VERSION ""

NS_ :

BS_:

BU_: Vector__XXX

BO_ 2364624894 ECCP11: 8 Vector__XXX
SG_ EngineCylinder11Timing1Pressure : 0|16@1+ (0.0009765625,0) [0|62.74902344] "MPa" Vector__XXX
SG_ EngineCylinder11Timing2Pressure : 16|16@1+ (0.0009765625,0) [0|62.74902344] "MPa" Vector__XXX
SG_ EngineCylinder11Timing3Pressure : 32|16@1+ (0.0009765625,0) [0|62.74902344] "MPa" Vector__XXX
SG_ EngineCylinder11Timing4Pressure : 48|16@1+ (0.0009765625,0) [0|62.74902344] "MPa" Vector__XXX

BO_ 2364625150 ECCP12: 8 Vector__XXX
SG_ EngineCylinder12Timing1Pressure : 0|16@1+ (0.0009765625,0) [0|62.74902344] "MPa" Vector__XXX
SG_ EngineCylinder12Timing2Pressure : 16|16@1+ (0.0009765625,0) [0|62.74902344] "MPa" Vector__XXX
SG_ EngineCylinder12Timing3Pressure : 32|16@1+ (0.0009765625,0) [0|62.74902344] "MPa" Vector__XXX
SG_ EngineCylinder12Timing4Pressure : 48|16@1+ (0.0009765625,0) [0|62.74902344] "MPa" Vector__XXX

BO_ 2364625406 ECCP13: 8 Vector__XXX
SG_ EngineCylinder13Timing1Pressure : 0|16@1+ (0.0009765625,0) [0|62.74902344] "MPa" Vector__XXX
SG_ EngineCylinder13Timing2Pressure : 16|16@1+ (0.0009765625,0) [0|62.74902344] "MPa" Vector__XXX
SG_ EngineCylinder13Timing3Pressure : 32|16@1+ (0.0009765625,0) [0|62.74902344] "MPa" Vector__XXX
SG_ EngineCylinder13Timing4Pressure : 48|16@1+ (0.0009765625,0) [0|62.74902344] "MPa" Vector__XXX

BO_ 2364625662 ECCP14: 8 Vector__XXX
SG_ EngineCylinder14Timing1Pressure : 0|16@1+ (0.0009765625,0) [0|62.74902344] "MPa" Vector__XXX
SG_ EngineCylinder14Timing2Pressure : 16|16@1+ (0.0009765625,0) [0|62.74902344] "MPa" Vector__XXX
SG_ EngineCylinder14Timing3Pressure : 32|16@1+ (0.0009765625,0) [0|62.74902344] "MPa" Vector__XXX
SG_ EngineCylinder14Timing4Pressure : 48|16@1+ (0.0009765625,0) [0|62.74902344] "MPa" Vector__XXX

BO_ 2364625918 ECCP15: 8 Vector__XXX
SG_ EngineCylinder15Timing1Pressure : 0|16@1+ (0.0009765625,0) [0|62.74902344] "MPa" Vector__XXX
SG_ EngineCylinder15Timing2Pressure : 16|16@1+ (0.0009765625,0) [0|62.74902344] "MPa" Vector__XXX
SG_ EngineCylinder15Timing3Pressure : 32|16@1+ (0.0009765625,0) [0|62.74902344] "MPa" Vector__XXX
SG_ EngineCylinder15Timing4Pressure : 48|16@1+ (0.0009765625,0) [0|62.74902344] "MPa" Vector__XXX

BO_ 2364626174 ECCP16: 8 Vector__XXX
SG_ EngineCylinder16Timing1Pressure : 0|16@1+ (0.0009765625,0) [0|62.74902344] "MPa" Vector__XXX
SG_ EngineCylinder16Timing2Pressure : 16|16@1+ (0.0009765625,0) [0|62.74902344] "MPa" Vector__XXX
SG_ EngineCylinder16Timing3Pressure : 32|16@1+ (0.0009765625,0) [0|62.74902344] "MPa" Vector__XXX
SG_ EngineCylinder16Timing4Pressure : 48|16@1+ (0.0009765625,0) [0|62.74902344] "MPa" Vector__XXX

BO_ 2364626430 ECCP17: 8 Vector__XXX
SG_ EngineCylinder17Timing1Pressure : 0|16@1+ (0.0009765625,0) [0|62.74902344] "MPa" Vector__XXX
SG_ EngineCylinder17Timing2Pressure : 16|16@1+ (0.0009765625,0) [0|62.74902344] "MPa" Vector__XXX
SG_ EngineCylinder17Timing3Pressure : 32|16@1+ (0.0009765625,0) [0|62.74902344] "MPa" Vector__XXX
SG_ EngineCylinder17Timing4Pressure : 48|16@1+ (0.0009765625,0) [0|62.74902344] "MPa" Vector__XXX

BO_ 2364626686 ECCP18: 8 Vector__XXX
SG_ EngineCylinder18Timing1Pressure : 0|16@1+ (0.0009765625,0) [0|62.74902344] "MPa" Vector__XXX
SG_ EngineCylinder18Timing2Pressure : 16|16@1+ (0.0009765625,0) [0|62.74902344] "MPa" Vector__XXX
SG_ EngineCylinder18Timing3Pressure : 32|16@1+ (0.0009765625,0) [0|62.74902344] "MPa" Vector__XXX
SG_ EngineCylinder18Timing4Pressure : 48|16@1+ (0.0009765625,0) [0|62.74902344] "MPa" Vector__XXX

BO_ 2364626942 ECCP19: 8 Vector__XXX
SG_ EngineCylinder19Timing1Pressure : 0|16@1+ (0.0009765625,0) [0|62.74902344] "MPa" Vector__XXX
SG_ EngineCylinder19Timing2Pressure : 16|16@1+ (0.0009765625,0) [0|62.74902344] "MPa" Vector__XXX
SG_ EngineCylinder19Timing3Pressure : 32|16@1+ (0.0009765625,0) [0|62.74902344] "MPa" Vector__XXX
SG_ EngineCylinder19Timing4Pressure : 48|16@1+ (0.0009765625,0) [0|62.74902344] "MPa" Vector__XXX

BO_ 2364627198 ECCP20: 8 Vector__XXX
SG_ EngineCylinder20Timing1Pressure : 0|16@1+ (0.0009765625,0) [0|62.74902344] "MPa" Vector__XXX
SG_ EngineCylinder20Timing2Pressure : 16|16@1+ (0.0009765625,0) [0|62.74902344] "MPa" Vector__XXX
SG_ EngineCylinder20Timing3Pressure : 32|16@1+ (0.0009765625,0) [0|62.74902344] "MPa" Vector__XXX
SG_ EngineCylinder20Timing4Pressure : 48|16@1+ (0.0009765625,0) [0|62.74902344] "MPa" Vector__XXX

BO_ 2364627454 ECCT1: 8 Vector__XXX
SG_ EngCyl1InstntnsStrtCombstnTiming : 0|16@1+ (0.00390625,-125) [-125|125] "deg" Vector__XXX
SG_ EngCyl1InstntnsCntrCombstnTiming : 16|16@1+ (0.00390625,-125) [-125|125] "deg" Vector__XXX
SG_ EngCyl1InstntnsCombstnTmng_Pnt1 : 32|16@1+ (0.00390625,-125) [-125|125] "deg" Vector__XXX
SG_ EngCyl1InstntnsCombstnTmng_Pnt2 : 48|16@1+ (0.00390625,-125) [-125|125] "deg" Vector__XXX

BO_ 2364627710 ECCT2: 8 Vector__XXX
SG_ EngCyl2InstntnsStrtCombstnTiming : 0|16@1+ (0.00390625,-125) [-125|125] "deg" Vector__XXX
SG_ EngCyl2InstntnsCntrCombstnTiming : 16|16@1+ (0.00390625,-125) [-125|125] "deg" Vector__XXX
SG_ EngCyl2InstntnsCombstnTmng_Pnt1 : 32|16@1+ (0.00390625,-125) [-125|125] "deg" Vector__XXX
SG_ EngCyl2InstntnsCombstnTmng_Pnt2 : 48|16@1+ (0.00390625,-125) [-125|125] "deg" Vector__XXX

BO_ 2364627966 ECCT3: 8 Vector__XXX
SG_ EngCyl3InstntnsStrtCombstnTiming : 0|16@1+ (0.00390625,-125) [-125|125] "deg" Vector__XXX
SG_ EngCyl3InstntnsCntrCombstnTiming : 16|16@1+ (0.00390625,-125) [-125|125] "deg" Vector__XXX
SG_ EngCyl3InstntnsCombstnTmng_Pnt1 : 32|16@1+ (0.00390625,-125) [-125|125] "deg" Vector__XXX
SG_ EngCyl3InstntnsCombstnTmng_Pnt2 : 48|16@1+ (0.00390625,-125) [-125|125] "deg" Vector__XXX

BO_ 2364628222 ECCT4: 8 Vector__XXX
SG_ EngCyl4InstntnsStrtCombstnTiming : 0|16@1+ (0.00390625,-125) [-125|125] "deg" Vector__XXX
SG_ EngCyl4InstntnsCntrCombstnTiming : 16|16@1+ (0.00390625,-125) [-125|125] "deg" Vector__XXX
SG_ EngCyl4InstntnsCombstnTmng_Pnt1 : 32|16@1+ (0.00390625,-125) [-125|125] "deg" Vector__XXX
SG_ EngCyl4InstntnsCombstnTmng_Pnt2 : 48|16@1+ (0.00390625,-125) [-125|125] "deg" Vector__XXX

BO_ 2364628478 ECCT5: 8 Vector__XXX
SG_ EngCyl5InstntnsStrtCombstnTiming : 0|16@1+ (0.00390625,-125) [-125|125] "deg" Vector__XXX
SG_ EngCyl5InstntnsCntrCombstnTiming : 16|16@1+ (0.00390625,-125) [-125|125] "deg" Vector__XXX
SG_ EngCyl5InstntnsCombstnTmng_Pnt1 : 32|16@1+ (0.00390625,-125) [-125|125] "deg" Vector__XXX
SG_ EngCyl5InstntnsCombstnTmng_Pnt2 : 48|16@1+ (0.00390625,-125) [-125|125] "deg" Vector__XXX

BO_ 2364628734 ECCT6: 8 Vector__XXX
SG_ EngCyl6InstntnsStrtCombstnTiming : 0|16@1+ (0.00390625,-125) [-125|125] "deg" Vector__XXX
SG_ EngCyl6InstntnsCntrCombstnTiming : 16|16@1+ (0.00390625,-125) [-125|125] "deg" Vector__XXX
SG_ EngCyl6InstntnsCombstnTmng_Pnt1 : 32|16@1+ (0.00390625,-125) [-125|125] "deg" Vector__XXX
SG_ EngCyl6InstntnsCombstnTmng_Pnt2 : 48|16@1+ (0.00390625,-125) [-125|125] "deg" Vector__XXX

BO_ 2364628990 ECCT7: 8 Vector__XXX
SG_ EngCyl7InstntnsStrtCombstnTiming : 0|16@1+ (0.00390625,-125) [-125|125] "deg" Vector__XXX
SG_ EngCyl7InstntnsCntrCombstnTiming : 16|16@1+ (0.00390625,-125) [-125|125] "deg" Vector__XXX
SG_ EngCyl7InstntnsCombstnTmng_Pnt1 : 32|16@1+ (0.00390625,-125) [-125|125] "deg" Vector__XXX
SG_ EngCyl7InstntnsCombstnTmng_Pnt2 : 48|16@1+ (0.00390625,-125) [-125|125] "deg" Vector__XXX

BO_ 2364629246 ECCT8: 8 Vector__XXX
SG_ EngCyl8InstntnsStrtCombstnTiming : 0|16@1+ (0.00390625,-125) [-125|125] "deg" Vector__XXX
SG_ EngCyl8InstntnsCntrCombstnTiming : 16|16@1+ (0.00390625,-125) [-125|125] "deg" Vector__XXX
SG_ EngCyl8InstntnsCombstnTmng_Pnt1 : 32|16@1+ (0.00390625,-125) [-125|125] "deg" Vector__XXX
SG_ EngCyl8InstntnsCombstnTmng_Pnt2 : 48|16@1+ (0.00390625,-125) [-125|125] "deg" Vector__XXX

BO_ 2364629502 ECCT9: 8 Vector__XXX
SG_ EngCyl9InstntnsStrtCombstnTiming : 0|16@1+ (0.00390625,-125) [-125|125] "deg" Vector__XXX
SG_ EngCyl9InstntnsCntrCombstnTiming : 16|16@1+ (0.00390625,-125) [-125|125] "deg" Vector__XXX
SG_ EngCyl9InstntnsCombstnTmng_Pnt1 : 32|16@1+ (0.00390625,-125) [-125|125] "deg" Vector__XXX
SG_ EngCyl9InstntnsCombstnTmng_Pnt2 : 48|16@1+ (0.00390625,-125) [-125|125] "deg" Vector__XXX

BO_ 2364629758 ECCT10: 8 Vector__XXX
SG_ EngCyl10InstntnsStrtCombstnTmng : 0|16@1+ (0.00390625,-125) [-125|125] "deg" Vector__XXX
SG_ EngCyl10InstntnsCntrCombstnTmng : 16|16@1+ (0.00390625,-125) [-125|125] "deg" Vector__XXX
SG_ EngCyl10InstntnsCombstnTmng_Pnt1 : 32|16@1+ (0.00390625,-125) [-125|125] "deg" Vector__XXX
SG_ EngCyl10InstntnsCombstnTmng_Pnt2 : 48|16@1+ (0.00390625,-125) [-125|125] "deg" Vector__XXX

BO_ 2364630014 ECCT11: 8 Vector__XXX
SG_ EngCyl11InstntnsStrtCombstnTmng : 0|16@1+ (0.00390625,-125) [-125|125] "deg" Vector__XXX
SG_ EngCyl11InstntnsCntrCombstnTmng : 16|16@1+ (0.00390625,-125) [-125|125] "deg" Vector__XXX
SG_ EngCyl11InstntnsCombstnTmng_Pnt1 : 32|16@1+ (0.00390625,-125) [-125|125] "deg" Vector__XXX
SG_ EngCyl11InstntnsCombstnTmng_Pnt2 : 48|16@1+ (0.00390625,-125) [-125|125] "deg" Vector__XXX

BO_ 2364630270 ECCT12: 8 Vector__XXX
SG_ EngCyl12InstntnsStrtCombstnTmng : 0|16@1+ (0.00390625,-125) [-125|125] "deg" Vector__XXX
SG_ EngCyl12InstntnsCntrCombstnTmng : 16|16@1+ (0.00390625,-125) [-125|125] "deg" Vector__XXX
SG_ EngCyl12InstntnsCombstnTmng_Pnt1 : 32|16@1+ (0.00390625,-125) [-125|125] "deg" Vector__XXX
SG_ EngCyl12InstntnsCombstnTmng_Pnt2 : 48|16@1+ (0.00390625,-125) [-125|125] "deg" Vector__XXX

BO_ 2364630526 ECCT13: 8 Vector__XXX
SG_ EngCyl13InstntnsStrtCombstnTmng : 0|16@1+ (0.00390625,-125) [-125|125] "deg" Vector__XXX
SG_ EngCyl13InstntnsCntrCombstnTmng : 16|16@1+ (0.00390625,-125) [-125|125] "deg" Vector__XXX
SG_ EngCyl13InstntnsCombstnTmng_Pnt1 : 32|16@1+ (0.00390625,-125) [-125|125] "deg" Vector__XXX
SG_ EngCyl13InstntnsCombstnTmng_Pnt2 : 48|16@1+ (0.00390625,-125) [-125|125] "deg" Vector__XXX

BO_ 2364630782 ECCT14: 8 Vector__XXX
SG_ EngCyl14InstntnsStrtCombstnTmng : 0|16@1+ (0.00390625,-125) [-125|125] "deg" Vector__XXX
SG_ EngCyl14InstntnsCntrCombstnTmng : 16|16@1+ (0.00390625,-125) [-125|125] "deg" Vector__XXX
SG_ EngCyl14InstntnsCombstnTmng_Pnt1 : 32|16@1+ (0.00390625,-125) [-125|125] "deg" Vector__XXX
SG_ EngCyl14InstntnsCombstnTmng_Pnt2 : 48|16@1+ (0.00390625,-125) [-125|125] "deg" Vector__XXX

BO_ 2364631038 ECCT15: 8 Vector__XXX
SG_ EngCyl15InstntnsStrtCombstnTmng : 0|16@1+ (0.00390625,-125) [-125|125] "deg" Vector__XXX
SG_ EngCyl15InstntnsCntrCombstnTmng : 16|16@1+ (0.00390625,-125) [-125|125] "deg" Vector__XXX
SG_ EngCyl15InstntnsCombstnTmng_Pnt1 : 32|16@1+ (0.00390625,-125) [-125|125] "deg" Vector__XXX
SG_ EngCyl15InstntnsCombstnTmng_Pnt2 : 48|16@1+ (0.00390625,-125) [-125|125] "deg" Vector__XXX

BO_ 2364631294 ECCT16: 8 Vector__XXX
SG_ EngCyl16InstntnsStrtCombstnTmng : 0|16@1+ (0.00390625,-125) [-125|125] "deg" Vector__XXX
SG_ EngCyl16InstntnsCntrCombstnTmng : 16|16@1+ (0.00390625,-125) [-125|125] "deg" Vector__XXX
SG_ EngCyl16InstntnsCombstnTmng_Pnt1 : 32|16@1+ (0.00390625,-125) [-125|125] "deg" Vector__XXX
SG_ EngCyl16InstntnsCombstnTmng_Pnt2 : 48|16@1+ (0.00390625,-125) [-125|125] "deg" Vector__XXX

BO_ 2364631550 ECCT17: 8 Vector__XXX
SG_ EngCyl17InstntnsStrtCombstnTmng : 0|16@1+ (0.00390625,-125) [-125|125] "deg" Vector__XXX
SG_ EngCyl17InstntnsCntrCombstnTmng : 16|16@1+ (0.00390625,-125) [-125|125] "deg" Vector__XXX
SG_ EngCyl17InstntnsCombstnTmng_Pnt1 : 32|16@1+ (0.00390625,-125) [-125|125] "deg" Vector__XXX
SG_ EngCyl17InstntnsCombstnTmng_Pnt2 : 48|16@1+ (0.00390625,-125) [-125|125] "deg" Vector__XXX

BO_ 2364631806 ECCT18: 8 Vector__XXX
SG_ EngCyl18InstntnsStrtCombstnTmng : 0|16@1+ (0.00390625,-125) [-125|125] "deg" Vector__XXX
SG_ EngCyl18InstntnsCntrCombstnTmng : 16|16@1+ (0.00390625,-125) [-125|125] "deg" Vector__XXX
SG_ EngCyl18InstntnsCombstnTmng_Pnt1 : 32|16@1+ (0.00390625,-125) [-125|125] "deg" Vector__XXX
SG_ EngCyl18InstntnsCombstnTmng_Pnt2 : 48|16@1+ (0.00390625,-125) [-125|125] "deg" Vector__XXX

BO_ 2364632062 ECCT19: 8 Vector__XXX
SG_ EngCyl19InstntnsStrtCombstnTmng : 0|16@1+ (0.00390625,-125) [-125|125] "deg" Vector__XXX
SG_ EngCyl19InstntnsCntrCombstnTmng : 16|16@1+ (0.00390625,-125) [-125|125] "deg" Vector__XXX
SG_ EngCyl19InstntnsCombstnTmng_Pnt1 : 32|16@1+ (0.00390625,-125) [-125|125] "deg" Vector__XXX
SG_ EngCyl19InstntnsCombstnTmng_Pnt2 : 48|16@1+ (0.00390625,-125) [-125|125] "deg" Vector__XXX

BO_ 2364632318 ECCT20: 8 Vector__XXX
SG_ EngCyl20InstntnsStrtCombstnTmng : 0|16@1+ (0.00390625,-125) [-125|125] "deg" Vector__XXX
SG_ EngCyl20InstntnsCntrCombstnTmng : 16|16@1+ (0.00390625,-125) [-125|125] "deg" Vector__XXX
SG_ EngCyl20InstntnsCombstnTmng_Pnt1 : 32|16@1+ (0.00390625,-125) [-125|125] "deg" Vector__XXX
SG_ EngCyl20InstntnsCombstnTmng_Pnt2 : 48|16@1+ (0.00390625,-125) [-125|125] "deg" Vector__XXX

BO_ 2364632574 EECM1: 8 Vector__XXX
SG_ EngCyl1InstntnsPeakCombPressTmng : 0|16@1+ (0.00390625,-125) [-125|125] "deg" Vector__XXX
SG_ EngCyl1InstntnsIndctMnEffctPress : 16|16@1+ (0.0001220703125,-1) [-1|6.84362793] "MPa" Vector__XXX
SG_ EngCyl1IndctMnEffctPrsCoeffVarnc : 32|8@1+ (0.04,0) [0|10] "%" Vector__XXX
SG_ EngineCylinder1MisfireRate : 40|8@1+ (0.4,0) [0|100] "%" Vector__XXX
SG_ EngineCylinder1Temperature : 48|16@1+ (0.03125,-273) [-273|1734.96875] "deg C" Vector__XXX

BO_ 2364632830 EECM2: 8 Vector__XXX
SG_ EngCyl2InstntnsPeakCombPressTmng : 0|16@1+ (0.00390625,-125) [-125|125] "deg" Vector__XXX
SG_ EngCyl2InstntnsIndctMnEffctPress : 16|16@1+ (0.0001220703125,-1) [-1|6.84362793] "MPa" Vector__XXX
SG_ EngCyl2IndctMnEffctPrsCoeffVarnc : 32|8@1+ (0.04,0) [0|10] "%" Vector__XXX
SG_ EngineCylinder2MisfireRate : 40|8@1+ (0.4,0) [0|100] "%" Vector__XXX
SG_ EngineCylinder2Temperature : 48|16@1+ (0.03125,-273) [-273|1734.96875] "deg C" Vector__XXX

BO_ 2364633086 EECM3: 8 Vector__XXX
SG_ EngCyl3InstntnsPeakCombPressTmng : 0|16@1+ (0.00390625,-125) [-125|125] "deg" Vector__XXX
SG_ EngCyl3InstntnsIndctMnEffctPress : 16|16@1+ (0.0001220703125,-1) [-1|6.84362793] "MPa" Vector__XXX
SG_ EngCyl3IndctMnEffctPrsCoeffVarnc : 32|8@1+ (0.04,0) [0|10] "%" Vector__XXX
SG_ EngineCylinder3MisfireRate : 40|8@1+ (0.4,0) [0|100] "%" Vector__XXX
SG_ EngineCylinder3Temperature : 48|16@1+ (0.03125,-273) [-273|1734.96875] "deg C" Vector__XXX

BO_ 2364633342 EECM4: 8 Vector__XXX
SG_ EngCyl4InstntnsPeakCombPressTmng : 0|16@1+ (0.00390625,-125) [-125|125] "deg" Vector__XXX
SG_ EngCyl4InstntnsIndctMnEffctPress : 16|16@1+ (0.0001220703125,-1) [-1|6.84362793] "MPa" Vector__XXX
SG_ EngCyl4IndctMnEffctPrsCoeffVarnc : 32|8@1+ (0.04,0) [0|10] "%" Vector__XXX
SG_ EngineCylinder4MisfireRate : 40|8@1+ (0.4,0) [0|100] "%" Vector__XXX
SG_ EngineCylinder4Temperature : 48|16@1+ (0.03125,-273) [-273|1734.96875] "deg C" Vector__XXX

BO_ 2364633598 EECM5: 8 Vector__XXX
SG_ EngCyl5InstntnsPeakCombPressTmng : 0|16@1+ (0.00390625,-125) [-125|125] "deg" Vector__XXX
SG_ EngCyl5InstntnsIndctMnEffctPress : 16|16@1+ (0.0001220703125,-1) [-1|6.84362793] "MPa" Vector__XXX
SG_ EngCyl5IndctMnEffctPrsCoeffVarnc : 32|8@1+ (0.04,0) [0|10] "%" Vector__XXX
SG_ EngineCylinder5MisfireRate : 40|8@1+ (0.4,0) [0|100] "%" Vector__XXX
SG_ EngineCylinder5Temperature : 48|16@1+ (0.03125,-273) [-273|1734.96875] "deg C" Vector__XXX

BO_ 2364633854 EECM6: 8 Vector__XXX
SG_ EngCyl6InstntnsPeakCombPressTmng : 0|16@1+ (0.00390625,-125) [-125|125] "deg" Vector__XXX
SG_ EngCyl6InstntnsIndctMnEffctPress : 16|16@1+ (0.0001220703125,-1) [-1|6.84362793] "MPa" Vector__XXX
SG_ EngCyl6IndctMnEffctPrsCoeffVarnc : 32|8@1+ (0.04,0) [0|10] "%" Vector__XXX
SG_ EngineCylinder6MisfireRate : 40|8@1+ (0.4,0) [0|100] "%" Vector__XXX
SG_ EngineCylinder6Temperature : 48|16@1+ (0.03125,-273) [-273|1734.96875] "deg C" Vector__XXX

BO_ 2364634110 EECM7: 8 Vector__XXX
SG_ EngCyl7InstntnsPeakCombPressTmng : 0|16@1+ (0.00390625,-125) [-125|125] "deg" Vector__XXX
SG_ EngCyl7InstntnsIndctMnEffctPress : 16|16@1+ (0.0001220703125,-1) [-1|6.84362793] "MPa" Vector__XXX
SG_ EngCyl7IndctMnEffctPrsCoeffVarnc : 32|8@1+ (0.04,0) [0|10] "%" Vector__XXX
SG_ EngineCylinder7MisfireRate : 40|8@1+ (0.4,0) [0|100] "%" Vector__XXX
SG_ EngineCylinder7Temperature : 48|16@1+ (0.03125,-273) [-273|1734.96875] "deg C" Vector__XXX

BO_ 2364634366 EECM8: 8 Vector__XXX
SG_ EngCyl8InstntnsPeakCombPressTmng : 0|16@1+ (0.00390625,-125) [-125|125] "deg" Vector__XXX
SG_ EngCyl8InstntnsIndctMnEffctPress : 16|16@1+ (0.0001220703125,-1) [-1|6.84362793] "MPa" Vector__XXX
SG_ EngCyl8IndctMnEffctPrsCoeffVarnc : 32|8@1+ (0.04,0) [0|10] "%" Vector__XXX
SG_ EngineCylinder8MisfireRate : 40|8@1+ (0.4,0) [0|100] "%" Vector__XXX
SG_ EngineCylinder8Temperature : 48|16@1+ (0.03125,-273) [-273|1734.96875] "deg C" Vector__XXX

BO_ 2364634622 EECM9: 8 Vector__XXX
SG_ EngCyl9InstntnsPeakCombPressTmng : 0|16@1+ (0.00390625,-125) [-125|125] "deg" Vector__XXX
SG_ EngCyl9InstntnsIndctMnEffctPress : 16|16@1+ (0.0001220703125,-1) [-1|6.84362793] "MPa" Vector__XXX
SG_ EngCyl9IndctMnEffctPrsCoeffVarnc : 32|8@1+ (0.04,0) [0|10] "%" Vector__XXX
SG_ EngineCylinder9MisfireRate : 40|8@1+ (0.4,0) [0|100] "%" Vector__XXX
SG_ EngineCylinder9Temperature : 48|16@1+ (1,-273) [-273|1734.96875] "deg C" Vector__XXX

BO_ 2364634878 EECM10: 8 Vector__XXX
SG_ EngCyl10InstPeakCombPressTmng : 0|16@1+ (0.00390625,-125) [-125|125] "deg" Vector__XXX
SG_ EngCyl10InstIndctMnEffctPress : 16|16@1+ (0.0001220703125,-1) [-1|6.84362793] "MPa" Vector__XXX
SG_ EngCyl10IndctMnEffctPrsCoeffVar : 32|8@1+ (0.04,0) [0|10] "%" Vector__XXX
SG_ EngineCylinder10MisfireRate : 40|8@1+ (0.4,0) [0|100] "%" Vector__XXX
SG_ EngineCylinder10Temperature : 48|16@1+ (0.03125,-273) [-273|1734.96875] "deg C" Vector__XXX

BO_ 2364635134 EECM11: 8 Vector__XXX
SG_ EngCyl11InstPeakCombPressTmng : 0|16@1+ (0.00390625,-125) [-125|125] "deg" Vector__XXX
SG_ EngCyl11InstIndctMnEffctPress : 16|16@1+ (0.0001220703125,-1) [-1|6.84362793] "MPa" Vector__XXX
SG_ EngCyl11IndctMnEffctPrsCoeffVar : 32|8@1+ (0.04,0) [0|10] "%" Vector__XXX
SG_ EngineCylinder11MisfireRate : 40|8@1+ (0.4,0) [0|100] "%" Vector__XXX
SG_ EngineCylinder11Temperature : 48|16@1+ (0.03125,-273) [-273|1734.96875] "deg C" Vector__XXX

BO_ 2364635390 EECM12: 8 Vector__XXX
SG_ EngCyl12InstPeakCombPressTmng : 0|16@1+ (0.00390625,-125) [-125|125] "deg" Vector__XXX
SG_ EngCyl12InstIndctMnEffctPress : 16|16@1+ (0.0001220703125,-1) [-1|6.84362793] "MPa" Vector__XXX
SG_ EngCyl12IndctMnEffctPrsCoeffVar : 32|8@1+ (0.04,0) [0|10] "%" Vector__XXX
SG_ EngineCylinder12MisfireRate : 40|8@1+ (0.4,0) [0|100] "%" Vector__XXX
SG_ EngineCylinder12Temperature : 48|16@1+ (0.03125,-273) [-273|1734.96875] "deg C" Vector__XXX

BO_ 2364635646 EECM13: 8 Vector__XXX
SG_ EngCyl13InstPeakCombPressTmng : 0|16@1+ (0.00390625,-125) [-125|125] "deg" Vector__XXX
SG_ EngCyl13InstIndctMnEffctPress : 16|16@1+ (0.0001220703125,-1) [-1|6.84362793] "MPa" Vector__XXX
SG_ EngCyl13IndctMnEffctPrsCoeffVar : 32|8@1+ (0.04,0) [0|10] "%" Vector__XXX
SG_ EngineCylinder13MisfireRate : 40|8@1+ (0.4,0) [0|100] "%" Vector__XXX
SG_ EngineCylinder13Temperature : 48|16@1+ (0.03125,-273) [-273|1734.96875] "deg C" Vector__XXX

BO_ 2364635902 EECM14: 8 Vector__XXX
SG_ EngCyl14InstPeakCombPressTmng : 0|16@1+ (0.00390625,-125) [-125|125] "deg" Vector__XXX
SG_ EngCyl14InstIndctMnEffctPress : 16|16@1+ (0.0001220703125,-1) [-1|6.84362793] "MPa" Vector__XXX
SG_ EngCyl14IndctMnEffctPrsCoeffVar : 32|8@1+ (0.04,0) [0|10] "%" Vector__XXX
SG_ EngineCylinder14MisfireRate : 40|8@1+ (0.4,0) [0|100] "%" Vector__XXX
SG_ EngineCylinder14Temperature : 48|16@1+ (1,-273) [-273|1734.96875] "deg C" Vector__XXX

BO_ 2364636158 EECM15: 8 Vector__XXX
SG_ EngCyl15InstPeakCombPressTmng : 0|16@1+ (0.00390625,-125) [-125|125] "deg" Vector__XXX
SG_ EngCyl15InstIndctMnEffctPress : 16|16@1+ (0.0001220703125,-1) [-1|6.84362793] "MPa" Vector__XXX
SG_ EngCyl15IndctMnEffctPrsCoeffVar : 32|8@1+ (0.04,0) [0|10] "%" Vector__XXX
SG_ EngineCylinder15MisfireRate : 40|8@1+ (0.4,0) [0|100] "%" Vector__XXX
SG_ EngineCylinder15Temperature : 48|16@1+ (0.03125,-273) [-273|1734.96875] "deg C" Vector__XXX

BO_ 2364636414 EECM16: 8 Vector__XXX
SG_ EngCyl16InstPeakCombPressTmng : 0|16@1+ (0.00390625,-125) [-125|125] "deg" Vector__XXX
SG_ EngCyl16InstIndctMnEffctPress : 16|16@1+ (0.0001220703125,-1) [-1|6.84362793] "MPa" Vector__XXX
SG_ EngCyl16IndctMnEffctPrsCoeffVar : 32|8@1+ (0.04,0) [0|10] "%" Vector__XXX
SG_ EngineCylinder16MisfireRate : 40|8@1+ (0.4,0) [0|100] "%" Vector__XXX
SG_ EngineCylinder16Temperature : 48|16@1+ (0.03125,-273) [-273|1734.96875] "deg C" Vector__XXX

BO_ 2364636670 EECM17: 8 Vector__XXX
SG_ EngCyl17InstPeakCombPressTmng : 0|16@1+ (0.00390625,-125) [-125|125] "deg" Vector__XXX
SG_ EngCyl17InstIndctMnEffctPress : 16|16@1+ (0.0001220703125,-1) [-1|6.84362793] "MPa" Vector__XXX
SG_ EngCyl17IndctMnEffctPrsCoeffVar : 32|8@1+ (0.04,0) [0|10] "%" Vector__XXX
SG_ EngineCylinder17MisfireRate : 40|8@1+ (0.4,0) [0|100] "%" Vector__XXX
SG_ EngineCylinder17Temperature : 48|16@1+ (0.03125,-273) [-273|1734.96875] "deg C" Vector__XXX

BO_ 2364636926 EECM18: 8 Vector__XXX
SG_ EngCyl18InstPeakCombPressTmng : 0|16@1+ (0.00390625,-125) [-125|125] "deg" Vector__XXX
SG_ EngCyl18InstIndctMnEffctPress : 16|16@1+ (0.0001220703125,-1) [-1|6.84362793] "MPa" Vector__XXX
SG_ EngCyl18IndctMnEffctPrsCoeffVar : 32|8@1+ (0.04,0) [0|10] "%" Vector__XXX
SG_ EngineCylinder18MisfireRate : 40|8@1+ (0.4,0) [0|100] "%" Vector__XXX
SG_ EngineCylinder18Temperature : 48|16@1+ (0.03125,-273) [-273|1734.96875] "deg C" Vector__XXX

BO_ 2364637182 EECM19: 8 Vector__XXX
SG_ EngCyl19InstPeakCombPressTmng : 0|16@1+ (0.00390625,-125) [-125|125] "deg" Vector__XXX
SG_ EngCyl19InstIndctMnEffctPress : 16|16@1+ (0.0001220703125,-1) [-1|6.84362793] "MPa" Vector__XXX
SG_ EngCyl19IndctMnEffctPrsCoeffVar : 32|8@1+ (0.04,0) [0|10] "%" Vector__XXX
SG_ EngineCylinder19MisfireRate : 40|8@1+ (0.4,0) [0|100] "%" Vector__XXX
SG_ EngineCylinder19Temperature : 48|16@1+ (0.03125,-273) [-273|1734.96875] "deg C" Vector__XXX

BO_ 2364637438 EECM20: 8 Vector__XXX
SG_ EngCyl20InstPeakCombPressTmng : 0|16@1+ (0.00390625,-125) [-125|125] "deg" Vector__XXX
SG_ EngCyl20InstIndctMnEffctPress : 16|16@1+ (0.0001220703125,-1) [-1|6.84362793] "MPa" Vector__XXX
SG_ EngCyl20IndctMnEffctPrsCoeffVar : 32|8@1+ (0.04,0) [0|10] "%" Vector__XXX
SG_ EngineCylinder20MisfireRate : 40|8@1+ (0.4,0) [0|100] "%" Vector__XXX
SG_ EngineCylinder20Temperature : 48|16@1+ (0.03125,-273) [-273|1734.96875] "deg C" Vector__XXX

BO_ 2364637694 MG1IMF1: 8 Vector__XXX
SG_ MotorGen1InverterModeFdbck1CRC : 0|8@1+ (1,0) [0|255] "" Vector__XXX
SG_ MotorGen1InverterModeFdbck1Cntr : 8|4@1+ (1,0) [0|15] "" Vector__XXX
SG_ MtrGen1InvertCtrlLmtsOverrideMde : 12|4@1+ (1,0) [0|15] "" Vector__XXX
SG_ MotorGen1InvertCtrlSetpointMode : 16|5@1+ (1,0) [0|31] "" Vector__XXX
SG_ MotorGen1InverterHVILStatus : 21|2@1+ (1,0) [0|3] "" Vector__XXX

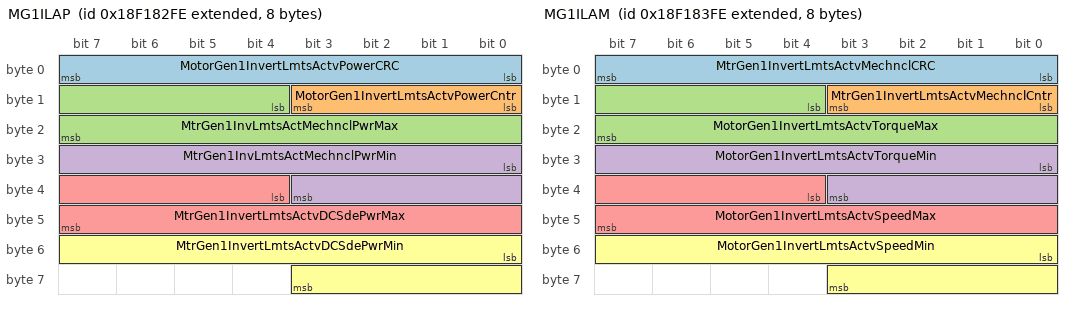
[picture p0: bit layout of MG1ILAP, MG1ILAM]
BO_ 2565964542 MG1ILAP: 8 Vector__XXX
SG_ MotorGen1InvertLmtsActvPowerCRC : 0|8@1+ (1,0) [0|255] "" Vector__XXX
SG_ MotorGen1InvertLmtsActvPowerCntr : 8|4@1+ (1,0) [0|15] "" Vector__XXX
SG_ MtrGen1InvLmtsActMechnclPwrMax : 12|12@1+ (0.0625,-125) [-125|125.9375] "%" Vector__XXX
SG_ MtrGen1InvLmtsActMechnclPwrMin : 24|12@1+ (0.0625,-125) [-125|125.9375] "%" Vector__XXX
SG_ MtrGen1InvertLmtsActvDCSdePwrMax : 36|12@1+ (0.0625,-125) [-125|125.9375] "%" Vector__XXX
SG_ MtrGen1InvertLmtsActvDCSdePwrMin : 48|12@1+ (0.0625,-125) [-125|125.9375] "%" Vector__XXX

BO_ 2565964798 MG1ILAM: 8 Vector__XXX
SG_ MtrGen1InvertLmtsActvMechnclCRC : 0|8@1+ (1,0) [0|255] "" Vector__XXX
SG_ MtrGen1InvertLmtsActvMechnclCntr : 8|4@1+ (1,0) [0|15] "" Vector__XXX
SG_ MotorGen1InvertLmtsActvTorqueMax : 12|12@1+ (0.0625,-125) [-125|125.9375] "%" Vector__XXX
SG_ MotorGen1InvertLmtsActvTorqueMin : 24|12@1+ (0.0625,-125) [-125|125.9375] "%" Vector__XXX
SG_ MotorGen1InvertLmtsActvSpeedMax : 36|12@1+ (0.0625,-125) [-125|125.9375] "%" Vector__XXX
SG_ MotorGen1InvertLmtsActvSpeedMin : 48|12@1+ (0.0625,-125) [-125|125.9375] "%" Vector__XXX

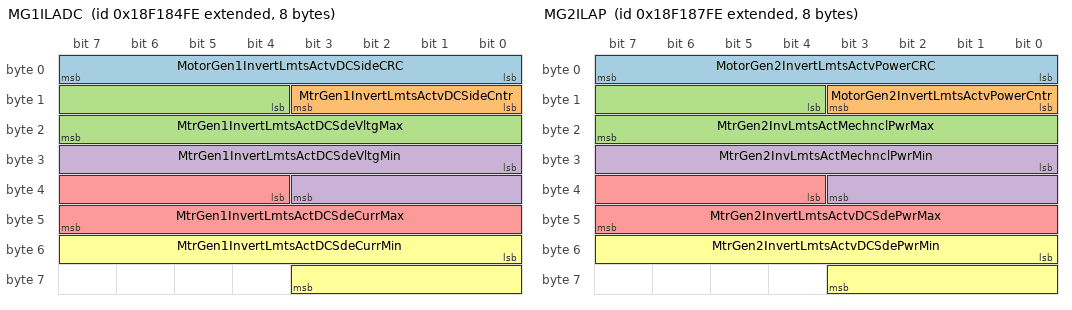
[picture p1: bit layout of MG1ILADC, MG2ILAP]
BO_ 2565965054 MG1ILADC: 8 Vector__XXX
SG_ MotorGen1InvertLmtsActvDCSideCRC : 0|8@1+ (1,0) [0|255] "" Vector__XXX
SG_ MtrGen1InvertLmtsActvDCSideCntr : 8|4@1+ (1,0) [0|15] "" Vector__XXX
SG_ MtrGen1InvertLmtsActDCSdeVltgMax : 12|12@1+ (0.0625,-125) [-125|125.9375] "%" Vector__XXX
SG_ MtrGen1InvertLmtsActDCSdeVltgMin : 24|12@1+ (0.0625,-125) [-125|125.9375] "%" Vector__XXX
SG_ MtrGen1InvertLmtsActDCSdeCurrMax : 36|12@1+ (0.0625,-125) [-125|125.9375] "%" Vector__XXX
SG_ MtrGen1InvertLmtsActDCSdeCurrMin : 48|12@1+ (0.0625,-125) [-125|125.9375] "%" Vector__XXX

BO_ 2565965310 MG1ILV: 8 Vector__XXX
SG_ MtrGen1InvertSwedIgnitionVoltage : 0|16@1+ (0.05,0) [0|3212.75] "V" Vector__XXX
SG_ MtrGen1InvertUnswitchedSLIVltg : 16|16@1+ (0.05,0) [0|3212.75] "V" Vector__XXX

BO_ 2364638974 MG2IMF1: 8 Vector__XXX
SG_ MotorGen2InverterModeFdbck1CRC : 0|8@1+ (1,0) [0|255] "" Vector__XXX
SG_ MotorGen2InverterModeFdbck1Cntr : 8|4@1+ (1,0) [0|15] "" Vector__XXX
SG_ MtrGen2InvertCtrlLmtsOverrideMde : 12|4@1+ (1,0) [0|15] "" Vector__XXX
SG_ MotorGen2InvertCtrlSetpointMode : 16|5@1+ (1,0) [0|31] "" Vector__XXX
SG_ MotorGen2InverterHVILStatus : 21|2@1+ (1,0) [0|3] "" Vector__XXX

BO_ 2565965822 MG2ILAP: 8 Vector__XXX
SG_ MotorGen2InvertLmtsActvPowerCRC : 0|8@1+ (1,0) [0|255] "" Vector__XXX
SG_ MotorGen2InvertLmtsActvPowerCntr : 8|4@1+ (1,0) [0|15] "" Vector__XXX
SG_ MtrGen2InvLmtsActMechnclPwrMax : 12|12@1+ (0.0625,-125) [-125|125.9375] "%" Vector__XXX
SG_ MtrGen2InvLmtsActMechnclPwrMin : 24|12@1+ (0.0625,-125) [-125|125.9375] "%" Vector__XXX
SG_ MtrGen2InvertLmtsActvDCSdePwrMax : 36|12@1+ (0.0625,-125) [-125|125.9375] "%" Vector__XXX
SG_ MtrGen2InvertLmtsActvDCSdePwrMin : 48|12@1+ (0.0625,-125) [-125|125.9375] "%" Vector__XXX

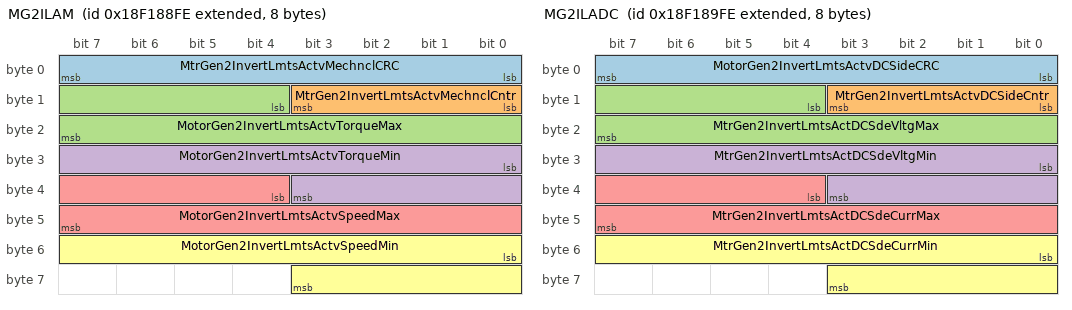
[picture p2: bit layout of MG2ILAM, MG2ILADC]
BO_ 2565966078 MG2ILAM: 8 Vector__XXX
SG_ MtrGen2InvertLmtsActvMechnclCRC : 0|8@1+ (1,0) [0|255] "" Vector__XXX
SG_ MtrGen2InvertLmtsActvMechnclCntr : 8|4@1+ (1,0) [0|15] "" Vector__XXX
SG_ MotorGen2InvertLmtsActvTorqueMax : 12|12@1+ (0.0625,-125) [-125|125.9375] "%" Vector__XXX
SG_ MotorGen2InvertLmtsActvTorqueMin : 24|12@1+ (0.0625,-125) [-125|125.9375] "%" Vector__XXX
SG_ MotorGen2InvertLmtsActvSpeedMax : 36|12@1+ (0.0625,-125) [-125|125.9375] "%" Vector__XXX
SG_ MotorGen2InvertLmtsActvSpeedMin : 48|12@1+ (0.0625,-125) [-125|125.9375] "%" Vector__XXX

BO_ 2565966334 MG2ILADC: 8 Vector__XXX
SG_ MotorGen2InvertLmtsActvDCSideCRC : 0|8@1+ (1,0) [0|255] "" Vector__XXX
SG_ MtrGen2InvertLmtsActvDCSideCntr : 8|4@1+ (1,0) [0|15] "" Vector__XXX
SG_ MtrGen2InvertLmtsActDCSdeVltgMax : 12|12@1+ (0.0625,-125) [-125|125.9375] "%" Vector__XXX
SG_ MtrGen2InvertLmtsActDCSdeVltgMin : 24|12@1+ (0.0625,-125) [-125|125.9375] "%" Vector__XXX
SG_ MtrGen2InvertLmtsActDCSdeCurrMax : 36|12@1+ (0.0625,-125) [-125|125.9375] "%" Vector__XXX
SG_ MtrGen2InvertLmtsActDCSdeCurrMin : 48|12@1+ (0.0625,-125) [-125|125.9375] "%" Vector__XXX

BO_ 2565966590 MG2ILV: 8 Vector__XXX
SG_ MtrGen2InvertSwedIgnitionVoltage : 0|16@1+ (0.05,0) [0|3212.75] "V" Vector__XXX
SG_ MtrGen2InvertUnswitchedSLIVltg : 16|16@1+ (0.05,0) [0|3212.75] "V" Vector__XXX

BO_ 2565966846 MG1IS2: 8 Vector__XXX
SG_ MotorGen1InverterStatus2CRC : 0|8@1+ (1,0) [0|255] "" Vector__XXX
SG_ MotorGen1InverterStatus2Cntr : 8|4@1+ (1,0) [0|15] "" Vector__XXX
SG_ MotorGen1AvailMaximumTorque : 12|12@1+ (0.0625,-125) [-125|125.9375] "%" Vector__XXX
SG_ MotorGen1AvailMinimumTorque : 24|12@1+ (0.0625,-125) [-125|125.9375] "%" Vector__XXX

BO_ 2565967102 MG1IRLA1: 8 Vector__XXX
SG_ MotorGen1InvertRateLmtsActv1CRC : 0|8@1+ (1,0) [0|255] "" Vector__XXX
SG_ MotorGen1InvertRateLmtsActv1Cntr : 8|4@1+ (1,0) [0|15] "" Vector__XXX
SG_ MtrGen1InvRatLmtsActAbsSpdRatLmt : 12|12@1+ (0.25,0) [0|1003.75] "%/s" Vector__XXX
SG_ MtrGen1InvRatLmtsActAbsTrqRatLmt : 24|12@1+ (2,0) [0|8030] "%/s" Vector__XXX

BO_ 2565967358 MG2IS2: 8 Vector__XXX
SG_ MotorGen2InverterStatus2CRC : 0|8@1+ (1,0) [0|255] "" Vector__XXX
SG_ MotorGen2InverterStatus2Cntr : 8|4@1+ (1,0) [0|15] "" Vector__XXX
SG_ MotorGen2AvailMaximumTorque : 12|12@1+ (0.0625,-125) [-125|125.9375] "%" Vector__XXX
SG_ MotorGen2AvailMinimumTorque : 24|12@1+ (0.0625,-125) [-125|125.9375] "%" Vector__XXX

BO_ 2565967614 MG2IRLA1: 8 Vector__XXX
SG_ MotorGen2InvertRateLmtsActv1CRC : 0|8@1+ (1,0) [0|255] "" Vector__XXX
SG_ MotorGen2InvertRateLmtsActv1Cntr : 8|4@1+ (1,0) [0|15] "" Vector__XXX
SG_ MtrGen2InvRatLmtsActAbsSpdRatLmt : 12|12@1+ (0.25,0) [0|1003.75] "%/s" Vector__XXX
SG_ MtrGen2InvRatLmtsActAbsTrqRatLmt : 24|12@1+ (2,0) [0|8030] "%/s" Vector__XXX

BO_ 2297532414 IA: 8 Vector__XXX
SG_ ImpostorPGEventDetectionCounter : 0|8@1+ (1,0) [0|250] "" Vector__XXX
SG_ ImpostorPGSourceAddress : 8|8@1+ (1,0) [0|255] "" Vector__XXX
SG_ ImpostorPGDestinationAddress : 16|8@1+ (1,0) [0|255] "" Vector__XXX
SG_ ImpostorPGN : 24|24@1+ (1,0) [0|16777215] "" Vector__XXX
SG_ TimeSinceLastImposterPGDetected : 48|8@1+ (1,0) [0|250] "min" Vector__XXX

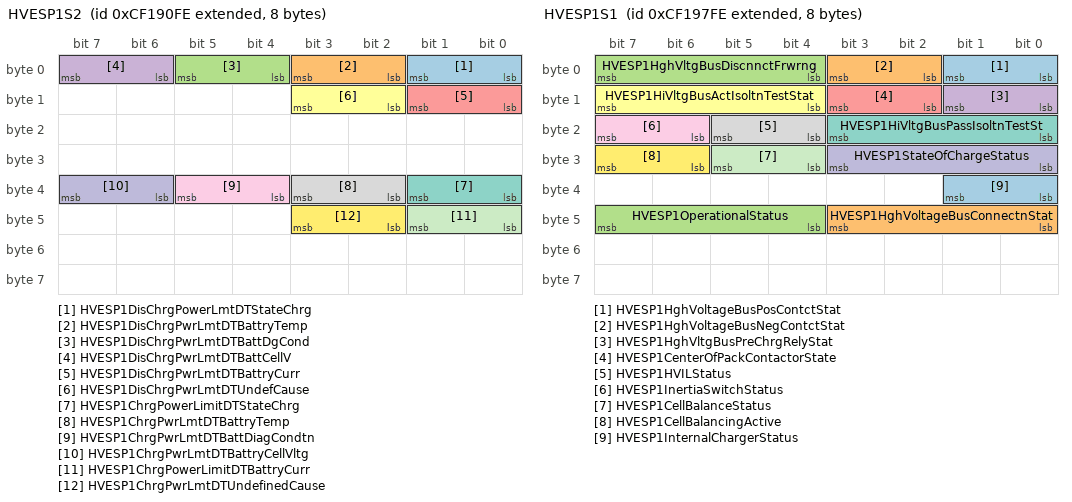
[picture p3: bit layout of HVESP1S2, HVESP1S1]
BO_ 2364641534 HVESP1S2: 8 Vector__XXX
SG_ HVESP1DisChrgPowerLmtDTStateChrg : 0|2@1+ (1,0) [0|3] "" Vector__XXX
SG_ HVESP1DisChrgPwrLmtDTBattryTemp : 2|2@1+ (1,0) [0|3] "" Vector__XXX
SG_ HVESP1DisChrgPwrLmtDTBattDgCond : 4|2@1+ (1,0) [0|3] "" Vector__XXX
SG_ HVESP1DisChrgPwrLmtDTBattCellV : 6|2@1+ (1,0) [0|3] "" Vector__XXX
SG_ HVESP1DisChrgPwrLmtDTBattryCurr : 8|2@1+ (1,0) [0|3] "" Vector__XXX
SG_ HVESP1DisChrgPwrLmtDTUndefCause : 10|2@1+ (1,0) [0|3] "" Vector__XXX
SG_ HVESP1ChrgPowerLimitDTStateChrg : 32|2@1+ (1,0) [0|3] "" Vector__XXX
SG_ HVESP1ChrgPwrLmtDTBattryTemp : 34|2@1+ (1,0) [0|3] "" Vector__XXX
SG_ HVESP1ChrgPwrLmtDTBattDiagCondtn : 36|2@1+ (1,0) [0|3] "" Vector__XXX
SG_ HVESP1ChrgPwrLmtDTBattryCellVltg : 38|2@1+ (1,0) [0|3] "" Vector__XXX
SG_ HVESP1ChrgPowerLimitDTBattryCurr : 40|2@1+ (1,0) [0|3] "" Vector__XXX
SG_ HVESP1ChrgPwrLmtDTUndefinedCause : 42|2@1+ (1,0) [0|3] "" Vector__XXX

BO_ 2364641790 HVESP1D1: 8 Vector__XXX
SG_ HVESP1AvailableDischargePower : 0|16@1+ (0.05,0) [0|3212.75] "kW" Vector__XXX
SG_ HVESP1AvailableChargePower : 16|16@1+ (0.05,0) [0|3212.75] "kW" Vector__XXX
SG_ HVESP1VoltageLevel : 32|16@1+ (0.05,0) [0|3212.75] "V" Vector__XXX
SG_ HVESP1Current : 48|16@1+ (0.05,-1600) [-1600|1612.75] "A" Vector__XXX

BO_ 2364642046 HVESP1D2: 8 Vector__XXX
SG_ HVESP1FastUpdateStateOfCharge : 0|16@1+ (0.0015625,0) [0|100.3984375] "%" Vector__XXX
SG_ HVESP1HighestCellVoltage : 16|16@1+ (0.001,0) [0|64.255] "V" Vector__XXX
SG_ HVESP1LowestCellVoltage : 32|16@1+ (0.001,0) [0|64.255] "V" Vector__XXX
SG_ HVESP1CellVoltageDiffStatus : 48|4@1+ (1,0) [0|15] "" Vector__XXX

BO_ 2364642302 HVESP1D3: 8 Vector__XXX
SG_ HVESP1HighestCellTemperature : 0|16@1+ (0.03125,-273) [-273|1734.96875] "deg C" Vector__XXX
SG_ HVESP1LowestCellTemperature : 16|16@1+ (0.03125,-273) [-273|1734.96875] "deg C" Vector__XXX
SG_ HVESP1AverageCellTemperature : 32|16@1+ (0.03125,-273) [-273|1734.96875] "deg C" Vector__XXX
SG_ HVESP1CellTemperatureDiffStatus : 48|2@1+ (1,0) [0|3] "" Vector__XXX

BO_ 2364642558 HVESP1D4: 8 Vector__XXX
SG_ HVESP1DischargeCapacity : 0|16@1+ (0.01,0) [0|642.55] "Ah" Vector__XXX
SG_ HVESP1ChargeCapacity : 16|16@1+ (0.01,0) [0|642.55] "Ah" Vector__XXX
SG_ HVESP1CellBalancingCount : 32|16@1+ (1,0) [0|64255] "" Vector__XXX

BO_ 2364642814 HVESP1D5: 8 Vector__XXX
SG_ HVESP1DischargeCurrentLimit : 0|16@1+ (0.05,-1600) [-1600|1612.75] "A" Vector__XXX
SG_ HVESP1ChargeCurrentLimit : 16|16@1+ (0.05,-1600) [-1600|1612.75] "A" Vector__XXX
SG_ HVESP1LowestCellStateOfCharge : 32|16@1+ (0.0015625,0) [0|100.3984375] "%" Vector__XXX
SG_ HVESP1HighestCellStateOfCharge : 48|16@1+ (0.0015625,0) [0|100.3984375] "%" Vector__XXX

BO_ 2364643070 HVESP1D6: 8 Vector__XXX
SG_ HVESP1BusVoltage : 0|16@1+ (0.05,0) [0|3212.75] "V" Vector__XXX
SG_ HVESP1IgnitionVoltage : 16|16@1+ (0.01,0) [0|642.55] "V" Vector__XXX
SG_ HVESP1IntakeCoolantTemperature : 32|8@1+ (1,-40) [-40|210] "deg C" Vector__XXX
SG_ HVESP1OutletCoolantTemperature : 40|8@1+ (1,-40) [-40|210] "deg C" Vector__XXX
SG_ HVESP1ElectronicsTemperature : 48|8@1+ (1,-40) [-40|210] "deg C" Vector__XXX
SG_ HVESP1Temperature : 56|8@1+ (1,-40) [-40|210] "deg C" Vector__XXX

BO_ 2364643326 HVESP1S1: 8 Vector__XXX
SG_ HVESP1HghVoltageBusPosContctStat : 0|2@1+ (1,0) [0|3] "" Vector__XXX
SG_ HVESP1HghVoltageBusNegContctStat : 2|2@1+ (1,0) [0|3] "" Vector__XXX
SG_ HVESP1HghVltgBusDiscnnctFrwrng : 4|4@1+ (1,0) [0|15] "" Vector__XXX
SG_ HVESP1HghVltgBusPreChrgRelyStat : 8|2@1+ (1,0) [0|3] "" Vector__XXX
SG_ HVESP1CenterOfPackContactorState : 10|2@1+ (1,0) [0|3] "" Vector__XXX
SG_ HVESP1HiVltgBusActIsoltnTestStat : 12|4@1+ (1,0) [0|15] "" Vector__XXX
SG_ HVESP1HiVltgBusPassIsoltnTestSt : 16|4@1+ (1,0) [0|15] "" Vector__XXX
SG_ HVESP1HVILStatus : 20|2@1+ (1,0) [0|3] "" Vector__XXX
SG_ HVESP1InertiaSwitchStatus : 22|2@1+ (1,0) [0|3] "" Vector__XXX
SG_ HVESP1StateOfChargeStatus : 24|4@1+ (1,0) [0|15] "" Vector__XXX
SG_ HVESP1CellBalanceStatus : 28|2@1+ (1,0) [0|3] "" Vector__XXX
SG_ HVESP1CellBalancingActive : 30|2@1+ (1,0) [0|3] "" Vector__XXX
SG_ HVESP1InternalChargerStatus : 32|2@1+ (1,0) [0|3] "" Vector__XXX
SG_ HVESP1HghVoltageBusConnectnStat : 40|4@1+ (1,0) [0|15] "" Vector__XXX
SG_ HVESP1OperationalStatus : 44|4@1+ (1,0) [0|15] "" Vector__XXX

BO_ 2364643582 HVESP1D7: 8 Vector__XXX
SG_ HVESP1DischargeEnergyCapacity : 0|24@1+ (0.001,0) [0|16449.535] "kWh" Vector__XXX
SG_ HVESP1ChargeEnergyCapacity : 24|24@1+ (0.001,0) [0|16449.535] "kWh" Vector__XXX
SG_ HVESP1MaximumChargeVoltageLimit : 48|16@1+ (0.05,0) [0|3212.75] "V" Vector__XXX

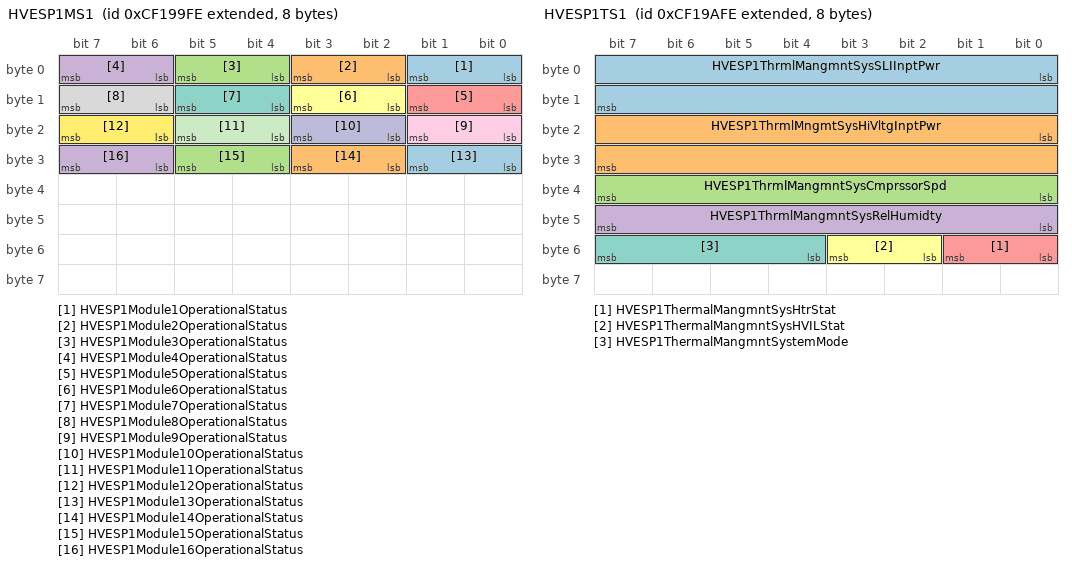
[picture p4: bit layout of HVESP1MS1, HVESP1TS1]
BO_ 2364643838 HVESP1MS1: 8 Vector__XXX
SG_ HVESP1Module1OperationalStatus : 0|2@1+ (1,0) [0|3] "" Vector__XXX
SG_ HVESP1Module2OperationalStatus : 2|2@1+ (1,0) [0|3] "" Vector__XXX
SG_ HVESP1Module3OperationalStatus : 4|2@1+ (1,0) [0|3] "" Vector__XXX
SG_ HVESP1Module4OperationalStatus : 6|2@1+ (1,0) [0|3] "" Vector__XXX
SG_ HVESP1Module5OperationalStatus : 8|2@1+ (1,0) [0|3] "" Vector__XXX
SG_ HVESP1Module6OperationalStatus : 10|2@1+ (1,0) [0|3] "" Vector__XXX
SG_ HVESP1Module7OperationalStatus : 12|2@1+ (1,0) [0|3] "" Vector__XXX
SG_ HVESP1Module8OperationalStatus : 14|2@1+ (1,0) [0|3] "" Vector__XXX
SG_ HVESP1Module9OperationalStatus : 16|2@1+ (1,0) [0|3] "" Vector__XXX
SG_ HVESP1Module10OperationalStatus : 18|2@1+ (1,0) [0|3] "" Vector__XXX
SG_ HVESP1Module11OperationalStatus : 20|2@1+ (1,0) [0|3] "" Vector__XXX
SG_ HVESP1Module12OperationalStatus : 22|2@1+ (1,0) [0|3] "" Vector__XXX
SG_ HVESP1Module13OperationalStatus : 24|2@1+ (1,0) [0|3] "" Vector__XXX
SG_ HVESP1Module14OperationalStatus : 26|2@1+ (1,0) [0|3] "" Vector__XXX
SG_ HVESP1Module15OperationalStatus : 28|2@1+ (1,0) [0|3] "" Vector__XXX
SG_ HVESP1Module16OperationalStatus : 30|2@1+ (1,0) [0|3] "" Vector__XXX

BO_ 2364644094 HVESP1TS1: 8 Vector__XXX
SG_ HVESP1ThrmlMangmntSysSLIInptPwr : 0|16@1+ (0.5,0) [0|32127.5] "W" Vector__XXX
SG_ HVESP1ThrmlMngmtSysHiVltgInptPwr : 16|16@1+ (0.5,0) [0|32127.5] "W" Vector__XXX
SG_ HVESP1ThrmlMangmntSysCmprssorSpd : 32|8@1+ (32,0) [0|8000] "rpm" Vector__XXX
SG_ HVESP1ThrmlMangmntSysRelHumidty : 40|8@1+ (0.4,0) [0|100] "%" Vector__XXX
SG_ HVESP1ThermalMangmntSysHtrStat : 48|2@1+ (1,0) [0|3] "" Vector__XXX
SG_ HVESP1ThermalMangmntSysHVILStat : 50|2@1+ (1,0) [0|3] "" Vector__XXX
SG_ HVESP1ThermalMangmntSystemMode : 52|4@1+ (1,0) [0|15] "" Vector__XXX

BO_ 2364644350 HVESP1D8: 8 Vector__XXX
SG_ HVESP1HghestCellVoltageMdulNo : 0|8@1+ (1,0) [0|250] "" Vector__XXX
SG_ HVESP1HghestCellVoltageCellNo : 8|8@1+ (1,0) [0|250] "" Vector__XXX
SG_ HVESP1LowestCellVoltageMdulNo : 16|8@1+ (1,0) [0|250] "" Vector__XXX
SG_ HVESP1LowestCellVoltageCellNo : 24|8@1+ (1,0) [0|250] "" Vector__XXX
SG_ HVESP1AverageCellVoltage : 32|16@1+ (0.001,0) [0|64.255] "V" Vector__XXX

BO_ 2364644606 HVESP1D9: 8 Vector__XXX
SG_ HVESP1HghestCellTempMdulNo : 0|8@1+ (1,0) [0|250] "" Vector__XXX
SG_ HVESP1HghestCellTempCellNo : 8|8@1+ (1,0) [0|250] "" Vector__XXX
SG_ HVESP1LowestCellTempMdulNo : 16|8@1+ (1,0) [0|250] "" Vector__XXX
SG_ HVESP1LowestCellTempCellNo : 24|8@1+ (1,0) [0|250] "" Vector__XXX

BO_ 2364644862 HVESP1D10: 8 Vector__XXX
SG_ HVESP1HghestCellStateChrgMdulNo : 0|8@1+ (1,0) [0|250] "" Vector__XXX
SG_ HVESP1HghestCellStateChrgCellNo : 8|8@1+ (1,0) [0|250] "" Vector__XXX
SG_ HVESP1LowestCellStateChrgMdulNo : 16|8@1+ (1,0) [0|250] "" Vector__XXX
SG_ HVESP1LowestCellStateChrgCellNo : 24|8@1+ (1,0) [0|250] "" Vector__XXX
SG_ HVESP1HiVltgBusActIsoltnTestRess : 32|16@1+ (0.1,0) [0|6425.5] "ohm/V" Vector__XXX
SG_ HVESP1HiVltgBusPassIsoltnTtRess : 48|16@1+ (0.1,0) [0|6425.5] "ohm/V" Vector__XXX

BO_ 2364645118 HVESP1D11: 8 Vector__XXX
SG_ HVESP1BusVltgNegToChssGrndVltg : 0|16@1+ (0.05,0) [0|3212.75] "V" Vector__XXX
SG_ HVESP1VltgLvlNegToChssGrndVltg : 16|16@1+ (0.05,0) [0|3212.75] "V" Vector__XXX

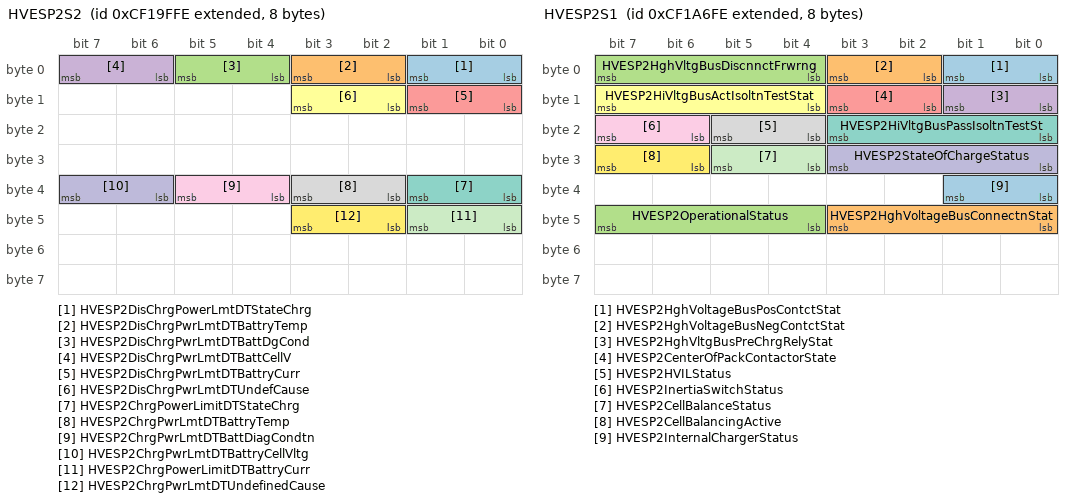
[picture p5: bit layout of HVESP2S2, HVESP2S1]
BO_ 2364645374 HVESP2S2: 8 Vector__XXX
SG_ HVESP2DisChrgPowerLmtDTStateChrg : 0|2@1+ (1,0) [0|3] "" Vector__XXX
SG_ HVESP2DisChrgPwrLmtDTBattryTemp : 2|2@1+ (1,0) [0|3] "" Vector__XXX
SG_ HVESP2DisChrgPwrLmtDTBattDgCond : 4|2@1+ (1,0) [0|3] "" Vector__XXX
SG_ HVESP2DisChrgPwrLmtDTBattCellV : 6|2@1+ (1,0) [0|3] "" Vector__XXX
SG_ HVESP2DisChrgPwrLmtDTBattryCurr : 8|2@1+ (1,0) [0|3] "" Vector__XXX
SG_ HVESP2DisChrgPwrLmtDTUndefCause : 10|2@1+ (1,0) [0|3] "" Vector__XXX
SG_ HVESP2ChrgPowerLimitDTStateChrg : 32|2@1+ (1,0) [0|3] "" Vector__XXX
SG_ HVESP2ChrgPwrLmtDTBattryTemp : 34|2@1+ (1,0) [0|3] "" Vector__XXX
SG_ HVESP2ChrgPwrLmtDTBattDiagCondtn : 36|2@1+ (1,0) [0|3] "" Vector__XXX
SG_ HVESP2ChrgPwrLmtDTBattryCellVltg : 38|2@1+ (1,0) [0|3] "" Vector__XXX
SG_ HVESP2ChrgPowerLimitDTBattryCurr : 40|2@1+ (1,0) [0|3] "" Vector__XXX
SG_ HVESP2ChrgPwrLmtDTUndefinedCause : 42|2@1+ (1,0) [0|3] "" Vector__XXX

BO_ 2364645630 HVESP2D1: 8 Vector__XXX
SG_ HVESP2AvailableDischargePower : 0|16@1+ (0.05,0) [0|3212.75] "kW" Vector__XXX
SG_ HVESP2AvailableChargePower : 16|16@1+ (0.05,0) [0|3212.75] "kW" Vector__XXX
SG_ HVESP2VoltageLevel : 32|16@1+ (0.05,0) [0|3212.75] "V" Vector__XXX
SG_ HVESP2Current : 48|16@1+ (0.05,-1600) [-1600|1612.75] "A" Vector__XXX

BO_ 2364645886 HVESP2D2: 8 Vector__XXX
SG_ HVESP2FastUpdateStateOfCharge : 0|16@1+ (0.0015625,0) [0|100.3984375] "%" Vector__XXX
SG_ HVESP2HighestCellVoltage : 16|16@1+ (0.001,0) [0|64.255] "V" Vector__XXX
SG_ HVESP2LowestCellVoltage : 32|16@1+ (0.001,0) [0|64.255] "V" Vector__XXX
SG_ HVESP2CellVoltageDiffStatus : 48|4@1+ (1,0) [0|15] "" Vector__XXX

BO_ 2364646142 HVESP2D3: 8 Vector__XXX
SG_ HVESP2HighestCellTemperature : 0|16@1+ (0.03125,-273) [-273|1734.96875] "deg C" Vector__XXX
SG_ HVESP2LowestCellTemperature : 16|16@1+ (0.03125,-273) [-273|1734.96875] "deg C" Vector__XXX
SG_ HVESP2AverageCellTemperature : 32|16@1+ (0.03125,-273) [-273|1734.96875] "deg C" Vector__XXX
SG_ HVESP2CellTemperatureDiffStatus : 48|2@1+ (1,0) [0|3] "" Vector__XXX

BO_ 2364646398 HVESP2D4: 8 Vector__XXX
SG_ HVESP2DischargeCapacity : 0|16@1+ (0.01,0) [0|642.55] "Ah" Vector__XXX
SG_ HVESP2ChargeCapacity : 16|16@1+ (0.01,0) [0|642.55] "Ah" Vector__XXX
SG_ HVESP2CellBalancingCount : 32|16@1+ (1,0) [0|64255] "" Vector__XXX

BO_ 2364646654 HVESP2D5: 8 Vector__XXX
SG_ HVESP2DischargeCurrentLimit : 0|16@1+ (0.05,-1600) [-1600|1612.75] "A" Vector__XXX
SG_ HVESP2ChargeCurrentLimit : 16|16@1+ (0.05,-1600) [-1600|1612.75] "A" Vector__XXX
SG_ HVESP2LowestCellStateOfCharge : 32|16@1+ (0.0015625,0) [0|100.3984375] "%" Vector__XXX
SG_ HVESP2HighestCellStateOfCharge : 48|16@1+ (0.0015625,0) [0|100.3984375] "%" Vector__XXX

BO_ 2364646910 HVESP2D6: 8 Vector__XXX
SG_ HVESP2BusVoltage : 0|16@1+ (0.05,0) [0|3212.75] "V" Vector__XXX
SG_ HVESP2IgnitionVoltage : 16|16@1+ (0.01,0) [0|642.55] "V" Vector__XXX
SG_ HVESP2IntakeCoolantTemperature : 32|8@1+ (1,-40) [-40|210] "deg C" Vector__XXX
SG_ HVESP2OutletCoolantTemperature : 40|8@1+ (1,-40) [-40|210] "deg C" Vector__XXX
SG_ HVESP2ElectronicsTemperature : 48|8@1+ (1,-40) [-40|210] "deg C" Vector__XXX
SG_ HVESP2Temperature : 56|8@1+ (1,-40) [-40|210] "deg C" Vector__XXX

BO_ 2364647166 HVESP2S1: 8 Vector__XXX
SG_ HVESP2HghVoltageBusPosContctStat : 0|2@1+ (1,0) [0|3] "" Vector__XXX
SG_ HVESP2HghVoltageBusNegContctStat : 2|2@1+ (1,0) [0|3] "" Vector__XXX
SG_ HVESP2HghVltgBusDiscnnctFrwrng : 4|4@1+ (1,0) [0|15] "" Vector__XXX
SG_ HVESP2HghVltgBusPreChrgRelyStat : 8|2@1+ (1,0) [0|3] "" Vector__XXX
SG_ HVESP2CenterOfPackContactorState : 10|2@1+ (1,0) [0|3] "" Vector__XXX
SG_ HVESP2HiVltgBusActIsoltnTestStat : 12|4@1+ (1,0) [0|15] "" Vector__XXX
SG_ HVESP2HiVltgBusPassIsoltnTestSt : 16|4@1+ (1,0) [0|15] "" Vector__XXX
SG_ HVESP2HVILStatus : 20|2@1+ (1,0) [0|3] "" Vector__XXX
SG_ HVESP2InertiaSwitchStatus : 22|2@1+ (1,0) [0|3] "" Vector__XXX
SG_ HVESP2StateOfChargeStatus : 24|4@1+ (1,0) [0|15] "" Vector__XXX
SG_ HVESP2CellBalanceStatus : 28|2@1+ (1,0) [0|3] "" Vector__XXX
SG_ HVESP2CellBalancingActive : 30|2@1+ (1,0) [0|3] "" Vector__XXX
SG_ HVESP2InternalChargerStatus : 32|2@1+ (1,0) [0|3] "" Vector__XXX
SG_ HVESP2HghVoltageBusConnectnStat : 40|4@1+ (1,0) [0|15] "" Vector__XXX
SG_ HVESP2OperationalStatus : 44|4@1+ (1,0) [0|15] "" Vector__XXX

BO_ 2364647422 HVESP2D7: 8 Vector__XXX
SG_ HVESP2DischargeEnergyCapacity : 0|24@1+ (0.001,0) [0|16449.535] "kWh" Vector__XXX
SG_ HVESP2ChargeEnergyCapacity : 24|24@1+ (0.001,0) [0|16449.535] "kWh" Vector__XXX
SG_ HVESP2MaximumChargeVoltageLimit : 48|16@1+ (0.05,0) [0|3212.75] "V" Vector__XXX

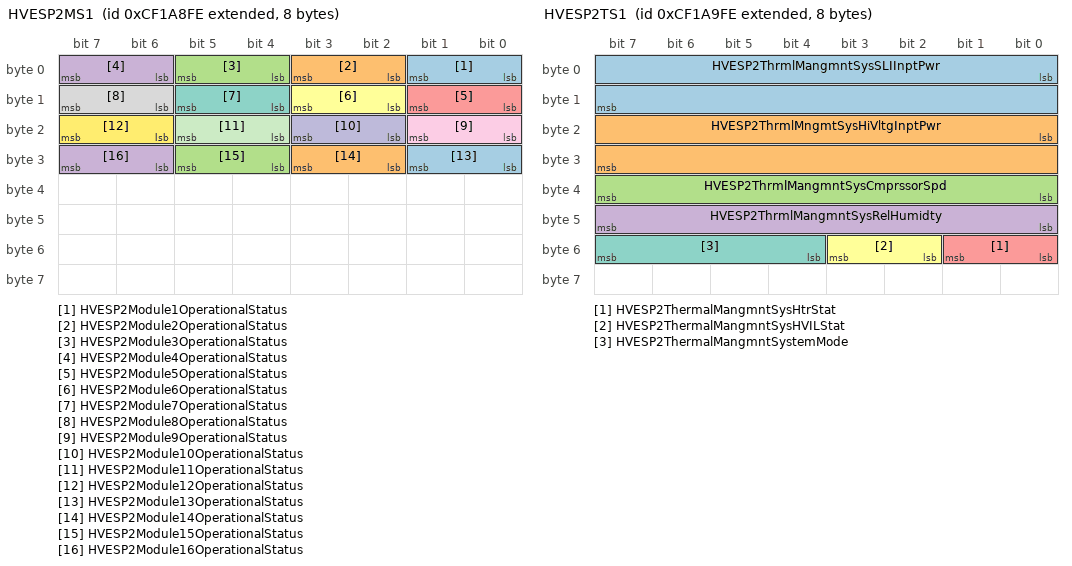
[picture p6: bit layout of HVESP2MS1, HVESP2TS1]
BO_ 2364647678 HVESP2MS1: 8 Vector__XXX
SG_ HVESP2Module1OperationalStatus : 0|2@1+ (1,0) [0|3] "" Vector__XXX
SG_ HVESP2Module2OperationalStatus : 2|2@1+ (1,0) [0|3] "" Vector__XXX
SG_ HVESP2Module3OperationalStatus : 4|2@1+ (1,0) [0|3] "" Vector__XXX
SG_ HVESP2Module4OperationalStatus : 6|2@1+ (1,0) [0|3] "" Vector__XXX
SG_ HVESP2Module5OperationalStatus : 8|2@1+ (1,0) [0|3] "" Vector__XXX
SG_ HVESP2Module6OperationalStatus : 10|2@1+ (1,0) [0|3] "" Vector__XXX
SG_ HVESP2Module7OperationalStatus : 12|2@1+ (1,0) [0|3] "" Vector__XXX
SG_ HVESP2Module8OperationalStatus : 14|2@1+ (1,0) [0|3] "" Vector__XXX
SG_ HVESP2Module9OperationalStatus : 16|2@1+ (1,0) [0|3] "" Vector__XXX
SG_ HVESP2Module10OperationalStatus : 18|2@1+ (1,0) [0|3] "" Vector__XXX
SG_ HVESP2Module11OperationalStatus : 20|2@1+ (1,0) [0|3] "" Vector__XXX
SG_ HVESP2Module12OperationalStatus : 22|2@1+ (1,0) [0|3] "" Vector__XXX
SG_ HVESP2Module13OperationalStatus : 24|2@1+ (1,0) [0|3] "" Vector__XXX
SG_ HVESP2Module14OperationalStatus : 26|2@1+ (1,0) [0|3] "" Vector__XXX
SG_ HVESP2Module15OperationalStatus : 28|2@1+ (1,0) [0|3] "" Vector__XXX
SG_ HVESP2Module16OperationalStatus : 30|2@1+ (1,0) [0|3] "" Vector__XXX

BO_ 2364647934 HVESP2TS1: 8 Vector__XXX
SG_ HVESP2ThrmlMangmntSysSLIInptPwr : 0|16@1+ (0.5,0) [0|32127.5] "W" Vector__XXX
SG_ HVESP2ThrmlMngmtSysHiVltgInptPwr : 16|16@1+ (0.5,0) [0|32127.5] "W" Vector__XXX
SG_ HVESP2ThrmlMangmntSysCmprssorSpd : 32|8@1+ (32,0) [0|8000] "rpm" Vector__XXX
SG_ HVESP2ThrmlMangmntSysRelHumidty : 40|8@1+ (0.4,0) [0|100] "%" Vector__XXX
SG_ HVESP2ThermalMangmntSysHtrStat : 48|2@1+ (1,0) [0|3] "" Vector__XXX
SG_ HVESP2ThermalMangmntSysHVILStat : 50|2@1+ (1,0) [0|3] "" Vector__XXX
SG_ HVESP2ThermalMangmntSystemMode : 52|4@1+ (1,0) [0|15] "" Vector__XXX

BO_ 2364648190 HVESP2D8: 8 Vector__XXX
SG_ HVESP2HghestCellVoltageMdulNo : 0|8@1+ (1,0) [0|250] "" Vector__XXX
SG_ HVESP2HghestCellVoltageCellNo : 8|8@1+ (1,0) [0|250] "" Vector__XXX
SG_ HVESP2LowestCellVoltageMdulNo : 16|8@1+ (1,0) [0|250] "" Vector__XXX
SG_ HVESP2LowestCellVoltageCellNo : 24|8@1+ (1,0) [0|250] "" Vector__XXX
SG_ HVESP2AverageCellVoltage : 32|16@1+ (0.001,0) [0|64.255] "V" Vector__XXX

BO_ 2364648446 HVESP2D9: 8 Vector__XXX
SG_ HVESP2HghestCellTempMdulNo : 0|8@1+ (1,0) [0|250] "" Vector__XXX
SG_ HVESP2HghestCellTempCellNo : 8|8@1+ (1,0) [0|250] "" Vector__XXX
SG_ HVESP2LowestCellTempMdulNo : 16|8@1+ (1,0) [0|250] "" Vector__XXX
SG_ HVESP2LowestCellTempCellNo : 24|8@1+ (1,0) [0|250] "" Vector__XXX

BO_ 2364648702 HVESP2D10: 8 Vector__XXX
SG_ HVESP2HghestCellStateChrgMdulNo : 0|8@1+ (1,0) [0|250] "" Vector__XXX
SG_ HVESP2HghestCellStateChrgCellNo : 8|8@1+ (1,0) [0|250] "" Vector__XXX
SG_ HVESP2LowestCellStateChrgMdulNo : 16|8@1+ (1,0) [0|250] "" Vector__XXX
SG_ HVESP2LowestCellStateChrgCellNo : 24|8@1+ (1,0) [0|250] "" Vector__XXX
SG_ HVESP2HiVltgBusActIsoltnTestRess : 32|16@1+ (0.1,0) [0|6425.5] "ohm/V" Vector__XXX
SG_ HVESP2HiVltgBusPassIsoltnTtRess : 48|16@1+ (0.1,0) [0|6425.5] "ohm/V" Vector__XXX

BO_ 2364648958 HVESP2D11: 8 Vector__XXX
SG_ HVESP2BusVltgNegToChssGrndVltg : 0|16@1+ (0.05,0) [0|3212.75] "V" Vector__XXX
SG_ HVESP2VltgLvlNegToChssGrndVltg : 16|16@1+ (0.05,0) [0|3212.75] "V" Vector__XXX

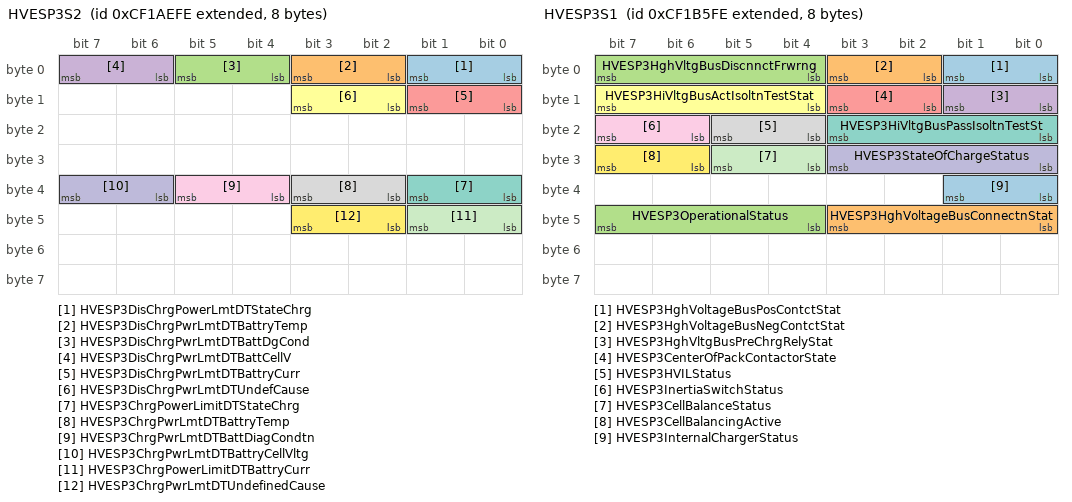
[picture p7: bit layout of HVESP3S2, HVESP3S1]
BO_ 2364649214 HVESP3S2: 8 Vector__XXX
SG_ HVESP3DisChrgPowerLmtDTStateChrg : 0|2@1+ (1,0) [0|3] "" Vector__XXX
SG_ HVESP3DisChrgPwrLmtDTBattryTemp : 2|2@1+ (1,0) [0|3] "" Vector__XXX
SG_ HVESP3DisChrgPwrLmtDTBattDgCond : 4|2@1+ (1,0) [0|3] "" Vector__XXX
SG_ HVESP3DisChrgPwrLmtDTBattCellV : 6|2@1+ (1,0) [0|3] "" Vector__XXX
SG_ HVESP3DisChrgPwrLmtDTBattryCurr : 8|2@1+ (1,0) [0|3] "" Vector__XXX
SG_ HVESP3DisChrgPwrLmtDTUndefCause : 10|2@1+ (1,0) [0|3] "" Vector__XXX
SG_ HVESP3ChrgPowerLimitDTStateChrg : 32|2@1+ (1,0) [0|3] "" Vector__XXX
SG_ HVESP3ChrgPwrLmtDTBattryTemp : 34|2@1+ (1,0) [0|3] "" Vector__XXX
SG_ HVESP3ChrgPwrLmtDTBattDiagCondtn : 36|2@1+ (1,0) [0|3] "" Vector__XXX
SG_ HVESP3ChrgPwrLmtDTBattryCellVltg : 38|2@1+ (1,0) [0|3] "" Vector__XXX
SG_ HVESP3ChrgPowerLimitDTBattryCurr : 40|2@1+ (1,0) [0|3] "" Vector__XXX
SG_ HVESP3ChrgPwrLmtDTUndefinedCause : 42|2@1+ (1,0) [0|3] "" Vector__XXX

BO_ 2364649470 HVESP3D1: 8 Vector__XXX
SG_ HVESP3AvailableDischargePower : 0|16@1+ (0.05,0) [0|3212.75] "kW" Vector__XXX
SG_ HVESP3AvailableChargePower : 16|16@1+ (0.05,0) [0|3212.75] "kW" Vector__XXX
SG_ HVESP3VoltageLevel : 32|16@1+ (0.05,0) [0|3212.75] "V" Vector__XXX
SG_ HVESP3Current : 48|16@1+ (0.05,-1600) [-1600|1612.75] "A" Vector__XXX

BO_ 2364649726 HVESP3D2: 8 Vector__XXX
SG_ HVESP3FastUpdateStateOfCharge : 0|16@1+ (0.0015625,0) [0|100.3984375] "%" Vector__XXX
SG_ HVESP3HighestCellVoltage : 16|16@1+ (0.001,0) [0|64.255] "V" Vector__XXX
SG_ HVESP3LowestCellVoltage : 32|16@1+ (0.001,0) [0|64.255] "V" Vector__XXX
SG_ HVESP3CellVoltageDiffStatus : 48|4@1+ (1,0) [0|15] "" Vector__XXX

BO_ 2364649982 HVESP3D3: 8 Vector__XXX
SG_ HVESP3HighestCellTemperature : 0|16@1+ (0.03125,-273) [-273|1734.96875] "deg C" Vector__XXX
SG_ HVESP3LowestCellTemperature : 16|16@1+ (0.03125,-273) [-273|1734.96875] "deg C" Vector__XXX
SG_ HVESP3AverageCellTemperature : 32|16@1+ (0.03125,-273) [-273|1734.96875] "deg C" Vector__XXX
SG_ HVESP3CellTemperatureDiffStatus : 48|2@1+ (1,0) [0|3] "" Vector__XXX

BO_ 2364650238 HVESP3D4: 8 Vector__XXX
SG_ HVESP3DischargeCapacity : 0|16@1+ (0.01,0) [0|642.55] "Ah" Vector__XXX
SG_ HVESP3ChargeCapacity : 16|16@1+ (0.01,0) [0|642.55] "Ah" Vector__XXX
SG_ HVESP3CellBalancingCount : 32|16@1+ (1,0) [0|64255] "" Vector__XXX

BO_ 2364650494 HVESP3D5: 8 Vector__XXX
SG_ HVESP3DischargeCurrentLimit : 0|16@1+ (0.05,-1600) [-1600|1612.75] "A" Vector__XXX
SG_ HVESP3ChargeCurrentLimit : 16|16@1+ (0.05,-1600) [-1600|1612.75] "A" Vector__XXX
SG_ HVESP3LowestCellStateOfCharge : 32|16@1+ (0.0015625,0) [0|100.3984375] "%" Vector__XXX
SG_ HVESP3HighestCellStateOfCharge : 48|16@1+ (0.0015625,0) [0|100.3984375] "%" Vector__XXX

BO_ 2364650750 HVESP3D6: 8 Vector__XXX
SG_ HVESP3BusVoltage : 0|16@1+ (0.05,0) [0|3212.75] "V" Vector__XXX
SG_ HVESP3IgnitionVoltage : 16|16@1+ (0.01,0) [0|642.55] "V" Vector__XXX
SG_ HVESP3IntakeCoolantTemperature : 32|8@1+ (1,-40) [-40|210] "deg C" Vector__XXX
SG_ HVESP3OutletCoolantTemperature : 40|8@1+ (1,-40) [-40|210] "deg C" Vector__XXX
SG_ HVESP3ElectronicsTemperature : 48|8@1+ (1,-40) [-40|210] "deg C" Vector__XXX
SG_ HVESP3Temperature : 56|8@1+ (1,-40) [-40|210] "deg C" Vector__XXX

BO_ 2364651006 HVESP3S1: 8 Vector__XXX
SG_ HVESP3HghVoltageBusPosContctStat : 0|2@1+ (1,0) [0|3] "" Vector__XXX
SG_ HVESP3HghVoltageBusNegContctStat : 2|2@1+ (1,0) [0|3] "" Vector__XXX
SG_ HVESP3HghVltgBusDiscnnctFrwrng : 4|4@1+ (1,0) [0|15] "" Vector__XXX
SG_ HVESP3HghVltgBusPreChrgRelyStat : 8|2@1+ (1,0) [0|3] "" Vector__XXX
SG_ HVESP3CenterOfPackContactorState : 10|2@1+ (1,0) [0|3] "" Vector__XXX
SG_ HVESP3HiVltgBusActIsoltnTestStat : 12|4@1+ (1,0) [0|15] "" Vector__XXX
SG_ HVESP3HiVltgBusPassIsoltnTestSt : 16|4@1+ (1,0) [0|15] "" Vector__XXX
SG_ HVESP3HVILStatus : 20|2@1+ (1,0) [0|3] "" Vector__XXX
SG_ HVESP3InertiaSwitchStatus : 22|2@1+ (1,0) [0|3] "" Vector__XXX
SG_ HVESP3StateOfChargeStatus : 24|4@1+ (1,0) [0|15] "" Vector__XXX
SG_ HVESP3CellBalanceStatus : 28|2@1+ (1,0) [0|3] "" Vector__XXX
SG_ HVESP3CellBalancingActive : 30|2@1+ (1,0) [0|3] "" Vector__XXX
SG_ HVESP3InternalChargerStatus : 32|2@1+ (1,0) [0|3] "" Vector__XXX
SG_ HVESP3HghVoltageBusConnectnStat : 40|4@1+ (1,0) [0|15] "" Vector__XXX
SG_ HVESP3OperationalStatus : 44|4@1+ (1,0) [0|15] "" Vector__XXX

BO_ 2364651262 HVESP3D7: 8 Vector__XXX
SG_ HVESP3DischargeEnergyCapacity : 0|24@1+ (0.001,0) [0|16449.535] "kWh" Vector__XXX
SG_ HVESP3ChargeEnergyCapacity : 24|24@1+ (0.001,0) [0|16449.535] "kWh" Vector__XXX
SG_ HVESP3MaximumChargeVoltageLimit : 48|16@1+ (0.05,0) [0|3212.75] "V" Vector__XXX

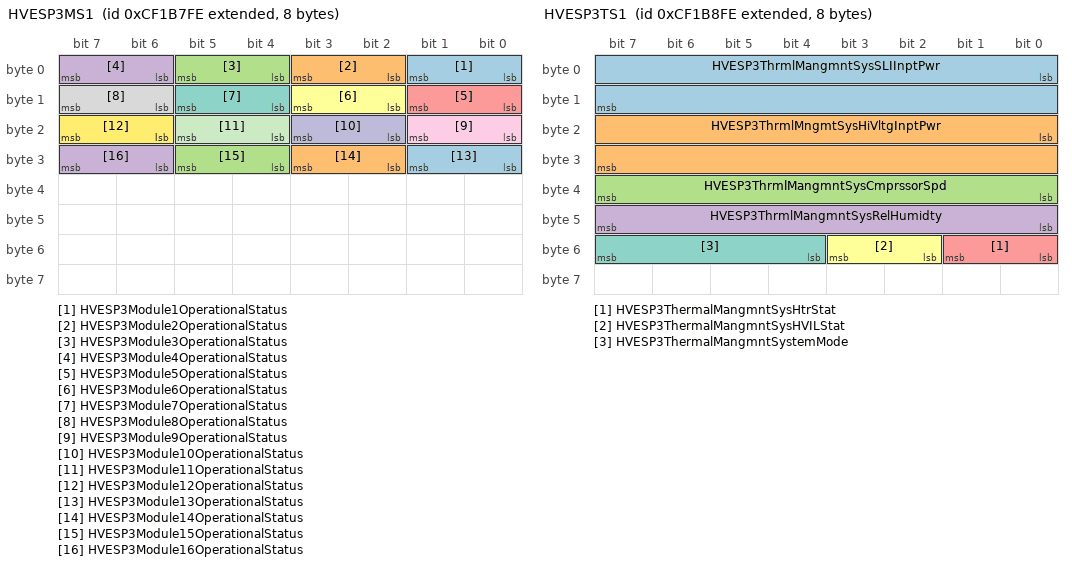
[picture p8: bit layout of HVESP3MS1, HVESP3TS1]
BO_ 2364651518 HVESP3MS1: 8 Vector__XXX
SG_ HVESP3Module1OperationalStatus : 0|2@1+ (1,0) [0|3] "" Vector__XXX
SG_ HVESP3Module2OperationalStatus : 2|2@1+ (1,0) [0|3] "" Vector__XXX
SG_ HVESP3Module3OperationalStatus : 4|2@1+ (1,0) [0|3] "" Vector__XXX
SG_ HVESP3Module4OperationalStatus : 6|2@1+ (1,0) [0|3] "" Vector__XXX
SG_ HVESP3Module5OperationalStatus : 8|2@1+ (1,0) [0|3] "" Vector__XXX
SG_ HVESP3Module6OperationalStatus : 10|2@1+ (1,0) [0|3] "" Vector__XXX
SG_ HVESP3Module7OperationalStatus : 12|2@1+ (1,0) [0|3] "" Vector__XXX
SG_ HVESP3Module8OperationalStatus : 14|2@1+ (1,0) [0|3] "" Vector__XXX
SG_ HVESP3Module9OperationalStatus : 16|2@1+ (1,0) [0|3] "" Vector__XXX
SG_ HVESP3Module10OperationalStatus : 18|2@1+ (1,0) [0|3] "" Vector__XXX
SG_ HVESP3Module11OperationalStatus : 20|2@1+ (1,0) [0|3] "" Vector__XXX
SG_ HVESP3Module12OperationalStatus : 22|2@1+ (1,0) [0|3] "" Vector__XXX
SG_ HVESP3Module13OperationalStatus : 24|2@1+ (1,0) [0|3] "" Vector__XXX
SG_ HVESP3Module14OperationalStatus : 26|2@1+ (1,0) [0|3] "" Vector__XXX
SG_ HVESP3Module15OperationalStatus : 28|2@1+ (1,0) [0|3] "" Vector__XXX
SG_ HVESP3Module16OperationalStatus : 30|2@1+ (1,0) [0|3] "" Vector__XXX

BO_ 2364651774 HVESP3TS1: 8 Vector__XXX
SG_ HVESP3ThrmlMangmntSysSLIInptPwr : 0|16@1+ (0.5,0) [0|32127.5] "W" Vector__XXX
SG_ HVESP3ThrmlMngmtSysHiVltgInptPwr : 16|16@1+ (0.5,0) [0|32127.5] "W" Vector__XXX
SG_ HVESP3ThrmlMangmntSysCmprssorSpd : 32|8@1+ (32,0) [0|8000] "rpm" Vector__XXX
SG_ HVESP3ThrmlMangmntSysRelHumidty : 40|8@1+ (0.4,0) [0|100] "%" Vector__XXX
SG_ HVESP3ThermalMangmntSysHtrStat : 48|2@1+ (1,0) [0|3] "" Vector__XXX
SG_ HVESP3ThermalMangmntSysHVILStat : 50|2@1+ (1,0) [0|3] "" Vector__XXX
SG_ HVESP3ThermalMangmntSystemMode : 52|4@1+ (1,0) [0|15] "" Vector__XXX

BO_ 2364652030 HVESP3D8: 8 Vector__XXX
SG_ HVESP3HghestCellVoltageMdulNo : 0|8@1+ (1,0) [0|250] "" Vector__XXX
SG_ HVESP3HghestCellVoltageCellNo : 8|8@1+ (1,0) [0|250] "" Vector__XXX
SG_ HVESP3LowestCellVoltageMdulNo : 16|8@1+ (1,0) [0|250] "" Vector__XXX
SG_ HVESP3LowestCellVoltageCellNo : 24|8@1+ (1,0) [0|250] "" Vector__XXX
SG_ HVESP3AverageCellVoltage : 32|16@1+ (0.001,0) [0|64.255] "V" Vector__XXX

BO_ 2364652286 HVESP3D9: 8 Vector__XXX
SG_ HVESP3HghestCellTempMdulNo : 0|8@1+ (1,0) [0|250] "" Vector__XXX
SG_ HVESP3HghestCellTempCellNo : 8|8@1+ (1,0) [0|250] "" Vector__XXX
SG_ HVESP3LowestCellTempMdulNo : 16|8@1+ (1,0) [0|250] "" Vector__XXX
SG_ HVESP3LowestCellTempCellNo : 24|8@1+ (1,0) [0|250] "" Vector__XXX

BO_ 2364652542 HVESP3D10: 8 Vector__XXX
SG_ HVESP3HghestCellStateChrgMdulNo : 0|8@1+ (1,0) [0|250] "" Vector__XXX
SG_ HVESP3HghestCellStateChrgCellNo : 8|8@1+ (1,0) [0|250] "" Vector__XXX
SG_ HVESP3LowestCellStateChrgMdulNo : 16|8@1+ (1,0) [0|250] "" Vector__XXX
SG_ HVESP3LowestCellStateChrgCellNo : 24|8@1+ (1,0) [0|250] "" Vector__XXX
SG_ HVESP3HiVltgBusActIsoltnTestRess : 32|16@1+ (0.1,0) [0|6425.5] "ohm/V" Vector__XXX
SG_ HVESP3HiVltgBusPassIsoltnTtRess : 48|16@1+ (0.1,0) [0|6425.5] "ohm/V" Vector__XXX

BO_ 2364652798 HVESP3D11: 8 Vector__XXX
SG_ HVESP3BusVltgNegToChssGrndVltg : 0|16@1+ (0.05,0) [0|3212.75] "V" Vector__XXX
SG_ HVESP3VltgLvlNegToChssGrndVltg : 16|16@1+ (0.05,0) [0|3212.75] "V" Vector__XXX

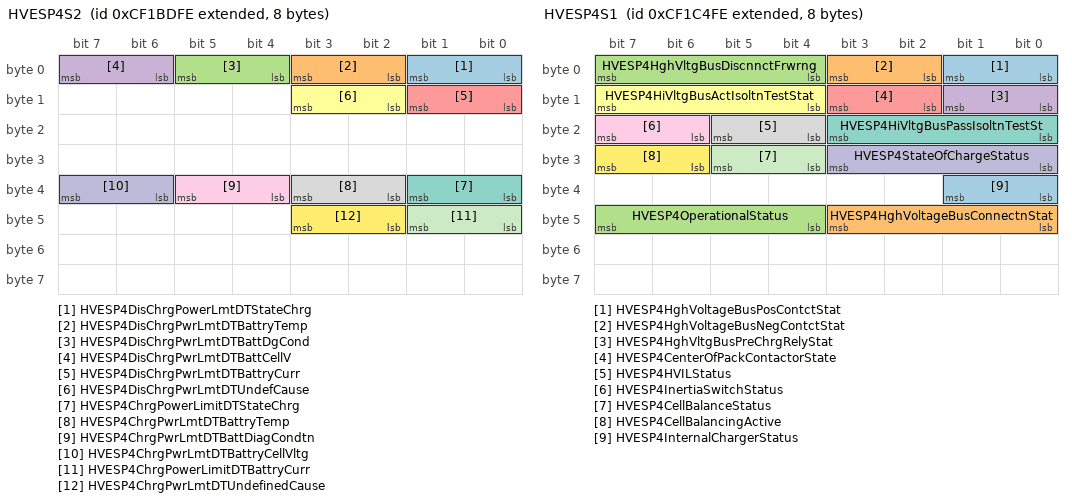
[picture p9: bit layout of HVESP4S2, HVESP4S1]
BO_ 2364653054 HVESP4S2: 8 Vector__XXX
SG_ HVESP4DisChrgPowerLmtDTStateChrg : 0|2@1+ (1,0) [0|3] "" Vector__XXX
SG_ HVESP4DisChrgPwrLmtDTBattryTemp : 2|2@1+ (1,0) [0|3] "" Vector__XXX
SG_ HVESP4DisChrgPwrLmtDTBattDgCond : 4|2@1+ (1,0) [0|3] "" Vector__XXX
SG_ HVESP4DisChrgPwrLmtDTBattCellV : 6|2@1+ (1,0) [0|3] "" Vector__XXX
SG_ HVESP4DisChrgPwrLmtDTBattryCurr : 8|2@1+ (1,0) [0|3] "" Vector__XXX
SG_ HVESP4DisChrgPwrLmtDTUndefCause : 10|2@1+ (1,0) [0|3] "" Vector__XXX
SG_ HVESP4ChrgPowerLimitDTStateChrg : 32|2@1+ (1,0) [0|3] "" Vector__XXX
SG_ HVESP4ChrgPwrLmtDTBattryTemp : 34|2@1+ (1,0) [0|3] "" Vector__XXX
SG_ HVESP4ChrgPwrLmtDTBattDiagCondtn : 36|2@1+ (1,0) [0|3] "" Vector__XXX
SG_ HVESP4ChrgPwrLmtDTBattryCellVltg : 38|2@1+ (1,0) [0|3] "" Vector__XXX
SG_ HVESP4ChrgPowerLimitDTBattryCurr : 40|2@1+ (1,0) [0|3] "" Vector__XXX
SG_ HVESP4ChrgPwrLmtDTUndefinedCause : 42|2@1+ (1,0) [0|3] "" Vector__XXX

BO_ 2364653310 HVESP4D1: 8 Vector__XXX
SG_ HVESP4AvailableDischargePower : 0|16@1+ (0.05,0) [0|3212.75] "kW" Vector__XXX
SG_ HVESP4AvailableChargePower : 16|16@1+ (0.05,0) [0|3212.75] "kW" Vector__XXX
SG_ HVESP4VoltageLevel : 32|16@1+ (0.05,0) [0|3212.75] "V" Vector__XXX
SG_ HVESP4Current : 48|16@1+ (0.05,-1600) [-1600|1612.75] "A" Vector__XXX

BO_ 2364653566 HVESP4D2: 8 Vector__XXX
SG_ HVESP4FastUpdateStateOfCharge : 0|16@1+ (0.0015625,0) [0|100.3984375] "%" Vector__XXX
SG_ HVESP4HighestCellVoltage : 16|16@1+ (0.001,0) [0|64.255] "V" Vector__XXX
SG_ HVESP4LowestCellVoltage : 32|16@1+ (0.001,0) [0|64.255] "V" Vector__XXX
SG_ HVESP4CellVoltageDiffStatus : 48|4@1+ (1,0) [0|15] "" Vector__XXX

BO_ 2364653822 HVESP4D3: 8 Vector__XXX
SG_ HVESP4HighestCellTemperature : 0|16@1+ (0.03125,-273) [-273|1734.96875] "deg C" Vector__XXX
SG_ HVESP4LowestCellTemperature : 16|16@1+ (0.03125,-273) [-273|1734.96875] "deg C" Vector__XXX
SG_ HVESP4AverageCellTemperature : 32|16@1+ (0.03125,-273) [-273|1734.96875] "deg C" Vector__XXX
SG_ HVESP4CellTemperatureDiffStatus : 48|2@1+ (1,0) [0|3] "" Vector__XXX

BO_ 2364654078 HVESP4D4: 8 Vector__XXX
SG_ HVESP4DischargeCapacity : 0|16@1+ (0.01,0) [0|642.55] "Ah" Vector__XXX
SG_ HVESP4ChargeCapacity : 16|16@1+ (0.01,0) [0|642.55] "Ah" Vector__XXX
SG_ HVESP4CellBalancingCount : 32|16@1+ (1,0) [0|64255] "" Vector__XXX

BO_ 2364654334 HVESP4D5: 8 Vector__XXX
SG_ HVESP4DischargeCurrentLimit : 0|16@1+ (0.05,-1600) [-1600|1612.75] "A" Vector__XXX
SG_ HVESP4ChargeCurrentLimit : 16|16@1+ (0.05,-1600) [-1600|1612.75] "A" Vector__XXX
SG_ HVESP4LowestCellStateOfCharge : 32|16@1+ (0.0015625,0) [0|100.3984375] "%" Vector__XXX
SG_ HVESP4HighestCellStateOfCharge : 48|16@1+ (0.0015625,0) [0|100.3984375] "%" Vector__XXX

BO_ 2364654590 HVESP4D6: 8 Vector__XXX
SG_ HVESP4BusVoltage : 0|16@1+ (0.05,0) [0|3212.75] "V" Vector__XXX
SG_ HVESP4IgnitionVoltage : 16|16@1+ (0.01,0) [0|642.55] "V" Vector__XXX
SG_ HVESP4IntakeCoolantTemperature : 32|8@1+ (1,-40) [-40|210] "deg C" Vector__XXX
SG_ HVESP4OutletCoolantTemperature : 40|8@1+ (1,-40) [-40|210] "deg C" Vector__XXX
SG_ HVESP4ElectronicsTemperature : 48|8@1+ (1,-40) [-40|210] "deg C" Vector__XXX
SG_ HVESP4Temperature : 56|8@1+ (1,-40) [-40|210] "deg C" Vector__XXX

BO_ 2364654846 HVESP4S1: 8 Vector__XXX
SG_ HVESP4HghVoltageBusPosContctStat : 0|2@1+ (1,0) [0|3] "" Vector__XXX
SG_ HVESP4HghVoltageBusNegContctStat : 2|2@1+ (1,0) [0|3] "" Vector__XXX
SG_ HVESP4HghVltgBusDiscnnctFrwrng : 4|4@1+ (1,0) [0|15] "" Vector__XXX
SG_ HVESP4HghVltgBusPreChrgRelyStat : 8|2@1+ (1,0) [0|3] "" Vector__XXX
SG_ HVESP4CenterOfPackContactorState : 10|2@1+ (1,0) [0|3] "" Vector__XXX
SG_ HVESP4HiVltgBusActIsoltnTestStat : 12|4@1+ (1,0) [0|15] "" Vector__XXX
SG_ HVESP4HiVltgBusPassIsoltnTestSt : 16|4@1+ (1,0) [0|15] "" Vector__XXX
SG_ HVESP4HVILStatus : 20|2@1+ (1,0) [0|3] "" Vector__XXX
SG_ HVESP4InertiaSwitchStatus : 22|2@1+ (1,0) [0|3] "" Vector__XXX
SG_ HVESP4StateOfChargeStatus : 24|4@1+ (1,0) [0|15] "" Vector__XXX
SG_ HVESP4CellBalanceStatus : 28|2@1+ (1,0) [0|3] "" Vector__XXX
SG_ HVESP4CellBalancingActive : 30|2@1+ (1,0) [0|3] "" Vector__XXX
SG_ HVESP4InternalChargerStatus : 32|2@1+ (1,0) [0|3] "" Vector__XXX
SG_ HVESP4HghVoltageBusConnectnStat : 40|4@1+ (1,0) [0|15] "" Vector__XXX
SG_ HVESP4OperationalStatus : 44|4@1+ (1,0) [0|15] "" Vector__XXX

BO_ 2364655102 HVESP4D7: 8 Vector__XXX
SG_ HVESP4DischargeEnergyCapacity : 0|24@1+ (0.001,0) [0|16449.535] "kWh" Vector__XXX
SG_ HVESP4ChargeEnergyCapacity : 24|24@1+ (0.001,0) [0|16449.535] "kWh" Vector__XXX
SG_ HVESP4MaximumChargeVoltageLimit : 48|16@1+ (0.05,0) [0|3212.75] "V" Vector__XXX

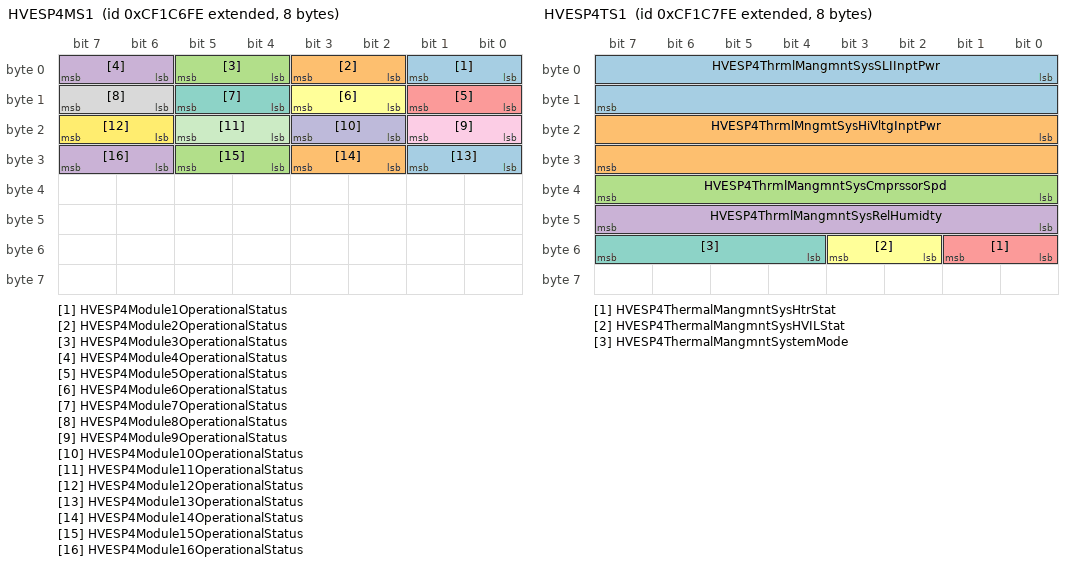
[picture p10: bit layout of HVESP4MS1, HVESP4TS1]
BO_ 2364655358 HVESP4MS1: 8 Vector__XXX
SG_ HVESP4Module1OperationalStatus : 0|2@1+ (1,0) [0|3] "" Vector__XXX
SG_ HVESP4Module2OperationalStatus : 2|2@1+ (1,0) [0|3] "" Vector__XXX
SG_ HVESP4Module3OperationalStatus : 4|2@1+ (1,0) [0|3] "" Vector__XXX
SG_ HVESP4Module4OperationalStatus : 6|2@1+ (1,0) [0|3] "" Vector__XXX
SG_ HVESP4Module5OperationalStatus : 8|2@1+ (1,0) [0|3] "" Vector__XXX
SG_ HVESP4Module6OperationalStatus : 10|2@1+ (1,0) [0|3] "" Vector__XXX
SG_ HVESP4Module7OperationalStatus : 12|2@1+ (1,0) [0|3] "" Vector__XXX
SG_ HVESP4Module8OperationalStatus : 14|2@1+ (1,0) [0|3] "" Vector__XXX
SG_ HVESP4Module9OperationalStatus : 16|2@1+ (1,0) [0|3] "" Vector__XXX
SG_ HVESP4Module10OperationalStatus : 18|2@1+ (1,0) [0|3] "" Vector__XXX
SG_ HVESP4Module11OperationalStatus : 20|2@1+ (1,0) [0|3] "" Vector__XXX
SG_ HVESP4Module12OperationalStatus : 22|2@1+ (1,0) [0|3] "" Vector__XXX
SG_ HVESP4Module13OperationalStatus : 24|2@1+ (1,0) [0|3] "" Vector__XXX
SG_ HVESP4Module14OperationalStatus : 26|2@1+ (1,0) [0|3] "" Vector__XXX
SG_ HVESP4Module15OperationalStatus : 28|2@1+ (1,0) [0|3] "" Vector__XXX
SG_ HVESP4Module16OperationalStatus : 30|2@1+ (1,0) [0|3] "" Vector__XXX

BO_ 2364655614 HVESP4TS1: 8 Vector__XXX
SG_ HVESP4ThrmlMangmntSysSLIInptPwr : 0|16@1+ (0.5,0) [0|32127.5] "W" Vector__XXX
SG_ HVESP4ThrmlMngmtSysHiVltgInptPwr : 16|16@1+ (0.5,0) [0|32127.5] "W" Vector__XXX
SG_ HVESP4ThrmlMangmntSysCmprssorSpd : 32|8@1+ (32,0) [0|8000] "rpm" Vector__XXX
SG_ HVESP4ThrmlMangmntSysRelHumidty : 40|8@1+ (0.4,0) [0|100] "%" Vector__XXX
SG_ HVESP4ThermalMangmntSysHtrStat : 48|2@1+ (1,0) [0|3] "" Vector__XXX
SG_ HVESP4ThermalMangmntSysHVILStat : 50|2@1+ (1,0) [0|3] "" Vector__XXX
SG_ HVESP4ThermalMangmntSystemMode : 52|4@1+ (1,0) [0|15] "" Vector__XXX

BO_ 2364655870 HVESP4D8: 8 Vector__XXX
SG_ HVESP4HghestCellVoltageMdulNo : 0|8@1+ (1,0) [0|250] "" Vector__XXX
SG_ HVESP4HghestCellVoltageCellNo : 8|8@1+ (1,0) [0|250] "" Vector__XXX
SG_ HVESP4LowestCellVoltageMdulNo : 16|8@1+ (1,0) [0|250] "" Vector__XXX
SG_ HVESP4LowestCellVoltageCellNo : 24|8@1+ (1,0) [0|250] "" Vector__XXX
SG_ HVESP4AverageCellVoltage : 32|16@1+ (0.001,0) [0|64.255] "V" Vector__XXX

BO_ 2364656126 HVESP4D9: 8 Vector__XXX
SG_ HVESP4HghestCellTempMdulNo : 0|8@1+ (1,0) [0|250] "" Vector__XXX
SG_ HVESP4HghestCellTempCellNo : 8|8@1+ (1,0) [0|250] "" Vector__XXX
SG_ HVESP4LowestCellTempMdulNo : 16|8@1+ (1,0) [0|250] "" Vector__XXX
SG_ HVESP4LowestCellTempCellNo : 24|8@1+ (1,0) [0|250] "" Vector__XXX

BO_ 2364656382 HVESP4D10: 8 Vector__XXX
SG_ HVESP4HghestCellStateChrgMdulNo : 0|8@1+ (1,0) [0|250] "" Vector__XXX
SG_ HVESP4HghestCellStateChrgCellNo : 8|8@1+ (1,0) [0|250] "" Vector__XXX
SG_ HVESP4LowestCellStateChrgMdulNo : 16|8@1+ (1,0) [0|250] "" Vector__XXX
SG_ HVESP4LowestCellStateChrgCellNo : 24|8@1+ (1,0) [0|250] "" Vector__XXX
SG_ HVESP4HiVltgBusActIsoltnTestRess : 32|16@1+ (0.1,0) [0|6425.5] "ohm/V" Vector__XXX
SG_ HVESP4HiVltgBusPassIsoltnTtRess : 48|16@1+ (0.1,0) [0|6425.5] "ohm/V" Vector__XXX

BO_ 2364656638 HVESP4D11: 8 Vector__XXX
SG_ HVESP4BusVltgNegToChssGrndVltg : 0|16@1+ (0.05,0) [0|3212.75] "V" Vector__XXX
SG_ HVESP4VltgLvlNegToChssGrndVltg : 16|16@1+ (0.05,0) [0|3212.75] "V" Vector__XXX

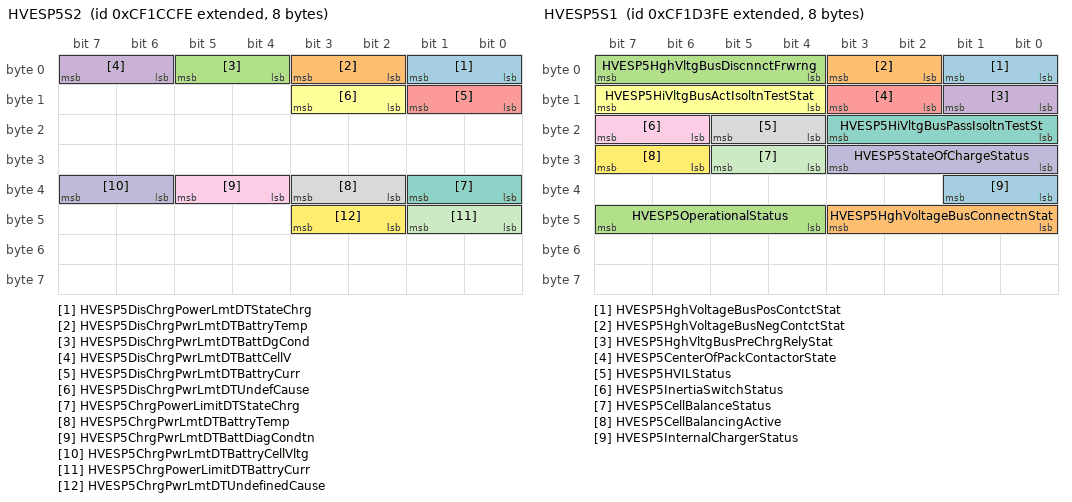
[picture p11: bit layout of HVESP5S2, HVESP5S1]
BO_ 2364656894 HVESP5S2: 8 Vector__XXX
SG_ HVESP5DisChrgPowerLmtDTStateChrg : 0|2@1+ (1,0) [0|3] "" Vector__XXX
SG_ HVESP5DisChrgPwrLmtDTBattryTemp : 2|2@1+ (1,0) [0|3] "" Vector__XXX
SG_ HVESP5DisChrgPwrLmtDTBattDgCond : 4|2@1+ (1,0) [0|3] "" Vector__XXX
SG_ HVESP5DisChrgPwrLmtDTBattCellV : 6|2@1+ (1,0) [0|3] "" Vector__XXX
SG_ HVESP5DisChrgPwrLmtDTBattryCurr : 8|2@1+ (1,0) [0|3] "" Vector__XXX
SG_ HVESP5DisChrgPwrLmtDTUndefCause : 10|2@1+ (1,0) [0|3] "" Vector__XXX
SG_ HVESP5ChrgPowerLimitDTStateChrg : 32|2@1+ (1,0) [0|3] "" Vector__XXX
SG_ HVESP5ChrgPwrLmtDTBattryTemp : 34|2@1+ (1,0) [0|3] "" Vector__XXX
SG_ HVESP5ChrgPwrLmtDTBattDiagCondtn : 36|2@1+ (1,0) [0|3] "" Vector__XXX
SG_ HVESP5ChrgPwrLmtDTBattryCellVltg : 38|2@1+ (1,0) [0|3] "" Vector__XXX
SG_ HVESP5ChrgPowerLimitDTBattryCurr : 40|2@1+ (1,0) [0|3] "" Vector__XXX
SG_ HVESP5ChrgPwrLmtDTUndefinedCause : 42|2@1+ (1,0) [0|3] "" Vector__XXX

BO_ 2364657150 HVESP5D1: 8 Vector__XXX
SG_ HVESP5AvailableDischargePower : 0|16@1+ (0.05,0) [0|3212.75] "kW" Vector__XXX
SG_ HVESP5AvailableChargePower : 16|16@1+ (0.05,0) [0|3212.75] "kW" Vector__XXX
SG_ HVESP5VoltageLevel : 32|16@1+ (0.05,0) [0|3212.75] "V" Vector__XXX
SG_ HVESP5Current : 48|16@1+ (0.05,-1600) [-1600|1612.75] "A" Vector__XXX

BO_ 2364657406 HVESP5D2: 8 Vector__XXX
SG_ HVESP5FastUpdateStateOfCharge : 0|16@1+ (0.0015625,0) [0|100.3984375] "%" Vector__XXX
SG_ HVESP5HighestCellVoltage : 16|16@1+ (0.001,0) [0|64.255] "V" Vector__XXX
SG_ HVESP5LowestCellVoltage : 32|16@1+ (0.001,0) [0|64.255] "V" Vector__XXX
SG_ HVESP5CellVoltageDiffStatus : 48|4@1+ (1,0) [0|15] "" Vector__XXX

BO_ 2364657662 HVESP5D3: 8 Vector__XXX
SG_ HVESP5HighestCellTemperature : 0|16@1+ (0.03125,-273) [-273|1734.96875] "deg C" Vector__XXX
SG_ HVESP5LowestCellTemperature : 16|16@1+ (0.03125,-273) [-273|1734.96875] "deg C" Vector__XXX
SG_ HVESP5AverageCellTemperature : 32|16@1+ (0.03125,-273) [-273|1734.96875] "deg C" Vector__XXX
SG_ HVESP5CellTemperatureDiffStatus : 48|2@1+ (1,0) [0|3] "" Vector__XXX

BO_ 2364657918 HVESP5D4: 8 Vector__XXX
SG_ HVESP5DischargeCapacity : 0|16@1+ (0.01,0) [0|642.55] "Ah" Vector__XXX
SG_ HVESP5ChargeCapacity : 16|16@1+ (0.01,0) [0|642.55] "Ah" Vector__XXX
SG_ HVESP5CellBalancingCount : 32|16@1+ (1,0) [0|64255] "" Vector__XXX

BO_ 2364658174 HVESP5D5: 8 Vector__XXX
SG_ HVESP5DischargeCurrentLimit : 0|16@1+ (0.05,-1600) [-1600|1612.75] "A" Vector__XXX
SG_ HVESP5ChargeCurrentLimit : 16|16@1+ (0.05,-1600) [-1600|1612.75] "A" Vector__XXX
SG_ HVESP5LowestCellStateOfCharge : 32|16@1+ (0.0015625,0) [0|100.3984375] "%" Vector__XXX
SG_ HVESP5HighestCellStateOfCharge : 48|16@1+ (0.0015625,0) [0|100.3984375] "%" Vector__XXX

BO_ 2364658430 HVESP5D6: 8 Vector__XXX
SG_ HVESP5BusVoltage : 0|16@1+ (0.05,0) [0|3212.75] "V" Vector__XXX
SG_ HVESP5IgnitionVoltage : 16|16@1+ (0.01,0) [0|642.55] "V" Vector__XXX
SG_ HVESP5IntakeCoolantTemperature : 32|8@1+ (1,-40) [-40|210] "deg C" Vector__XXX
SG_ HVESP5OutletCoolantTemperature : 40|8@1+ (1,-40) [-40|210] "deg C" Vector__XXX
SG_ HVESP5ElectronicsTemperature : 48|8@1+ (1,-40) [-40|210] "deg C" Vector__XXX
SG_ HVESP5Temperature : 56|8@1+ (1,-40) [-40|210] "deg C" Vector__XXX

BO_ 2364658686 HVESP5S1: 8 Vector__XXX
SG_ HVESP5HghVoltageBusPosContctStat : 0|2@1+ (1,0) [0|3] "" Vector__XXX
SG_ HVESP5HghVoltageBusNegContctStat : 2|2@1+ (1,0) [0|3] "" Vector__XXX
SG_ HVESP5HghVltgBusDiscnnctFrwrng : 4|4@1+ (1,0) [0|15] "" Vector__XXX
SG_ HVESP5HghVltgBusPreChrgRelyStat : 8|2@1+ (1,0) [0|3] "" Vector__XXX
SG_ HVESP5CenterOfPackContactorState : 10|2@1+ (1,0) [0|3] "" Vector__XXX
SG_ HVESP5HiVltgBusActIsoltnTestStat : 12|4@1+ (1,0) [0|15] "" Vector__XXX
SG_ HVESP5HiVltgBusPassIsoltnTestSt : 16|4@1+ (1,0) [0|15] "" Vector__XXX
SG_ HVESP5HVILStatus : 20|2@1+ (1,0) [0|3] "" Vector__XXX
SG_ HVESP5InertiaSwitchStatus : 22|2@1+ (1,0) [0|3] "" Vector__XXX
SG_ HVESP5StateOfChargeStatus : 24|4@1+ (1,0) [0|15] "" Vector__XXX
SG_ HVESP5CellBalanceStatus : 28|2@1+ (1,0) [0|3] "" Vector__XXX
SG_ HVESP5CellBalancingActive : 30|2@1+ (1,0) [0|3] "" Vector__XXX
SG_ HVESP5InternalChargerStatus : 32|2@1+ (1,0) [0|3] "" Vector__XXX
SG_ HVESP5HghVoltageBusConnectnStat : 40|4@1+ (1,0) [0|15] "" Vector__XXX
SG_ HVESP5OperationalStatus : 44|4@1+ (1,0) [0|15] "" Vector__XXX

BO_ 2364658942 HVESP5D7: 8 Vector__XXX
SG_ HVESP5DischargeEnergyCapacity : 0|24@1+ (0.001,0) [0|16449.535] "kWh" Vector__XXX
SG_ HVESP5ChargeEnergyCapacity : 24|24@1+ (0.001,0) [0|16449.535] "kWh" Vector__XXX
SG_ HVESP5MaximumChargeVoltageLimit : 48|16@1+ (0.05,0) [0|3212.75] "V" Vector__XXX

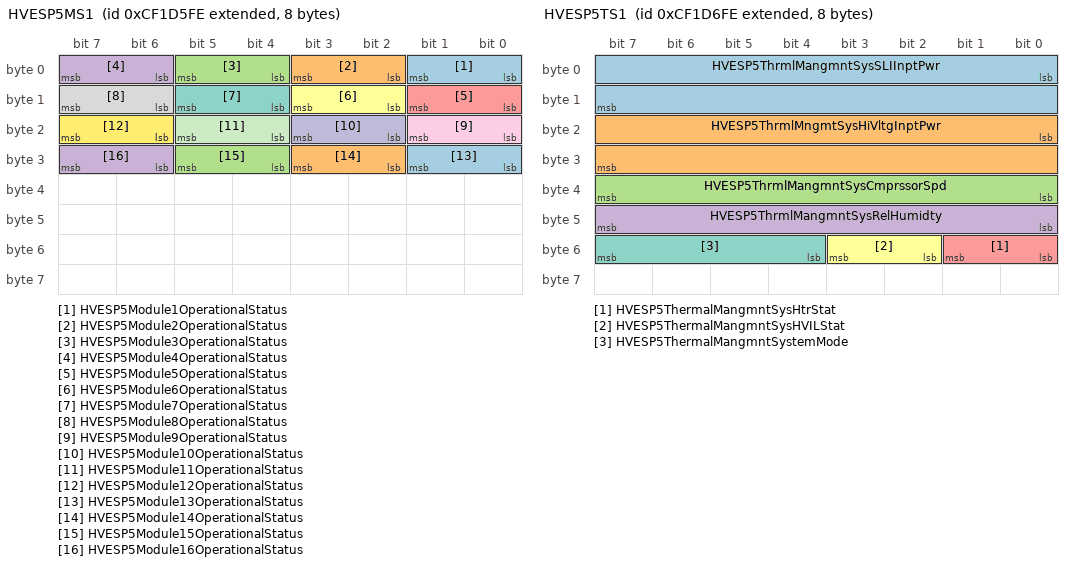
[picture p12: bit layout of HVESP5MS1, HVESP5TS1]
BO_ 2364659198 HVESP5MS1: 8 Vector__XXX
SG_ HVESP5Module1OperationalStatus : 0|2@1+ (1,0) [0|3] "" Vector__XXX
SG_ HVESP5Module2OperationalStatus : 2|2@1+ (1,0) [0|3] "" Vector__XXX
SG_ HVESP5Module3OperationalStatus : 4|2@1+ (1,0) [0|3] "" Vector__XXX
SG_ HVESP5Module4OperationalStatus : 6|2@1+ (1,0) [0|3] "" Vector__XXX
SG_ HVESP5Module5OperationalStatus : 8|2@1+ (1,0) [0|3] "" Vector__XXX
SG_ HVESP5Module6OperationalStatus : 10|2@1+ (1,0) [0|3] "" Vector__XXX
SG_ HVESP5Module7OperationalStatus : 12|2@1+ (1,0) [0|3] "" Vector__XXX
SG_ HVESP5Module8OperationalStatus : 14|2@1+ (1,0) [0|3] "" Vector__XXX
SG_ HVESP5Module9OperationalStatus : 16|2@1+ (1,0) [0|3] "" Vector__XXX
SG_ HVESP5Module10OperationalStatus : 18|2@1+ (1,0) [0|3] "" Vector__XXX
SG_ HVESP5Module11OperationalStatus : 20|2@1+ (1,0) [0|3] "" Vector__XXX
SG_ HVESP5Module12OperationalStatus : 22|2@1+ (1,0) [0|3] "" Vector__XXX
SG_ HVESP5Module13OperationalStatus : 24|2@1+ (1,0) [0|3] "" Vector__XXX
SG_ HVESP5Module14OperationalStatus : 26|2@1+ (1,0) [0|3] "" Vector__XXX
SG_ HVESP5Module15OperationalStatus : 28|2@1+ (1,0) [0|3] "" Vector__XXX
SG_ HVESP5Module16OperationalStatus : 30|2@1+ (1,0) [0|3] "" Vector__XXX

BO_ 2364659454 HVESP5TS1: 8 Vector__XXX
SG_ HVESP5ThrmlMangmntSysSLIInptPwr : 0|16@1+ (0.5,0) [0|32127.5] "W" Vector__XXX
SG_ HVESP5ThrmlMngmtSysHiVltgInptPwr : 16|16@1+ (0.5,0) [0|32127.5] "W" Vector__XXX
SG_ HVESP5ThrmlMangmntSysCmprssorSpd : 32|8@1+ (32,0) [0|8000] "rpm" Vector__XXX
SG_ HVESP5ThrmlMangmntSysRelHumidty : 40|8@1+ (0.4,0) [0|100] "%" Vector__XXX
SG_ HVESP5ThermalMangmntSysHtrStat : 48|2@1+ (1,0) [0|3] "" Vector__XXX
SG_ HVESP5ThermalMangmntSysHVILStat : 50|2@1+ (1,0) [0|3] "" Vector__XXX
SG_ HVESP5ThermalMangmntSystemMode : 52|4@1+ (1,0) [0|15] "" Vector__XXX

BO_ 2364659710 HVESP5D8: 8 Vector__XXX
SG_ HVESP5HghestCellVoltageMdulNo : 0|8@1+ (1,0) [0|250] "" Vector__XXX
SG_ HVESP5HghestCellVoltageCellNo : 8|8@1+ (1,0) [0|250] "" Vector__XXX
SG_ HVESP5LowestCellVoltageMdulNo : 16|8@1+ (1,0) [0|250] "" Vector__XXX
SG_ HVESP5LowestCellVoltageCellNo : 24|8@1+ (1,0) [0|250] "" Vector__XXX
SG_ HVESP5AverageCellVoltage : 32|16@1+ (0.001,0) [0|64.255] "V" Vector__XXX

BO_ 2364659966 HVESP5D9: 8 Vector__XXX
SG_ HVESP5HghestCellTempMdulNo : 0|8@1+ (1,0) [0|250] "" Vector__XXX
SG_ HVESP5HghestCellTempCellNo : 8|8@1+ (1,0) [0|250] "" Vector__XXX
SG_ HVESP5LowestCellTempMdulNo : 16|8@1+ (1,0) [0|250] "" Vector__XXX
SG_ HVESP5LowestCellTempCellNo : 24|8@1+ (1,0) [0|250] "" Vector__XXX

BO_ 2364660222 HVESP5D10: 8 Vector__XXX
SG_ HVESP5HghestCellStateChrgMdulNo : 0|8@1+ (1,0) [0|250] "" Vector__XXX
SG_ HVESP5HghestCellStateChrgCellNo : 8|8@1+ (1,0) [0|250] "" Vector__XXX
SG_ HVESP5LowestCellStateChrgMdulNo : 16|8@1+ (1,0) [0|250] "" Vector__XXX
SG_ HVESP5LowestCellStateChrgCellNo : 24|8@1+ (1,0) [0|250] "" Vector__XXX
SG_ HVESP5HiVltgBusActIsoltnTestRess : 32|16@1+ (0.1,0) [0|6425.5] "ohm/V" Vector__XXX
SG_ HVESP5HiVltgBusPassIsoltnTtRess : 48|16@1+ (0.1,0) [0|6425.5] "ohm/V" Vector__XXX

BO_ 2364660478 HVESP5D11: 8 Vector__XXX
SG_ HVESP5BusVltgNegToChssGrndVltg : 0|16@1+ (0.05,0) [0|3212.75] "V" Vector__XXX
SG_ HVESP5VltgLvlNegToChssGrndVltg : 16|16@1+ (0.05,0) [0|3212.75] "V" Vector__XXX

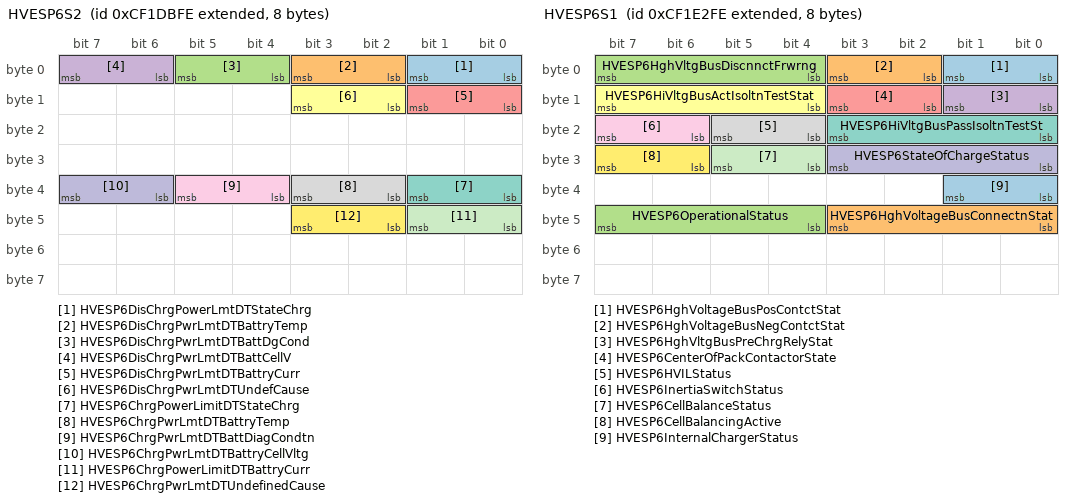
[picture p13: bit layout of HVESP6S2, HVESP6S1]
BO_ 2364660734 HVESP6S2: 8 Vector__XXX
SG_ HVESP6DisChrgPowerLmtDTStateChrg : 0|2@1+ (1,0) [0|3] "" Vector__XXX
SG_ HVESP6DisChrgPwrLmtDTBattryTemp : 2|2@1+ (1,0) [0|3] "" Vector__XXX
SG_ HVESP6DisChrgPwrLmtDTBattDgCond : 4|2@1+ (1,0) [0|3] "" Vector__XXX
SG_ HVESP6DisChrgPwrLmtDTBattCellV : 6|2@1+ (1,0) [0|3] "" Vector__XXX
SG_ HVESP6DisChrgPwrLmtDTBattryCurr : 8|2@1+ (1,0) [0|3] "" Vector__XXX
SG_ HVESP6DisChrgPwrLmtDTUndefCause : 10|2@1+ (1,0) [0|3] "" Vector__XXX
SG_ HVESP6ChrgPowerLimitDTStateChrg : 32|2@1+ (1,0) [0|3] "" Vector__XXX
SG_ HVESP6ChrgPwrLmtDTBattryTemp : 34|2@1+ (1,0) [0|3] "" Vector__XXX
SG_ HVESP6ChrgPwrLmtDTBattDiagCondtn : 36|2@1+ (1,0) [0|3] "" Vector__XXX
SG_ HVESP6ChrgPwrLmtDTBattryCellVltg : 38|2@1+ (1,0) [0|3] "" Vector__XXX
SG_ HVESP6ChrgPowerLimitDTBattryCurr : 40|2@1+ (1,0) [0|3] "" Vector__XXX
SG_ HVESP6ChrgPwrLmtDTUndefinedCause : 42|2@1+ (1,0) [0|3] "" Vector__XXX

BO_ 2364660990 HVESP6D1: 8 Vector__XXX
SG_ HVESP6AvailableDischargePower : 0|16@1+ (0.05,0) [0|3212.75] "kW" Vector__XXX
SG_ HVESP6AvailableChargePower : 16|16@1+ (0.05,0) [0|3212.75] "kW" Vector__XXX
SG_ HVESP6VoltageLevel : 32|16@1+ (0.05,0) [0|3212.75] "V" Vector__XXX
SG_ HVESP6Current : 48|16@1+ (0.05,-1600) [-1600|1612.75] "A" Vector__XXX

BO_ 2364661246 HVESP6D2: 8 Vector__XXX
SG_ HVESP6FastUpdateStateOfCharge : 0|16@1+ (0.0015625,0) [0|100.3984375] "%" Vector__XXX
SG_ HVESP6HighestCellVoltage : 16|16@1+ (0.001,0) [0|64.255] "V" Vector__XXX
SG_ HVESP6LowestCellVoltage : 32|16@1+ (0.001,0) [0|64.255] "V" Vector__XXX
SG_ HVESP6CellVoltageDiffStatus : 48|4@1+ (1,0) [0|15] "" Vector__XXX

BO_ 2364661502 HVESP6D3: 8 Vector__XXX
SG_ HVESP6HighestCellTemperature : 0|16@1+ (0.03125,-273) [-273|1734.96875] "deg C" Vector__XXX
SG_ HVESP6LowestCellTemperature : 16|16@1+ (0.03125,-273) [-273|1734.96875] "deg C" Vector__XXX
SG_ HVESP6AverageCellTemperature : 32|16@1+ (0.03125,-273) [-273|1734.96875] "deg C" Vector__XXX
SG_ HVESP6CellTemperatureDiffStatus : 48|2@1+ (1,0) [0|3] "" Vector__XXX

BO_ 2364661758 HVESP6D4: 8 Vector__XXX
SG_ HVESP6DischargeCapacity : 0|16@1+ (0.01,0) [0|642.55] "Ah" Vector__XXX
SG_ HVESP6ChargeCapacity : 16|16@1+ (0.01,0) [0|642.55] "Ah" Vector__XXX
SG_ HVESP6CellBalancingCount : 32|16@1+ (1,0) [0|64255] "" Vector__XXX

BO_ 2364662014 HVESP6D5: 8 Vector__XXX
SG_ HVESP6DischargeCurrentLimit : 0|16@1+ (0.05,-1600) [-1600|1612.75] "A" Vector__XXX
SG_ HVESP6ChargeCurrentLimit : 16|16@1+ (0.05,-1600) [-1600|1612.75] "A" Vector__XXX
SG_ HVESP6LowestCellStateOfCharge : 32|16@1+ (0.0015625,0) [0|100.3984375] "%" Vector__XXX
SG_ HVESP6HighestCellStateOfCharge : 48|16@1+ (0.0015625,0) [0|100.3984375] "%" Vector__XXX

BO_ 2364662270 HVESP6D6: 8 Vector__XXX
SG_ HVESP6BusVoltage : 0|16@1+ (0.05,0) [0|3212.75] "V" Vector__XXX
SG_ HVESP6IgnitionVoltage : 16|16@1+ (0.01,0) [0|642.55] "V" Vector__XXX
SG_ HVESP6IntakeCoolantTemperature : 32|8@1+ (1,-40) [-40|210] "deg C" Vector__XXX
SG_ HVESP6OutletCoolantTemperature : 40|8@1+ (1,-40) [-40|210] "deg C" Vector__XXX
SG_ HVESP6ElectronicsTemperature : 48|8@1+ (1,-40) [-40|210] "deg C" Vector__XXX
SG_ HVESP6Temperature : 56|8@1+ (1,-40) [-40|210] "deg C" Vector__XXX

BO_ 2364662526 HVESP6S1: 8 Vector__XXX
SG_ HVESP6HghVoltageBusPosContctStat : 0|2@1+ (1,0) [0|3] "" Vector__XXX
SG_ HVESP6HghVoltageBusNegContctStat : 2|2@1+ (1,0) [0|3] "" Vector__XXX
SG_ HVESP6HghVltgBusDiscnnctFrwrng : 4|4@1+ (1,0) [0|15] "" Vector__XXX
SG_ HVESP6HghVltgBusPreChrgRelyStat : 8|2@1+ (1,0) [0|3] "" Vector__XXX
SG_ HVESP6CenterOfPackContactorState : 10|2@1+ (1,0) [0|3] "" Vector__XXX
SG_ HVESP6HiVltgBusActIsoltnTestStat : 12|4@1+ (1,0) [0|15] "" Vector__XXX
SG_ HVESP6HiVltgBusPassIsoltnTestSt : 16|4@1+ (1,0) [0|15] "" Vector__XXX
SG_ HVESP6HVILStatus : 20|2@1+ (1,0) [0|3] "" Vector__XXX
SG_ HVESP6InertiaSwitchStatus : 22|2@1+ (1,0) [0|3] "" Vector__XXX
SG_ HVESP6StateOfChargeStatus : 24|4@1+ (1,0) [0|15] "" Vector__XXX
SG_ HVESP6CellBalanceStatus : 28|2@1+ (1,0) [0|3] "" Vector__XXX
SG_ HVESP6CellBalancingActive : 30|2@1+ (1,0) [0|3] "" Vector__XXX
SG_ HVESP6InternalChargerStatus : 32|2@1+ (1,0) [0|3] "" Vector__XXX
SG_ HVESP6HghVoltageBusConnectnStat : 40|4@1+ (1,0) [0|15] "" Vector__XXX
SG_ HVESP6OperationalStatus : 44|4@1+ (1,0) [0|15] "" Vector__XXX

BO_ 2364662782 HVESP6D7: 8 Vector__XXX
SG_ HVESP6DischargeEnergyCapacity : 0|24@1+ (0.001,0) [0|16449.535] "kWh" Vector__XXX
SG_ HVESP6ChargeEnergyCapacity : 24|24@1+ (0.001,0) [0|16449.535] "kWh" Vector__XXX
SG_ HVESP6MaximumChargeVoltageLimit : 48|16@1+ (0.05,0) [0|3212.75] "V" Vector__XXX

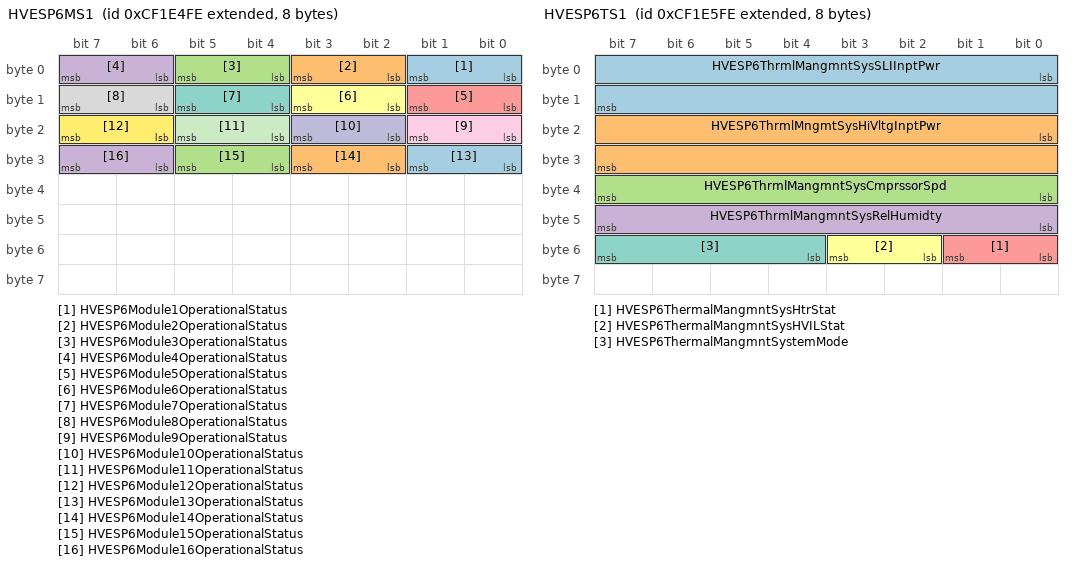
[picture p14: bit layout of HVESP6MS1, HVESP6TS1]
BO_ 2364663038 HVESP6MS1: 8 Vector__XXX
SG_ HVESP6Module1OperationalStatus : 0|2@1+ (1,0) [0|3] "" Vector__XXX
SG_ HVESP6Module2OperationalStatus : 2|2@1+ (1,0) [0|3] "" Vector__XXX
SG_ HVESP6Module3OperationalStatus : 4|2@1+ (1,0) [0|3] "" Vector__XXX
SG_ HVESP6Module4OperationalStatus : 6|2@1+ (1,0) [0|3] "" Vector__XXX
SG_ HVESP6Module5OperationalStatus : 8|2@1+ (1,0) [0|3] "" Vector__XXX
SG_ HVESP6Module6OperationalStatus : 10|2@1+ (1,0) [0|3] "" Vector__XXX
SG_ HVESP6Module7OperationalStatus : 12|2@1+ (1,0) [0|3] "" Vector__XXX
SG_ HVESP6Module8OperationalStatus : 14|2@1+ (1,0) [0|3] "" Vector__XXX
SG_ HVESP6Module9OperationalStatus : 16|2@1+ (1,0) [0|3] "" Vector__XXX
SG_ HVESP6Module10OperationalStatus : 18|2@1+ (1,0) [0|3] "" Vector__XXX
SG_ HVESP6Module11OperationalStatus : 20|2@1+ (1,0) [0|3] "" Vector__XXX
SG_ HVESP6Module12OperationalStatus : 22|2@1+ (1,0) [0|3] "" Vector__XXX
SG_ HVESP6Module13OperationalStatus : 24|2@1+ (1,0) [0|3] "" Vector__XXX
SG_ HVESP6Module14OperationalStatus : 26|2@1+ (1,0) [0|3] "" Vector__XXX
SG_ HVESP6Module15OperationalStatus : 28|2@1+ (1,0) [0|3] "" Vector__XXX
SG_ HVESP6Module16OperationalStatus : 30|2@1+ (1,0) [0|3] "" Vector__XXX

BO_ 2364663294 HVESP6TS1: 8 Vector__XXX
SG_ HVESP6ThrmlMangmntSysSLIInptPwr : 0|16@1+ (0.5,0) [0|32127.5] "W" Vector__XXX
SG_ HVESP6ThrmlMngmtSysHiVltgInptPwr : 16|16@1+ (0.5,0) [0|32127.5] "W" Vector__XXX
SG_ HVESP6ThrmlMangmntSysCmprssorSpd : 32|8@1+ (32,0) [0|8000] "rpm" Vector__XXX
SG_ HVESP6ThrmlMangmntSysRelHumidty : 40|8@1+ (0.4,0) [0|100] "%" Vector__XXX
SG_ HVESP6ThermalMangmntSysHtrStat : 48|2@1+ (1,0) [0|3] "" Vector__XXX
SG_ HVESP6ThermalMangmntSysHVILStat : 50|2@1+ (1,0) [0|3] "" Vector__XXX
SG_ HVESP6ThermalMangmntSystemMode : 52|4@1+ (1,0) [0|15] "" Vector__XXX

BO_ 2364663550 HVESP6D8: 8 Vector__XXX
SG_ HVESP6HghestCellVoltageMdulNo : 0|8@1+ (1,0) [0|250] "" Vector__XXX
SG_ HVESP6HghestCellVoltageCellNo : 8|8@1+ (1,0) [0|250] "" Vector__XXX
SG_ HVESP6LowestCellVoltageMdulNo : 16|8@1+ (1,0) [0|250] "" Vector__XXX
SG_ HVESP6LowestCellVoltageCellNo : 24|8@1+ (1,0) [0|250] "" Vector__XXX
SG_ HVESP6AverageCellVoltage : 32|16@1+ (0.001,0) [0|64.255] "V" Vector__XXX

BO_ 2364663806 HVESP6D9: 8 Vector__XXX
SG_ HVESP6HghestCellTempMdulNo : 0|8@1+ (1,0) [0|250] "" Vector__XXX
SG_ HVESP6HghestCellTempCellNo : 8|8@1+ (1,0) [0|250] "" Vector__XXX
SG_ HVESP6LowestCellTempMdulNo : 16|8@1+ (1,0) [0|250] "" Vector__XXX
SG_ HVESP6LowestCellTempCellNo : 24|8@1+ (1,0) [0|250] "" Vector__XXX

BO_ 2364664062 HVESP6D10: 8 Vector__XXX
SG_ HVESP6HghestCellStateChrgMdulNo : 0|8@1+ (1,0) [0|250] "" Vector__XXX
SG_ HVESP6HghestCellStateChrgCellNo : 8|8@1+ (1,0) [0|250] "" Vector__XXX
SG_ HVESP6LowestCellStateChrgMdulNo : 16|8@1+ (1,0) [0|250] "" Vector__XXX
SG_ HVESP6LowestCellStateChrgCellNo : 24|8@1+ (1,0) [0|250] "" Vector__XXX
SG_ HVESP6HiVltgBusActIsoltnTestRess : 32|16@1+ (0.1,0) [0|6425.5] "ohm/V" Vector__XXX
SG_ HVESP6HiVltgBusPassIsoltnTtRess : 48|16@1+ (0.1,0) [0|6425.5] "ohm/V" Vector__XXX

BO_ 2364664318 HVESP6D11: 8 Vector__XXX
SG_ HVESP6BusVltgNegToChssGrndVltg : 0|16@1+ (0.05,0) [0|3212.75] "V" Vector__XXX
SG_ HVESP6VltgLvlNegToChssGrndVltg : 16|16@1+ (0.05,0) [0|3212.75] "V" Vector__XXX

BO_ 2364664574 MG3IMF1: 8 Vector__XXX
SG_ MotorGen3InverterModeFdbck1CRC : 0|8@1+ (1,0) [0|255] "" Vector__XXX
SG_ MotorGen3InverterModeFdbck1Cntr : 8|4@1+ (1,0) [0|15] "" Vector__XXX
SG_ MtrGen3InvertCtrlLmtsOverrideMde : 12|4@1+ (1,0) [0|15] "" Vector__XXX
SG_ MotorGen3InvertCtrlSetpointMode : 16|5@1+ (1,0) [0|31] "" Vector__XXX
SG_ MotorGen3InverterHVILStatus : 21|2@1+ (1,0) [0|3] "" Vector__XXX

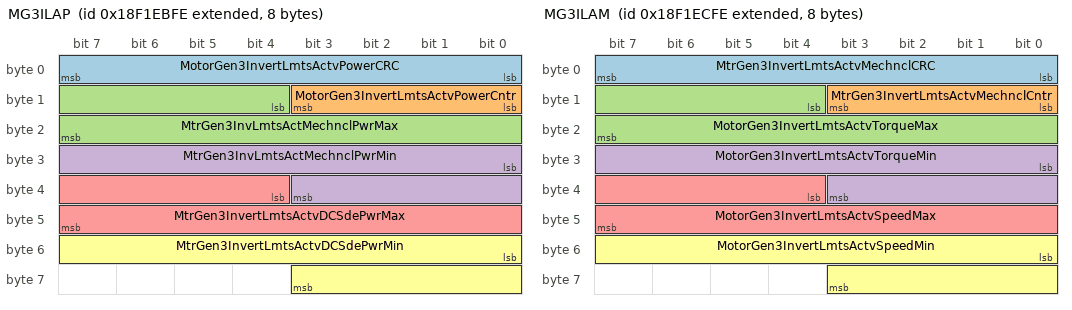
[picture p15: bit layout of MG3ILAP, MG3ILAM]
BO_ 2565991422 MG3ILAP: 8 Vector__XXX
SG_ MotorGen3InvertLmtsActvPowerCRC : 0|8@1+ (1,0) [0|255] "" Vector__XXX
SG_ MotorGen3InvertLmtsActvPowerCntr : 8|4@1+ (1,0) [0|15] "" Vector__XXX
SG_ MtrGen3InvLmtsActMechnclPwrMax : 12|12@1+ (0.0625,-125) [-125|125.9375] "%" Vector__XXX
SG_ MtrGen3InvLmtsActMechnclPwrMin : 24|12@1+ (0.0625,-125) [-125|125.9375] "%" Vector__XXX
SG_ MtrGen3InvertLmtsActvDCSdePwrMax : 36|12@1+ (0.0625,-125) [-125|125.9375] "%" Vector__XXX
SG_ MtrGen3InvertLmtsActvDCSdePwrMin : 48|12@1+ (0.0625,-125) [-125|125.9375] "%" Vector__XXX

BO_ 2565991678 MG3ILAM: 8 Vector__XXX
SG_ MtrGen3InvertLmtsActvMechnclCRC : 0|8@1+ (1,0) [0|255] "" Vector__XXX
SG_ MtrGen3InvertLmtsActvMechnclCntr : 8|4@1+ (1,0) [0|15] "" Vector__XXX
SG_ MotorGen3InvertLmtsActvTorqueMax : 12|12@1+ (0.0625,-125) [-125|125.9375] "%" Vector__XXX
SG_ MotorGen3InvertLmtsActvTorqueMin : 24|12@1+ (0.0625,-125) [-125|125.9375] "%" Vector__XXX
SG_ MotorGen3InvertLmtsActvSpeedMax : 36|12@1+ (0.0625,-125) [-125|125.9375] "%" Vector__XXX
SG_ MotorGen3InvertLmtsActvSpeedMin : 48|12@1+ (0.0625,-125) [-125|125.9375] "%" Vector__XXX

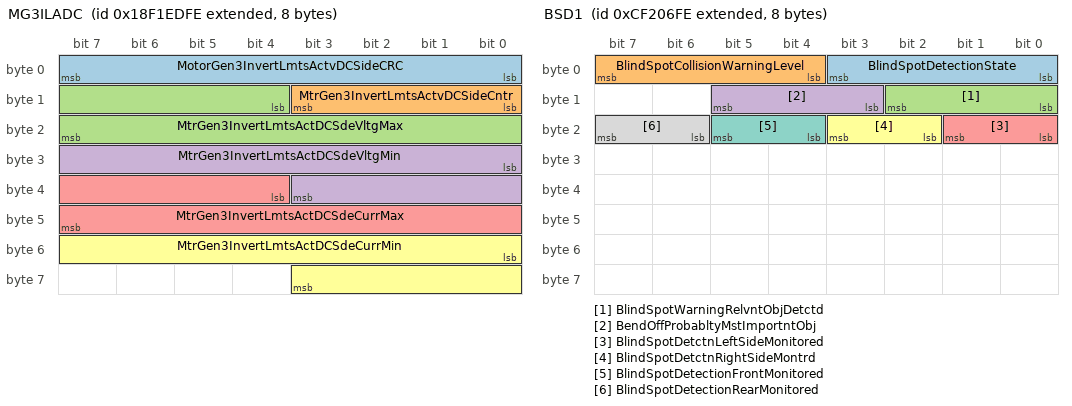
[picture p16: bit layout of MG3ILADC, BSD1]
BO_ 2565991934 MG3ILADC: 8 Vector__XXX
SG_ MotorGen3InvertLmtsActvDCSideCRC : 0|8@1+ (1,0) [0|255] "" Vector__XXX
SG_ MtrGen3InvertLmtsActvDCSideCntr : 8|4@1+ (1,0) [0|15] "" Vector__XXX
SG_ MtrGen3InvertLmtsActDCSdeVltgMax : 12|12@1+ (0.0625,-125) [-125|125.9375] "%" Vector__XXX
SG_ MtrGen3InvertLmtsActDCSdeVltgMin : 24|12@1+ (0.0625,-125) [-125|125.9375] "%" Vector__XXX
SG_ MtrGen3InvertLmtsActDCSdeCurrMax : 36|12@1+ (0.0625,-125) [-125|125.9375] "%" Vector__XXX
SG_ MtrGen3InvertLmtsActDCSdeCurrMin : 48|12@1+ (0.0625,-125) [-125|125.9375] "%" Vector__XXX

BO_ 2565992190 MG3ILV: 8 Vector__XXX
SG_ MtrGen3InvertSwedIgnitionVoltage : 0|16@1+ (0.05,0) [0|3212.75] "V" Vector__XXX
SG_ MtrGen3InvertUnswitchedSLIVltg : 16|16@1+ (0.05,0) [0|3212.75] "V" Vector__XXX

BO_ 2565992446 MG3IS2: 8 Vector__XXX
SG_ MotorGen3InverterStatus2CRC : 0|8@1+ (1,0) [0|255] "" Vector__XXX
SG_ MotorGen3InverterStatus2Cntr : 8|4@1+ (1,0) [0|15] "" Vector__XXX
SG_ MotorGen3AvailMaximumTorque : 12|12@1+ (0.0625,-125) [-125|125.9375] "%" Vector__XXX
SG_ MotorGen3AvailMinimumTorque : 24|12@1+ (0.0625,-125) [-125|125.9375] "%" Vector__XXX

BO_ 2565992702 MG3IRLA1: 8 Vector__XXX
SG_ MotorGen3InvertRateLmtsActv1CRC : 0|8@1+ (1,0) [0|255] "" Vector__XXX
SG_ MotorGen3InvertRateLmtsActv1Cntr : 8|4@1+ (1,0) [0|15] "" Vector__XXX
SG_ MtrGen3InvRatLmtsActAbsSpdRatLmt : 12|12@1+ (0.25,0) [0|1003.75] "%/s" Vector__XXX
SG_ MtrGen3InvRatLmtsActAbsTrqRatLmt : 24|12@1+ (2,0) [0|8030] "%/s" Vector__XXX

BO_ 2364666366 MG4IMF1: 8 Vector__XXX
SG_ MotorGen4InverterModeFdbck1CRC : 0|8@1+ (1,0) [0|255] "" Vector__XXX
SG_ MotorGen4InverterModeFdbck1Cntr : 8|4@1+ (1,0) [0|15] "" Vector__XXX
SG_ MtrGen4InvertCtrlLmtsOverrideMde : 12|4@1+ (1,0) [0|15] "" Vector__XXX
SG_ MotorGen4InvertCtrlSetpointMode : 16|5@1+ (1,0) [0|31] "" Vector__XXX
SG_ MotorGen4InverterHVILStatus : 21|2@1+ (1,0) [0|3] "" Vector__XXX

BO_ 2565993214 MG4ILAP: 8 Vector__XXX
SG_ MotorGen4InvertLmtsActvPowerCRC : 0|8@1+ (1,0) [0|255] "" Vector__XXX
SG_ MotorGen4InvertLmtsActvPowerCntr : 8|4@1+ (1,0) [0|15] "" Vector__XXX
SG_ MtrGen4InvLmtsActMechnclPwrMax : 12|12@1+ (0.0625,-125) [-125|125.9375] "%" Vector__XXX
SG_ MtrGen4InvLmtsActMechnclPwrMin : 24|12@1+ (0.0625,-125) [-125|125.9375] "%" Vector__XXX
SG_ MtrGen4InvertLmtsActvDCSdePwrMax : 36|12@1+ (0.0625,-125) [-125|125.9375] "%" Vector__XXX
SG_ MtrGen4InvertLmtsActvDCSdePwrMin : 48|12@1+ (0.0625,-125) [-125|125.9375] "%" Vector__XXX

BO_ 2565993470 MG4ILAM: 8 Vector__XXX
SG_ MtrGen4InvertLmtsActvMechnclCRC : 0|8@1+ (1,0) [0|255] "" Vector__XXX
SG_ MtrGen4InvertLmtsActvMechnclCntr : 8|4@1+ (1,0) [0|15] "" Vector__XXX
SG_ MotorGen4InvertLmtsActvTorqueMax : 12|12@1+ (0.0625,-125) [-125|125.9375] "%" Vector__XXX
SG_ MotorGen4InvertLmtsActvTorqueMin : 24|12@1+ (0.0625,-125) [-125|125.9375] "%" Vector__XXX
SG_ MotorGen4InvertLmtsActvSpeedMax : 36|12@1+ (0.0625,-125) [-125|125.9375] "%" Vector__XXX
SG_ MotorGen4InvertLmtsActvSpeedMin : 48|12@1+ (0.0625,-125) [-125|125.9375] "%" Vector__XXX

BO_ 2565993726 MG4ILADC: 8 Vector__XXX
SG_ MotorGen4InvertLmtsActvDCSideCRC : 0|8@1+ (1,0) [0|255] "" Vector__XXX
SG_ MtrGen4InvertLmtsActvDCSideCntr : 8|4@1+ (1,0) [0|15] "" Vector__XXX
SG_ MtrGen4InvertLmtsActDCSdeVltgMax : 12|12@1+ (0.0625,-125) [-125|125.9375] "%" Vector__XXX
SG_ MtrGen4InvertLmtsActDCSdeVltgMin : 24|12@1+ (0.0625,-125) [-125|125.9375] "%" Vector__XXX
SG_ MtrGen4InvertLmtsActDCSdeCurrMax : 36|12@1+ (0.0625,-125) [-125|125.9375] "%" Vector__XXX
SG_ MtrGen4InvertLmtsActDCSdeCurrMin : 48|12@1+ (0.0625,-125) [-125|125.9375] "%" Vector__XXX

BO_ 2565993982 MG4ILV: 8 Vector__XXX
SG_ MtrGen4InvertSwedIgnitionVoltage : 0|16@1+ (0.05,0) [0|3212.75] "V" Vector__XXX
SG_ MtrGen4InvertUnswitchedSLIVltg : 16|16@1+ (0.05,0) [0|3212.75] "V" Vector__XXX

BO_ 2565994238 MG4IS2: 8 Vector__XXX
SG_ MotorGen4InverterStatus2CRC : 0|8@1+ (1,0) [0|255] "" Vector__XXX
SG_ MotorGen4InverterStatus2Cntr : 8|4@1+ (1,0) [0|15] "" Vector__XXX
SG_ MotorGen4AvailMaximumTorque : 12|12@1+ (0.0625,-125) [-125|125.9375] "%" Vector__XXX
SG_ MotorGen4AvailMinimumTorque : 24|12@1+ (0.0625,-125) [-125|125.9375] "%" Vector__XXX

BO_ 2565994494 MG4IRLA1: 8 Vector__XXX
SG_ MotorGen4InvertRateLmtsActv1CRC : 0|8@1+ (1,0) [0|255] "" Vector__XXX
SG_ MotorGen4InvertRateLmtsActv1Cntr : 8|4@1+ (1,0) [0|15] "" Vector__XXX
SG_ MtrGen4InvRatLmtsActAbsSpdRatLmt : 12|12@1+ (0.25,0) [0|1003.75] "%/s" Vector__XXX
SG_ MtrGen4InvRatLmtsActAbsTrqRatLmt : 24|12@1+ (2,0) [0|8030] "%/s" Vector__XXX

BO_ 2364668158 MG5IMF1: 8 Vector__XXX
SG_ MotorGen5InverterModeFdbck1CRC : 0|8@1+ (1,0) [0|255] "" Vector__XXX
SG_ MotorGen5InverterModeFdbck1Cntr : 8|4@1+ (1,0) [0|15] "" Vector__XXX
SG_ MtrGen5InvertCtrlLmtsOverrideMde : 12|4@1+ (1,0) [0|15] "" Vector__XXX
SG_ MotorGen5InvertCtrlSetpointMode : 16|5@1+ (1,0) [0|31] "" Vector__XXX
SG_ MotorGen5InverterHVILStatus : 21|2@1+ (1,0) [0|3] "" Vector__XXX

BO_ 2565995006 MG5ILAP: 8 Vector__XXX
SG_ MotorGen5InvertLmtsActvPowerCRC : 0|8@1+ (1,0) [0|255] "" Vector__XXX
SG_ MotorGen5InvertLmtsActvPowerCntr : 8|4@1+ (1,0) [0|15] "" Vector__XXX
SG_ MtrGen5InvLmtsActMechnclPwrMax : 12|12@1+ (0.0625,-125) [-125|125.9375] "%" Vector__XXX
SG_ MtrGen5InvLmtsActMechnclPwrMin : 24|12@1+ (0.0625,-125) [-125|125.9375] "%" Vector__XXX
SG_ MtrGen5InvertLmtsActvDCSdePwrMax : 36|12@1+ (0.0625,-125) [-125|125.9375] "%" Vector__XXX
SG_ MtrGen5InvertLmtsActvDCSdePwrMin : 48|12@1+ (0.0625,-125) [-125|125.9375] "%" Vector__XXX

BO_ 2565995262 MG5ILAM: 8 Vector__XXX
SG_ MtrGen5InvertLmtsActvMechnclCRC : 0|8@1+ (1,0) [0|255] "" Vector__XXX
SG_ MtrGen5InvertLmtsActvMechnclCntr : 8|4@1+ (1,0) [0|15] "" Vector__XXX
SG_ MotorGen5InvertLmtsActvTorqueMax : 12|12@1+ (0.0625,-125) [-125|125.9375] "%" Vector__XXX
SG_ MotorGen5InvertLmtsActvTorqueMin : 24|12@1+ (0.0625,-125) [-125|125.9375] "%" Vector__XXX
SG_ MotorGen5InvertLmtsActvSpeedMax : 36|12@1+ (0.0625,-125) [-125|125.9375] "%" Vector__XXX
SG_ MotorGen5InvertLmtsActvSpeedMin : 48|12@1+ (0.0625,-125) [-125|125.9375] "%" Vector__XXX

BO_ 2565995518 MG5ILADC: 8 Vector__XXX
SG_ MotorGen5InvertLmtsActvDCSideCRC : 0|8@1+ (1,0) [0|255] "" Vector__XXX
SG_ MtrGen5InvertLmtsActvDCSideCntr : 8|4@1+ (1,0) [0|15] "" Vector__XXX
SG_ MtrGen5InvertLmtsActDCSdeVltgMax : 12|12@1+ (0.0625,-125) [-125|125.9375] "%" Vector__XXX
SG_ MtrGen5InvertLmtsActDCSdeVltgMin : 24|12@1+ (0.0625,-125) [-125|125.9375] "%" Vector__XXX
SG_ MtrGen5InvertLmtsActDCSdeCurrMax : 36|12@1+ (0.0625,-125) [-125|125.9375] "%" Vector__XXX
SG_ MtrGen5InvertLmtsActDCSdeCurrMin : 48|12@1+ (0.0625,-125) [-125|125.9375] "%" Vector__XXX

BO_ 2565995774 MG5ILV: 8 Vector__XXX
SG_ MtrGen5InvertSwedIgnitionVoltage : 0|16@1+ (0.05,0) [0|3212.75] "V" Vector__XXX
SG_ MtrGen5InvertUnswitchedSLIVltg : 16|16@1+ (0.05,0) [0|3212.75] "V" Vector__XXX

BO_ 2565996030 MG5IS2: 8 Vector__XXX
SG_ MotorGen5InverterStatus2CRC : 0|8@1+ (1,0) [0|255] "" Vector__XXX
SG_ MotorGen5InverterStatus2Cntr : 8|4@1+ (1,0) [0|15] "" Vector__XXX
SG_ MotorGen5AvailMaximumTorque : 12|12@1+ (0.0625,-125) [-125|125.9375] "%" Vector__XXX
SG_ MotorGen5AvailMinimumTorque : 24|12@1+ (0.0625,-125) [-125|125.9375] "%" Vector__XXX

BO_ 2565996286 MG5IRLA1: 8 Vector__XXX
SG_ MotorGen5InvertRateLmtsActv1CRC : 0|8@1+ (1,0) [0|255] "" Vector__XXX
SG_ MotorGen5InvertRateLmtsActv1Cntr : 8|4@1+ (1,0) [0|15] "" Vector__XXX
SG_ MtrGen5InvRatLmtsActAbsSpdRatLmt : 12|12@1+ (0.25,0) [0|1003.75] "%/s" Vector__XXX
SG_ MtrGen5InvRatLmtsActAbsTrqRatLmt : 24|12@1+ (2,0) [0|8030] "%/s" Vector__XXX

BO_ 2364669950 MG6IMF1: 8 Vector__XXX
SG_ MotorGen6InverterModeFdbck1CRC : 0|8@1+ (1,0) [0|255] "" Vector__XXX
SG_ MotorGen6InverterModeFdbck1Cntr : 8|4@1+ (1,0) [0|15] "" Vector__XXX
SG_ MtrGen6InvertCtrlLmtsOverrideMde : 12|4@1+ (1,0) [0|15] "" Vector__XXX
SG_ MotorGen6InvertCtrlSetpointMode : 16|5@1+ (1,0) [0|31] "" Vector__XXX
SG_ MotorGen6InverterHVILStatus : 21|2@1+ (1,0) [0|3] "" Vector__XXX

BO_ 2565996798 MG6ILAP: 8 Vector__XXX
SG_ MotorGen6InvertLmtsActvPowerCRC : 0|8@1+ (1,0) [0|255] "" Vector__XXX
SG_ MotorGen6InvertLmtsActvPowerCntr : 8|4@1+ (1,0) [0|15] "" Vector__XXX
SG_ MtrGen6InvLmtsActMechnclPwrMax : 12|12@1+ (0.0625,-125) [-125|125.9375] "%" Vector__XXX
SG_ MtrGen6InvLmtsActMechnclPwrMin : 24|12@1+ (0.0625,-125) [-125|125.9375] "%" Vector__XXX
SG_ MtrGen6InvertLmtsActvDCSdePwrMax : 36|12@1+ (0.0625,-125) [-125|125.9375] "%" Vector__XXX
SG_ MtrGen6InvertLmtsActvDCSdePwrMin : 48|12@1+ (0.0625,-125) [-125|125.9375] "%" Vector__XXX

BO_ 2565997054 MG6ILAM: 8 Vector__XXX
SG_ MtrGen6InvertLmtsActvMechnclCRC : 0|8@1+ (1,0) [0|255] "" Vector__XXX
SG_ MtrGen6InvertLmtsActvMechnclCntr : 8|4@1+ (1,0) [0|15] "" Vector__XXX
SG_ MotorGen6InvertLmtsActvTorqueMax : 12|12@1+ (0.0625,-125) [-125|125.9375] "%" Vector__XXX
SG_ MotorGen6InvertLmtsActvTorqueMin : 24|12@1+ (0.0625,-125) [-125|125.9375] "%" Vector__XXX
SG_ MotorGen6InvertLmtsActvSpeedMax : 36|12@1+ (0.0625,-125) [-125|125.9375] "%" Vector__XXX
SG_ MotorGen6InvertLmtsActvSpeedMin : 48|12@1+ (0.0625,-125) [-125|125.9375] "%" Vector__XXX

BO_ 2565997310 MG6ILADC: 8 Vector__XXX
SG_ MotorGen6InvertLmtsActvDCSideCRC : 0|8@1+ (1,0) [0|255] "" Vector__XXX
SG_ MtrGen6InvertLmtsActvDCSideCntr : 8|4@1+ (1,0) [0|15] "" Vector__XXX
SG_ MtrGen6InvertLmtsActDCSdeVltgMax : 12|12@1+ (0.0625,-125) [-125|125.9375] "%" Vector__XXX
SG_ MtrGen6InvertLmtsActDCSdeVltgMin : 24|12@1+ (0.0625,-125) [-125|125.9375] "%" Vector__XXX
SG_ MtrGen6InvertLmtsActDCSdeCurrMax : 36|12@1+ (0.0625,-125) [-125|125.9375] "%" Vector__XXX
SG_ MtrGen6InvertLmtsActDCSdeCurrMin : 48|12@1+ (0.0625,-125) [-125|125.9375] "%" Vector__XXX

BO_ 2565997566 MG6ILV: 8 Vector__XXX
SG_ MtrGen6InvertSwedIgnitionVoltage : 0|16@1+ (0.05,0) [0|3212.75] "V" Vector__XXX
SG_ MtrGen6InvertUnswitchedSLIVltg : 16|16@1+ (0.05,0) [0|3212.75] "V" Vector__XXX

BO_ 2565997822 MG6IS2: 8 Vector__XXX
SG_ MotorGen6InverterStatus2CRC : 0|8@1+ (1,0) [0|255] "" Vector__XXX
SG_ MotorGen6InverterStatus2Cntr : 8|4@1+ (1,0) [0|15] "" Vector__XXX
SG_ MotorGen6AvailMaximumTorque : 12|12@1+ (0.0625,-125) [-125|125.9375] "%" Vector__XXX
SG_ MotorGen6AvailMinimumTorque : 24|12@1+ (0.0625,-125) [-125|125.9375] "%" Vector__XXX

BO_ 2565998078 MG6IRLA1: 8 Vector__XXX
SG_ MotorGen6InvertRateLmtsActv1CRC : 0|8@1+ (1,0) [0|255] "" Vector__XXX
SG_ MotorGen6InvertRateLmtsActv1Cntr : 8|4@1+ (1,0) [0|15] "" Vector__XXX
SG_ MtrGen6InvRatLmtsActAbsSpdRatLmt : 12|12@1+ (0.25,0) [0|1003.75] "%/s" Vector__XXX
SG_ MtrGen6InvRatLmtsActAbsTrqRatLmt : 24|12@1+ (2,0) [0|8030] "%/s" Vector__XXX

BO_ 2364671742 BSD1: 8 Vector__XXX
SG_ BlindSpotDetectionState : 0|4@1+ (1,0) [0|15] "" Vector__XXX
SG_ BlindSpotCollisionWarningLevel : 4|4@1+ (1,0) [0|15] "" Vector__XXX
SG_ BlindSpotWarningRelvntObjDetctd : 8|3@1+ (1,0) [0|7] "" Vector__XXX
SG_ BendOffProbabltyMstImportntObj : 11|3@1+ (1,0) [0|7] "" Vector__XXX
SG_ BlindSpotDetctnLeftSideMonitored : 16|2@1+ (1,0) [0|3] "" Vector__XXX
SG_ BlindSpotDetctnRightSideMontrd : 18|2@1+ (1,0) [0|3] "" Vector__XXX
SG_ BlindSpotDetectionFrontMonitored : 20|2@1+ (1,0) [0|3] "" Vector__XXX
SG_ BlindSpotDetectionRearMonitored : 22|2@1+ (1,0) [0|3] "" Vector__XXX

BO_ 2364671998 WINCH1: 8 Vector__XXX
SG_ WinchMotorEncoderPosition : 0|16@1+ (1,0) [0|64255] "" Vector__XXX
SG_ WinchRevolutionCounter : 16|16@1+ (1,-32128) [-32128|32127] "" Vector__XXX

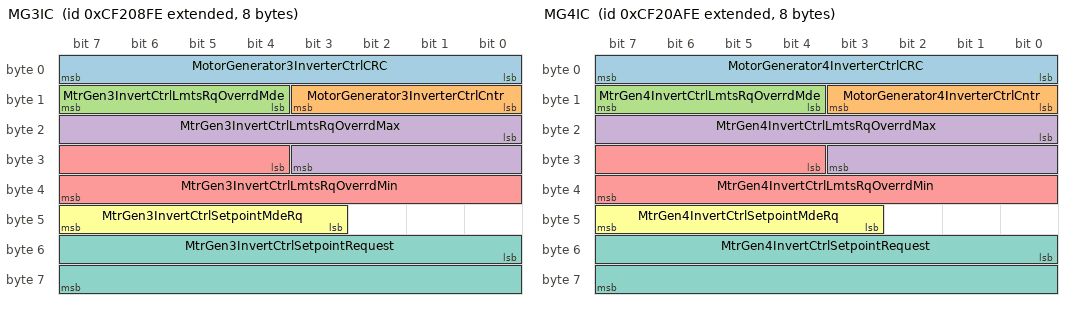
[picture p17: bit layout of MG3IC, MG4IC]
BO_ 2364672254 MG3IC: 8 Vector__XXX
SG_ MotorGenerator3InverterCtrlCRC : 0|8@1+ (1,0) [0|255] "" Vector__XXX
SG_ MotorGenerator3InverterCtrlCntr : 8|4@1+ (1,0) [0|15] "" Vector__XXX
SG_ MtrGen3InvertCtrlLmtsRqOverrdMde : 12|4@1+ (1,0) [0|15] "" Vector__XXX
SG_ MtrGen3InvertCtrlLmtsRqOverrdMax : 16|12@1+ (0.0625,-125) [-125|125.9375] "%" Vector__XXX
SG_ MtrGen3InvertCtrlLmtsRqOverrdMin : 28|12@1+ (0.0625,-125) [-125|125.9375] "%" Vector__XXX
SG_ MtrGen3InvertCtrlSetpointMdeRq : 43|5@1+ (1,0) [0|31] "" Vector__XXX
SG_ MtrGen3InvertCtrlSetpointRequest : 48|16@1+ (0.00390625,-125) [-125|125.99609375] "%" Vector__XXX

BO_ 2565999102 MG3IRLR1: 8 Vector__XXX
SG_ MtrGen3InvertRateLmtsRequest1CRC : 0|8@1+ (1,0) [0|255] "" Vector__XXX
SG_ MtrGen3InvertRatLmtsRequest1Cntr : 8|4@1+ (1,0) [0|15] "" Vector__XXX
SG_ MtrGen3InvRatLmtsRqAbsSpdRatLmt : 12|12@1+ (0.25,0) [0|1003.75] "%/s" Vector__XXX
SG_ MtrGen3InvRatLmtsRqAbsTrqRatLmt : 24|12@1+ (2,0) [0|8030] "%/s" Vector__XXX

BO_ 2364672766 MG4IC: 8 Vector__XXX
SG_ MotorGenerator4InverterCtrlCRC : 0|8@1+ (1,0) [0|255] "" Vector__XXX
SG_ MotorGenerator4InverterCtrlCntr : 8|4@1+ (1,0) [0|15] "" Vector__XXX
SG_ MtrGen4InvertCtrlLmtsRqOverrdMde : 12|4@1+ (1,0) [0|15] "" Vector__XXX
SG_ MtrGen4InvertCtrlLmtsRqOverrdMax : 16|12@1+ (0.0625,-125) [-125|125.9375] "%" Vector__XXX
SG_ MtrGen4InvertCtrlLmtsRqOverrdMin : 28|12@1+ (0.0625,-125) [-125|125.9375] "%" Vector__XXX
SG_ MtrGen4InvertCtrlSetpointMdeRq : 43|5@1+ (1,0) [0|31] "" Vector__XXX
SG_ MtrGen4InvertCtrlSetpointRequest : 48|16@1+ (0.00390625,-125) [-125|125.99609375] "%" Vector__XXX

BO_ 2565999614 MG4IRLR1: 8 Vector__XXX
SG_ MtrGen4InvertRateLmtsRequest1CRC : 0|8@1+ (1,0) [0|255] "" Vector__XXX
SG_ MtrGen4InvertRatLmtsRequest1Cntr : 8|4@1+ (1,0) [0|15] "" Vector__XXX
SG_ MtrGen4InvRatLmtsRqAbsSpdRatLmt : 12|12@1+ (0.25,0) [0|1003.75] "%/s" Vector__XXX
SG_ MtrGen4InvRatLmtsRqAbsTrqRatLmt : 24|12@1+ (2,0) [0|8030] "%/s" Vector__XXX

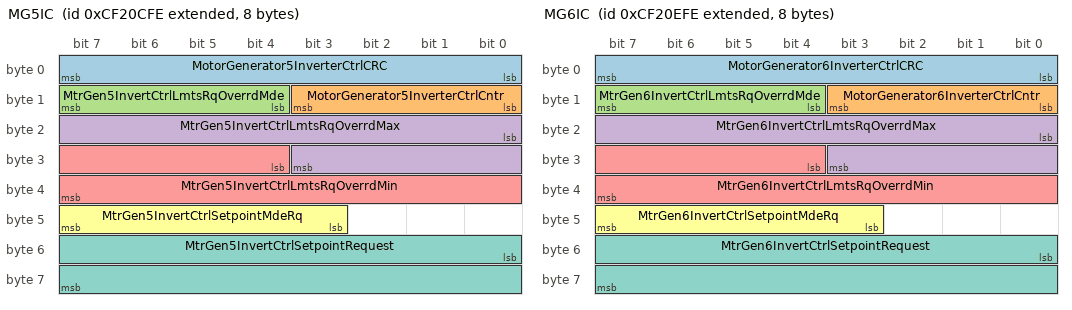
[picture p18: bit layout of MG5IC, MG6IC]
BO_ 2364673278 MG5IC: 8 Vector__XXX
SG_ MotorGenerator5InverterCtrlCRC : 0|8@1+ (1,0) [0|255] "" Vector__XXX
SG_ MotorGenerator5InverterCtrlCntr : 8|4@1+ (1,0) [0|15] "" Vector__XXX
SG_ MtrGen5InvertCtrlLmtsRqOverrdMde : 12|4@1+ (1,0) [0|15] "" Vector__XXX
SG_ MtrGen5InvertCtrlLmtsRqOverrdMax : 16|12@1+ (0.0625,-125) [-125|125.9375] "%" Vector__XXX
SG_ MtrGen5InvertCtrlLmtsRqOverrdMin : 28|12@1+ (0.0625,-125) [-125|125.9375] "%" Vector__XXX
SG_ MtrGen5InvertCtrlSetpointMdeRq : 43|5@1+ (1,0) [0|31] "" Vector__XXX
SG_ MtrGen5InvertCtrlSetpointRequest : 48|16@1+ (0.00390625,-125) [-125|125.99609375] "%" Vector__XXX

BO_ 2566000126 MG5IRLR1: 8 Vector__XXX
SG_ MtrGen5InvertRateLmtsRequest1CRC : 0|8@1+ (1,0) [0|255] "" Vector__XXX
SG_ MtrGen5InvertRatLmtsRequest1Cntr : 8|4@1+ (1,0) [0|15] "" Vector__XXX
SG_ MtrGen5InvRatLmtsRqAbsSpdRatLmt : 12|12@1+ (0.25,0) [0|1003.75] "%/s" Vector__XXX
SG_ MtrGen5InvRatLmtsRqAbsTrqRatLmt : 24|12@1+ (2,0) [0|8030] "%/s" Vector__XXX

BO_ 2364673790 MG6IC: 8 Vector__XXX
SG_ MotorGenerator6InverterCtrlCRC : 0|8@1+ (1,0) [0|255] "" Vector__XXX
SG_ MotorGenerator6InverterCtrlCntr : 8|4@1+ (1,0) [0|15] "" Vector__XXX
SG_ MtrGen6InvertCtrlLmtsRqOverrdMde : 12|4@1+ (1,0) [0|15] "" Vector__XXX
SG_ MtrGen6InvertCtrlLmtsRqOverrdMax : 16|12@1+ (0.0625,-125) [-125|125.9375] "%" Vector__XXX
SG_ MtrGen6InvertCtrlLmtsRqOverrdMin : 28|12@1+ (0.0625,-125) [-125|125.9375] "%" Vector__XXX
SG_ MtrGen6InvertCtrlSetpointMdeRq : 43|5@1+ (1,0) [0|31] "" Vector__XXX
SG_ MtrGen6InvertCtrlSetpointRequest : 48|16@1+ (0.00390625,-125) [-125|125.99609375] "%" Vector__XXX

BO_ 2566000638 MG6IRLR1: 8 Vector__XXX
SG_ MtrGen6InvertRateLmtsRequest1CRC : 0|8@1+ (1,0) [0|255] "" Vector__XXX
SG_ MtrGen6InvertRatLmtsRequest1Cntr : 8|4@1+ (1,0) [0|15] "" Vector__XXX
SG_ MtrGen6InvRatLmtsRqAbsSpdRatLmt : 12|12@1+ (0.25,0) [0|1003.75] "%/s" Vector__XXX
SG_ MtrGen6InvRatLmtsRqAbsTrqRatLmt : 24|12@1+ (2,0) [0|8030] "%/s" Vector__XXX

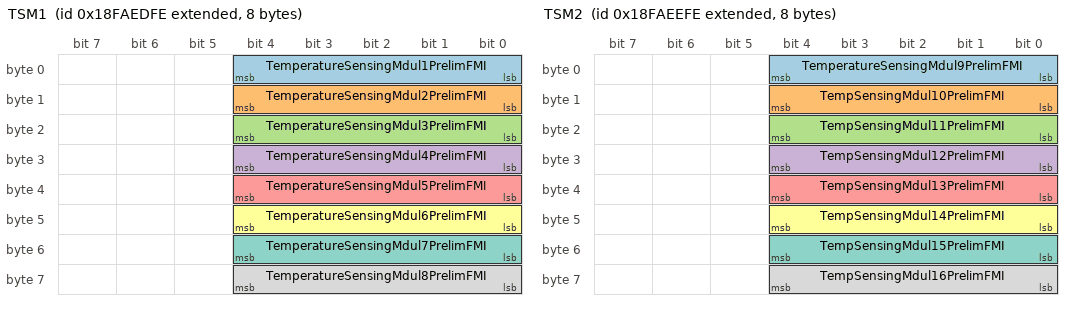
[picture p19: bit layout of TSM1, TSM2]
BO_ 2566581758 TSM1: 8 Vector__XXX
SG_ TemperatureSensingMdul1PrelimFMI : 0|5@1+ (1,0) [0|31] "" Vector__XXX
SG_ TemperatureSensingMdul2PrelimFMI : 8|5@1+ (1,0) [0|31] "" Vector__XXX
SG_ TemperatureSensingMdul3PrelimFMI : 16|5@1+ (1,0) [0|31] "" Vector__XXX
SG_ TemperatureSensingMdul4PrelimFMI : 24|5@1+ (1,0) [0|31] "" Vector__XXX
SG_ TemperatureSensingMdul5PrelimFMI : 32|5@1+ (1,0) [0|31] "" Vector__XXX
SG_ TemperatureSensingMdul6PrelimFMI : 40|5@1+ (1,0) [0|31] "" Vector__XXX
SG_ TemperatureSensingMdul7PrelimFMI : 48|5@1+ (1,0) [0|31] "" Vector__XXX
SG_ TemperatureSensingMdul8PrelimFMI : 56|5@1+ (1,0) [0|31] "" Vector__XXX

BO_ 2566582014 TSM2: 8 Vector__XXX
SG_ TemperatureSensingMdul9PrelimFMI : 0|5@1+ (1,0) [0|31] "" Vector__XXX
SG_ TempSensingMdul10PrelimFMI : 8|5@1+ (1,0) [0|31] "" Vector__XXX
SG_ TempSensingMdul11PrelimFMI : 16|5@1+ (1,0) [0|31] "" Vector__XXX
SG_ TempSensingMdul12PrelimFMI : 24|5@1+ (1,0) [0|31] "" Vector__XXX
SG_ TempSensingMdul13PrelimFMI : 32|5@1+ (1,0) [0|31] "" Vector__XXX
SG_ TempSensingMdul14PrelimFMI : 40|5@1+ (1,0) [0|31] "" Vector__XXX
SG_ TempSensingMdul15PrelimFMI : 48|5@1+ (1,0) [0|31] "" Vector__XXX
SG_ TempSensingMdul16PrelimFMI : 56|5@1+ (1,0) [0|31] "" Vector__XXX

BO_ 2566582270 A2SCRSI3: 8 Vector__XXX
SG_ Afttreatment2SCRNrmlzdCnvrsnEff : 0|8@1+ (0.04,0) [0|10.2] "%" Vector__XXX

BO_ 2566582526 A1SCRSI3: 8 Vector__XXX
SG_ Afttreatment1SCRNrmlzdCnvrsnEff : 0|8@1+ (0.04,0) [0|10.2] "%" Vector__XXX

BO_ 2566582782 PSATL: 12 Vector__XXX
SG_ HybrdLifetmeProplsnSysActvTime : 0|32@1+ (1,0) [0|4211081215] "s" Vector__XXX
SG_ HybrdLifetmeIdlProplsnSysActvTme : 32|32@1+ (1,0) [0|4211081215] "s" Vector__XXX
SG_ HybLifetmeUrbanProplsnSysActTme : 64|32@1+ (1,0) [0|4211081215] "s" Vector__XXX

BO_ 2566583038 PSATS: 8 Vector__XXX
SG_ HybStord100HrRecProplsnSysActTme : 0|16@1+ (10,0) [0|642550] "s" Vector__XXX
SG_ HybStord100HrIdlProplsnSysActTme : 16|16@1+ (10,0) [0|642550] "s" Vector__XXX
SG_ HybStrd100HrUrbanPrplsnSysActTme : 32|16@1+ (10,0) [0|642550] "s" Vector__XXX

BO_ 2566583294 PSATA: 8 Vector__XXX
SG_ HybrdActv100HrProplsnSysActvTime : 0|16@1+ (10,0) [0|642550] "s" Vector__XXX
SG_ HybrdAct100HrIdlProplsnSysActTme : 16|16@1+ (10,0) [0|642550] "s" Vector__XXX
SG_ HybAct100HrUrbanProplsnSysActTme : 32|16@1+ (10,0) [0|642550] "s" Vector__XXX

BO_ 2566583550 HCDIOL: 32 Vector__XXX
SG_ HybLftmDistTrvledChrgDepOpEngOff : 0|32@1+ (5,0) [0|21055406075] "m" Vector__XXX
SG_ HybLftmDistTrvledChrgDepOpEngRun : 32|32@1+ (5,0) [0|21055406075] "m" Vector__XXX
SG_ HybLftDstTrvDrvSlctableChrgIncOp : 64|32@1+ (5,0) [0|21055406075] "m" Vector__XXX
SG_ HybLifetmeFuelConsumedChrgDepOp : 96|32@1+ (0.5,0) [0|2105540607.5] "l" Vector__XXX
SG_ HybLftFlConsDrvSlctableChrgIncOp : 128|32@1+ (0.5,0) [0|2105540607.5] "l" Vector__XXX
SG_ HybLftmGrEngyConsChrgDepOpEngOff : 160|32@1+ (1,0) [0|4211081215] "kWh" Vector__XXX
SG_ HybLftmGrEngyConsChrgDepOpEngRun : 192|32@1+ (1,0) [0|4211081215] "kWh" Vector__XXX
SG_ HybridLifetimeGrdEnrgyIntoBattry : 224|32@1+ (1,0) [0|4211081215] "kWh" Vector__XXX

BO_ 2566583806 HCDIOS: 16 Vector__XXX
SG_ HybStrd100HrDstTrvChrgDepOpEgOff : 0|16@1+ (0.25,0) [0|16063.75] "km" Vector__XXX
SG_ HybStrd100HrDstTrvChrgDepOpEgRun : 16|16@1+ (0.25,0) [0|16063.75] "km" Vector__XXX
SG_ HybStrd100HrDstTrvDrvSelChgIncOp : 32|16@1+ (0.25,0) [0|16063.75] "km" Vector__XXX
SG_ HybrdStord100HrFlConsmdChgDepOp : 48|16@1+ (0.5,0) [0|32127.5] "l" Vector__XXX
SG_ HybStrd100HrFlConsDrvSelChgIncOp : 64|16@1+ (0.5,0) [0|32127.5] "l" Vector__XXX
SG_ HybStrd100HrGrEgyCnChgDepOpEgOff : 80|16@1+ (1,0) [0|64255] "kWh" Vector__XXX
SG_ HybStrd100HrGrEgyCnChgDepOpEgRun : 96|16@1+ (1,0) [0|64255] "kWh" Vector__XXX
SG_ HybrdStord100HrGrdEnrgyIntoBatt : 112|16@1+ (1,0) [0|64255] "kWh" Vector__XXX

BO_ 2566584062 HCDIOA: 16 Vector__XXX
SG_ HybAct100HrDstTrvChgDepOpEgOff : 0|16@1+ (0.25,0) [0|16063.75] "km" Vector__XXX
SG_ HybAct100HrDstTrvChgDepOpEgRun : 16|16@1+ (0.25,0) [0|16063.75] "km" Vector__XXX
SG_ HybAct100HrDstTrvDrvSelChgIncOp : 32|16@1+ (0.25,0) [0|16063.75] "km" Vector__XXX
SG_ HybrdAct100HrFlConsmdChgDepOp : 48|16@1+ (0.5,0) [0|32127.5] "l" Vector__XXX
SG_ HybAct100HrFlConsDrvSelChgIncOp : 64|16@1+ (0.5,0) [0|32127.5] "l" Vector__XXX
SG_ HybAct100HrGrEgyCnsChgDepOpEgOff : 80|16@1+ (1,0) [0|64255] "kWh" Vector__XXX
SG_ HybAct100HrGrEgyCnsChgDepOpEgRun : 96|16@1+ (1,0) [0|64255] "kWh" Vector__XXX
SG_ HybrdActv100HrGrdEnrgyIntoBattry : 112|16@1+ (1,0) [0|64255] "kWh" Vector__XXX

BO_ 2566584318 AT1HI3: 32 Vector__XXX
SG_ Aft1DPFRegenCmplStrtngEgVhclDst1 : 0|32@1+ (5,0) [0|21055406075] "m" Vector__XXX
SG_ Aft1DPFRegenCmplEndingEgVhclDst1 : 32|32@1+ (5,0) [0|21055406075] "m" Vector__XXX
SG_ Aft1DPFRegenCmplStrtngEgVhclDst2 : 64|32@1+ (5,0) [0|21055406075] "m" Vector__XXX
SG_ Aft1DPFRegenCmplEndingEgVhclDst2 : 96|32@1+ (0.125,0) [0|526385151.875] "km" Vector__XXX
SG_ Aft1DPFRegenCmplStrtngEgVhclDst3 : 128|32@1+ (5,0) [0|21055406075] "m" Vector__XXX
SG_ Aft1DPFRegenCmplEndingEgVhclDst3 : 160|32@1+ (5,0) [0|21055406075] "m" Vector__XXX
SG_ Aft1TtlEngRuntimeNoDEFDelivery : 192|32@1+ (1,0) [0|4211081215] "s" Vector__XXX
SG_ Aft1TtlTmeSCRInletBlw200Celsius : 224|32@1+ (1,0) [0|4211081215] "s" Vector__XXX

BO_ 2566584830 ATNXMS2: 8 Vector__XXX
SG_ Aftrtrtmnt1SCR2InletNOxMassFlow : 0|16@1+ (0.0001,0) [0|6.4255] "g/s" Vector__XXX
SG_ Aftrtrtmnt1SCR2OutletNOxMassFlow : 16|16@1+ (0.0001,0) [0|6.4255] "g/s" Vector__XXX
SG_ Aft1SCR2MdeledNH3StorageLvl : 32|16@1+ (1,0) [0|64255] "mg/l" Vector__XXX
SG_ Aft1SCR2TargetNH3StorageLvl : 48|16@1+ (1,0) [0|64255] "mg/l" Vector__XXX

BO_ 2566585086 ATNXMS1: 8 Vector__XXX
SG_ Aft1SCR1EngExhstNOxMassFlw : 0|16@1+ (0.0001,0) [0|6.4255] "g/s" Vector__XXX
SG_ Aft1SCR1TailpipeNOxMassFlw : 16|16@1+ (0.0001,0) [0|6.4255] "g/s" Vector__XXX
SG_ Aft1SCR1MdeledActlStorageLvl : 32|16@1+ (1,0) [0|64255] "mg/l" Vector__XXX
SG_ Aft1SCR1TargetNH3StorageLvl : 48|16@1+ (1,0) [0|64255] "mg/l" Vector__XXX

BO_ 2566585342 EVAPAC: 8 Vector__XXX
SG_ EVAPSystemPurgePressure : 0|16@1+ (4,0) [0|257] "Pa" Vector__XXX
SG_ EVAPSystemVaporPressure : 16|16@1+ (4,0) [0|257] "Pa" Vector__XXX
SG_ EVAPSystemPurgeValveCommand : 32|8@1+ (0.4,0) [0|100] "%" Vector__XXX
SG_ EVAPSystemPurgeValvePosition : 40|8@1+ (0.4,0) [0|100] "%" Vector__XXX

BO_ 2566585598 GHGTL: 52 Vector__XXX
SG_ GHGTrackingLifetimeEngineRunTime : 0|32@1+ (1,0) [0|4211081215] "s" Vector__XXX
SG_ GHGTrackingLifetimeVehicleDist : 32|32@1+ (5,0) [0|21055406075] "m" Vector__XXX
SG_ GHGTrackngLifetmeVhclFlCnsmptn : 64|32@1+ (0.05,0) [0|210554060.75] "l" Vector__XXX
SG_ GHGTrackingLifetimeEngFlCnsmptn : 96|32@1+ (0.05,0) [0|210554060.75] "l" Vector__XXX
SG_ GHGTrackingLifetmeEngOutputEnrgy : 128|32@1+ (1,0) [0|4211081215] "kWh" Vector__XXX
SG_ GHGTrackngLifetmPstvKineticEgyNo : 160|32@1+ (5,0) [0|21055406075] "km²/h²" Vector__XXX
SG_ GHGTrackingLifetmeUrbanSpdRunTme : 192|32@1+ (1,0) [0|4211081215] "s" Vector__XXX
SG_ GHGTrackingLifetimeIdleRunTime : 224|32@1+ (1,0) [0|4211081215] "s" Vector__XXX
SG_ GHGTrackngLifetmeEngIdlFlCnsmptn : 256|32@1+ (0.05,0) [0|210554060.75] "l" Vector__XXX
SG_ GHGTrackLifetmEgPwrTakeOffRunTme : 288|32@1+ (1,0) [0|4211081215] "s" Vector__XXX
SG_ GHGTrckLftmEgPwrTakeOffFlCnsmptn : 320|32@1+ (0.05,0) [0|210554060.75] "l" Vector__XXX
SG_ GHGTrckLftAutEgShtdwnTecgyActCnt : 352|16@1+ (1,0) [0|64255] "" Vector__XXX
SG_ GHGTrackLftmStopStrtTechgyRunTme : 384|32@1+ (1,0) [0|4211081215] "s" Vector__XXX

BO_ 2566585854 GHGTS: 28 Vector__XXX
SG_ GHGTrackingStored100HrEngRunTime : 0|16@1+ (10,0) [0|642550] "s" Vector__XXX
SG_ GHGTrackingStord100HrVehicleDist : 16|16@1+ (0.25,0) [0|16063.75] "km" Vector__XXX
SG_ GHGTrackngStrd100HrVhclFlCnsmptn : 32|16@1+ (0.5,0) [0|32127.5] "l" Vector__XXX
SG_ GHGTrackngStord100HrEngFlCnsmptn : 48|16@1+ (0.5,0) [0|32127.5] "l" Vector__XXX
SG_ GHGTrackngStord100HrEngOutptEngy : 64|16@1+ (1,0) [0|64255] "kWh" Vector__XXX
SG_ GHGTrckStrd100HrPstvKineticEgyNo : 80|32@1+ (1,0) [0|4211081215] "km²/h²" Vector__XXX
SG_ GHGTrackStrd100HrUrbanSpdRunTme : 112|16@1+ (10,0) [0|642550] "s" Vector__XXX
SG_ GHGTrackingStored100HrIdlRunTime : 128|16@1+ (10,0) [0|642550] "s" Vector__XXX
SG_ GHGTrackStrd100HrEgIdlFlCnsmptn : 144|16@1+ (0.5,0) [0|32127.5] "l" Vector__XXX
SG_ GHGTrackStrd100HrEgPwrTkOffRnTm : 160|16@1+ (10,0) [0|642550] "s" Vector__XXX
SG_ GHGTrackStrd100HrEgPwrTkOffFlCns : 176|16@1+ (0.5,0) [0|32127.5] "l" Vector__XXX
SG_ GHGTrckStrd100HrAutEgSdTechActCn : 192|16@1+ (1,0) [0|64255] "" Vector__XXX
SG_ GHGTrckStrd100HrStopStrTecgyRnTm : 208|16@1+ (10,0) [0|642550] "s" Vector__XXX

BO_ 2566586110 GHGTA: 28 Vector__XXX
SG_ GHGTrackingActv100HourEngRunTime : 0|16@1+ (10,0) [0|642550] "s" Vector__XXX
SG_ GHGTrackingActv100HrVehicleDist : 16|16@1+ (0.25,0) [0|16063.75] "km" Vector__XXX
SG_ GHGTrackngActv100HrVhclFlCnsmptn : 32|16@1+ (0.5,0) [0|32127.5] "l" Vector__XXX
SG_ GHGTrackingActv100HrEngFlCnsmptn : 48|16@1+ (0.5,0) [0|32127.5] "l" Vector__XXX
SG_ GHGTrackngActv100HrEngOutptEnrgy : 64|16@1+ (1,0) [0|64255] "kWh" Vector__XXX
SG_ GHGTrackAct100HrPstvKineticEgyNo : 80|32@1+ (1,0) [0|4211081215] "km²/h²" Vector__XXX
SG_ GHGTrackngActv100HrUrbanSpdRnTme : 112|16@1+ (10,0) [0|642550] "s" Vector__XXX
SG_ GHGTrackingActv100HrIdleRunTime : 128|16@1+ (10,0) [0|642550] "s" Vector__XXX
SG_ GHGTrackngAct100HrEngIdlFlCns : 144|16@1+ (0.5,0) [0|32127.5] "l" Vector__XXX
SG_ GHGTrackngAct100HrEgPwrTkOffRnTm : 160|16@1+ (10,0) [0|642550] "s" Vector__XXX
SG_ GHGTrackAct100HrEgPwrTkOffFlCns : 176|16@1+ (0.5,0) [0|32127.5] "l" Vector__XXX
SG_ GHGTrckAct100HrAutEgSdTecgyActCn : 192|16@1+ (1,0) [0|64255] "" Vector__XXX
SG_ GHGTrackAct100HrStopStrTecgyRnTm : 208|16@1+ (10,0) [0|642550] "s" Vector__XXX

BO_ 2566586366 GHGTTS: 8 Vector__XXX
SG_ GHGTrackStrd100HrActTechgyIndex : 0|8@1+ (1,0) [0|255] "" Vector__XXX
SG_ GHGTrackngStrd100HrActTechgyTme : 0|16@1+ (10,0) [0|642550] "s" Vector__XXX
SG_ GHGTrackStrd100HrActTecgyVhclDst : 0|16@1+ (0.25,0) [0|16063.75] "km" Vector__XXX

BO_ 2566586622 GHGTTA: 8 Vector__XXX
SG_ GHGTrackngAct100HrActTechgyIndex : 0|8@1+ (1,0) [0|255] "" Vector__XXX
SG_ GHGTrackngAct100HrActTechnlgyTme : 0|16@1+ (10,0) [0|642550] "s" Vector__XXX
SG_ GHGTrackAct100HrActTechgyVhclDst : 0|16@1+ (0.25,0) [0|16063.75] "km" Vector__XXX

BO_ 2566586878 GHGTTL: 8 Vector__XXX
SG_ GHGTrackngLifetmActTechnlgyIndex : 0|8@1+ (1,0) [0|255] "" Vector__XXX
SG_ GHGTrackngLifetmeActvTechnlgyTme : 0|32@1+ (1,0) [0|4211081215] "s" Vector__XXX
SG_ GHGTrackngLifetmActTechgyVhclDst : 0|32@1+ (5,0) [0|21055406075] "m" Vector__XXX

BO_ 2566587134 NTFCEA: 68 Vector__XXX
SG_ NOxTrackEgActivityLifetmFlCnBin1 : 0|32@1+ (0.05,0) [0|210554060.75] "l" Vector__XXX
SG_ NOxTrackEgActivityLifetmFlCnBin2 : 32|32@1+ (0.05,0) [0|210554060.75] "l" Vector__XXX
SG_ NOxTrackEgActivityLifetmFlCnBin3 : 64|32@1+ (0.05,0) [0|210554060.75] "l" Vector__XXX
SG_ NOxTrackEgActivityLifetmFlCnBin4 : 96|32@1+ (0.05,0) [0|210554060.75] "l" Vector__XXX
SG_ NOxTrackEgActivityLifetmFlCnBin5 : 128|32@1+ (0.05,0) [0|210554060.75] "l" Vector__XXX
SG_ NOxTrackEgActivityLifetmFlCnBin6 : 160|32@1+ (0.05,0) [0|210554060.75] "l" Vector__XXX
SG_ NOxTrackEgActivityLifetmFlCnBin7 : 192|32@1+ (0.05,0) [0|210554060.75] "l" Vector__XXX
SG_ NOxTrackEgActivityLifetmFlCnBin8 : 224|32@1+ (0.05,0) [0|210554060.75] "l" Vector__XXX
SG_ NOxTrackEgActivityLifetmFlCnBin9 : 256|32@1+ (0.05,0) [0|210554060.75] "l" Vector__XXX
SG_ NOxTrackEgActivityLftmFlCnBin10 : 288|32@1+ (0.05,0) [0|210554060.75] "l" Vector__XXX
SG_ NOxTrackEgActivityLftmFlCnBin11 : 320|32@1+ (0.05,0) [0|210554060.75] "l" Vector__XXX
SG_ NOxTrackEgActivityLftmFlCnBin12 : 352|32@1+ (0.05,0) [0|210554060.75] "l" Vector__XXX
SG_ NOxTrackEgActivityLftmFlCnBin13 : 384|32@1+ (0.05,0) [0|210554060.75] "l" Vector__XXX
SG_ NOxTrackEgActivityLftmFlCnBin14 : 416|32@1+ (0.05,0) [0|210554060.75] "l" Vector__XXX
SG_ NOxTrackEgActivityLftmFlCnBin15 : 448|32@1+ (0.05,0) [0|210554060.75] "l" Vector__XXX
SG_ NOxTrackEgActivityLftmFlCnBin16 : 480|32@1+ (0.05,0) [0|210554060.75] "l" Vector__XXX
SG_ NOxTrackEgActivityLftmFlCnBin17 : 512|32@1+ (0.05,0) [0|210554060.75] "l" Vector__XXX

BO_ 2566587390 NTEHEA: 68 Vector__XXX
SG_ NOxTrackEgActivityLftmEgRnTmBin1 : 0|32@1+ (1,0) [0|4211081215] "s" Vector__XXX
SG_ NOxTrackEgActivityLftmEgRnTmBin2 : 32|32@1+ (1,0) [0|4211081215] "s" Vector__XXX
SG_ NOxTrackEgActivityLftmEgRnTmBin3 : 64|32@1+ (1,0) [0|4211081215] "s" Vector__XXX
SG_ NOxTrackEgActivityLftmEgRnTmBin4 : 96|32@1+ (1,0) [0|4211081215] "s" Vector__XXX
SG_ NOxTrackEgActivityLftmEgRnTmBin5 : 128|32@1+ (1,0) [0|4211081215] "s" Vector__XXX
SG_ NOxTrackEgActivityLftmEgRnTmBin6 : 160|32@1+ (1,0) [0|4211081215] "s" Vector__XXX
SG_ NOxTrackEgActivityLftmEgRnTmBin7 : 192|32@1+ (1,0) [0|4211081215] "s" Vector__XXX
SG_ NOxTrackEgActivityLftmEgRnTmBin8 : 224|32@1+ (1,0) [0|4211081215] "s" Vector__XXX
SG_ NOxTrackEgActivityLftmEgRnTmBin9 : 256|32@1+ (1,0) [0|4211081215] "s" Vector__XXX
SG_ NOxTrckEgActivityLftmEgRnTmBin10 : 288|32@1+ (1,0) [0|4211081215] "s" Vector__XXX
SG_ NOxTrckEgActivityLftmEgRnTmBin11 : 320|32@1+ (1,0) [0|4211081215] "s" Vector__XXX
SG_ NOxTrckEgActivityLftmEgRnTmBin12 : 352|32@1+ (1,0) [0|4211081215] "s" Vector__XXX
SG_ NOxTrckEgActivityLftmEgRnTmBin13 : 384|32@1+ (1,0) [0|4211081215] "s" Vector__XXX
SG_ NOxTrckEgActivityLftmEgRnTmBin14 : 416|32@1+ (1,0) [0|4211081215] "s" Vector__XXX
SG_ NOxTrckEgActivityLftmEgRnTmBin15 : 448|32@1+ (1,0) [0|4211081215] "s" Vector__XXX
SG_ NOxTrckEgActivityLftmEgRnTmBin16 : 480|32@1+ (1,0) [0|4211081215] "s" Vector__XXX
SG_ NOxTrckEgActivityLftmEgRnTmBin17 : 512|32@1+ (1,0) [0|4211081215] "s" Vector__XXX

BO_ 2566587646 NTVMEA: 68 Vector__XXX
SG_ NOxTrckEgActivityLftmVhclDstBin1 : 0|32@1+ (5,0) [0|21055406075] "m" Vector__XXX
SG_ NOxTrckEgActivityLftmVhclDstBin2 : 32|32@1+ (5,0) [0|21055406075] "m" Vector__XXX
SG_ NOxTrckEgActivityLftmVhclDstBin3 : 64|32@1+ (5,0) [0|21055406075] "m" Vector__XXX
SG_ NOxTrckEgActivityLftmVhclDstBin4 : 96|32@1+ (5,0) [0|21055406075] "m" Vector__XXX
SG_ NOxTrckEgActivityLftmVhclDstBin5 : 128|32@1+ (5,0) [0|21055406075] "m" Vector__XXX
SG_ NOxTrckEgActivityLftmVhclDstBin6 : 160|32@1+ (5,0) [0|21055406075] "m" Vector__XXX
SG_ NOxTrckEgActivityLftmVhclDstBin7 : 192|32@1+ (5,0) [0|21055406075] "m" Vector__XXX
SG_ NOxTrckEgActivityLftmVhclDstBin8 : 224|32@1+ (5,0) [0|21055406075] "m" Vector__XXX
SG_ NOxTrckEgActivityLftmVhclDstBin9 : 256|32@1+ (5,0) [0|21055406075] "m" Vector__XXX
SG_ NOxTrckEgActivityLftVhclDstBin10 : 288|32@1+ (5,0) [0|21055406075] "m" Vector__XXX
SG_ NOxTrckEgActivityLftVhclDstBin11 : 320|32@1+ (5,0) [0|21055406075] "m" Vector__XXX
SG_ NOxTrckEgActivityLftVhclDstBin12 : 352|32@1+ (5,0) [0|21055406075] "m" Vector__XXX
SG_ NOxTrckEgActivityLftVhclDstBin13 : 384|32@1+ (5,0) [0|21055406075] "m" Vector__XXX
SG_ NOxTrckEgActivityLftVhclDstBin14 : 416|32@1+ (5,0) [0|21055406075] "m" Vector__XXX
SG_ NOxTrckEgActivityLftVhclDstBin15 : 448|32@1+ (5,0) [0|21055406075] "m" Vector__XXX
SG_ NOxTrckEgActivityLftVhclDstBin16 : 480|32@1+ (5,0) [0|21055406075] "m" Vector__XXX
SG_ NOxTrckEgActivityLftVhclDstBin17 : 512|32@1+ (5,0) [0|21055406075] "m" Vector__XXX

BO_ 2566587902 NTEEEA: 68 Vector__XXX
SG_ NOxTrckEgActivityLftEgOutEgyBin1 : 0|32@1+ (1,0) [0|4211081215] "kWh" Vector__XXX
SG_ NOxTrckEgActivityLftEgOutEgyBin2 : 32|32@1+ (1,0) [0|4211081215] "kWh" Vector__XXX
SG_ NOxTrckEgActivityLftEgOutEgyBin3 : 64|32@1+ (1,0) [0|4211081215] "kWh" Vector__XXX
SG_ NOxTrckEgActivityLftEgOutEgyBin4 : 96|32@1+ (1,0) [0|4211081215] "kWh" Vector__XXX
SG_ NOxTrckEgActivityLftEgOutEgyBin5 : 128|32@1+ (1,0) [0|4211081215] "kWh" Vector__XXX
SG_ NOxTrckEgActivityLftEgOutEgyBin6 : 160|32@1+ (1,0) [0|4211081215] "kWh" Vector__XXX
SG_ NOxTrckEgActivityLftEgOutEgyBin7 : 192|32@1+ (1,0) [0|4211081215] "kWh" Vector__XXX
SG_ NOxTrckEgActivityLftEgOutEgyBin8 : 224|32@1+ (1,0) [0|4211081215] "kWh" Vector__XXX
SG_ NOxTrckEgActivityLftEgOutEgyBin9 : 256|32@1+ (1,0) [0|4211081215] "kWh" Vector__XXX
SG_ NOxTrackEgActtyLftmEgOutEgyBin10 : 288|32@1+ (1,0) [0|4211081215] "kWh" Vector__XXX
SG_ NOxTrackEgActtyLftmEgOutEgyBin11 : 320|32@1+ (1,0) [0|4211081215] "kWh" Vector__XXX
SG_ NOxTrackEgActtyLftmEgOutEgyBin12 : 352|32@1+ (1,0) [0|4211081215] "kWh" Vector__XXX
SG_ NOxTrackEgActtyLftmEgOutEgyBin13 : 384|32@1+ (1,0) [0|4211081215] "kWh" Vector__XXX
SG_ NOxTrackEgActtyLftmEgOutEgyBin14 : 416|32@1+ (1,0) [0|4211081215] "kWh" Vector__XXX
SG_ NOxTrackEgActtyLftmEgOutEgyBin15 : 448|32@1+ (1,0) [0|4211081215] "kWh" Vector__XXX
SG_ NOxTrackEgActtyLftmEgOutEgyBin16 : 480|32@1+ (1,0) [0|4211081215] "kWh" Vector__XXX
SG_ NOxTrackEgActtyLftmEgOutEgyBin17 : 512|32@1+ (1,0) [0|4211081215] "kWh" Vector__XXX

BO_ 2566588158 NTFCV: 68 Vector__XXX
SG_ NOxTrackngValdNOxLifetmFlCnsBin1 : 0|32@1+ (0.05,0) [0|210554060.75] "l" Vector__XXX
SG_ NOxTrackngValdNOxLifetmFlCnsBin2 : 32|32@1+ (0.05,0) [0|210554060.75] "l" Vector__XXX
SG_ NOxTrackngValdNOxLifetmFlCnsBin3 : 64|32@1+ (0.05,0) [0|210554060.75] "l" Vector__XXX
SG_ NOxTrackngValdNOxLifetmFlCnsBin4 : 96|32@1+ (0.05,0) [0|210554060.75] "l" Vector__XXX
SG_ NOxTrackngValdNOxLifetmFlCnsBin5 : 128|32@1+ (0.05,0) [0|210554060.75] "l" Vector__XXX
SG_ NOxTrackngValdNOxLifetmFlCnsBin6 : 160|32@1+ (0.05,0) [0|210554060.75] "l" Vector__XXX
SG_ NOxTrackngValdNOxLifetmFlCnsBin7 : 192|32@1+ (0.05,0) [0|210554060.75] "l" Vector__XXX
SG_ NOxTrackngValdNOxLifetmFlCnsBin8 : 224|32@1+ (0.05,0) [0|210554060.75] "l" Vector__XXX
SG_ NOxTrackngValdNOxLifetmFlCnsBin9 : 256|32@1+ (0.05,0) [0|210554060.75] "l" Vector__XXX
SG_ NOxTrackValdNOxLifetmFlCnsBin10 : 288|32@1+ (0.05,0) [0|210554060.75] "l" Vector__XXX
SG_ NOxTrackValdNOxLifetmFlCnsBin11 : 320|32@1+ (0.05,0) [0|210554060.75] "l" Vector__XXX
SG_ NOxTrackValdNOxLifetmFlCnsBin12 : 352|32@1+ (0.05,0) [0|210554060.75] "l" Vector__XXX
SG_ NOxTrackValdNOxLifetmFlCnsBin13 : 384|32@1+ (0.05,0) [0|210554060.75] "l" Vector__XXX
SG_ NOxTrackValdNOxLifetmFlCnsBin14 : 416|32@1+ (0.05,0) [0|210554060.75] "l" Vector__XXX
SG_ NOxTrackValdNOxLifetmFlCnsBin15 : 448|32@1+ (0.05,0) [0|210554060.75] "l" Vector__XXX
SG_ NOxTrackValdNOxLifetmFlCnsBin16 : 480|32@1+ (0.05,0) [0|210554060.75] "l" Vector__XXX
SG_ NOxTrackValdNOxLifetmFlCnsBin17 : 512|32@1+ (0.05,0) [0|210554060.75] "l" Vector__XXX

CM_ BO_ 2364624894 "Engine Cylinder 11 Combustion Pressures";
CM_ BO_ 2364625150 "Engine Cylinder 12 Combustion Pressures";
CM_ BO_ 2364625406 "Engine Cylinder 13 Combustion Pressures";
CM_ BO_ 2364625662 "Engine Cylinder 14 Combustion Pressures";
CM_ BO_ 2364625918 "Engine Cylinder 15 Combustion Pressures";
CM_ BO_ 2364626174 "Engine Cylinder 16 Combustion Pressures";
CM_ BO_ 2364626430 "Engine Cylinder 17 Combustion Pressures";
CM_ BO_ 2364626686 "Engine Cylinder 18 Combustion Pressures";
CM_ BO_ 2364626942 "Engine Cylinder 19 Combustion Pressures";
CM_ BO_ 2364627198 "Engine Cylinder 20 Combustion Pressures";
CM_ BO_ 2364627454 "Engine Cylinder 1 Combustion Timing";
CM_ BO_ 2364627710 "Engine Cylinder 2 Combustion Timing";
CM_ BO_ 2364627966 "Engine Cylinder 3 Combustion Timing";
CM_ BO_ 2364628222 "Engine Cylinder 4 Combustion Timing";
CM_ BO_ 2364628478 "Engine Cylinder 5 Combustion Timing";
CM_ BO_ 2364628734 "Engine Cylinder 6 Combustion Timing";
CM_ BO_ 2364628990 "Engine Cylinder 7 Combustion Timing";
CM_ BO_ 2364629246 "Engine Cylinder 8 Combustion Timing";
CM_ BO_ 2364629502 "Engine Cylinder 9 Combustion Timing";
CM_ BO_ 2364629758 "Engine Cylinder 10 Combustion Timing";
CM_ BO_ 2364630014 "Engine Cylinder 11 Combustion Timing";
CM_ BO_ 2364630270 "Engine Cylinder 12 Combustion Timing";
CM_ BO_ 2364630526 "Engine Cylinder 13 Combustion Timing";
CM_ BO_ 2364630782 "Engine Cylinder 14 Combustion Timing";
CM_ BO_ 2364631038 "Engine Cylinder 15 Combustion Timing";
CM_ BO_ 2364631294 "Engine Cylinder 16 Combustion Timing";
CM_ BO_ 2364631550 "Engine Cylinder 17 Combustion Timing";
CM_ BO_ 2364631806 "Engine Cylinder 18 Combustion Timing";
CM_ BO_ 2364632062 "Engine Cylinder 19 Combustion Timing";
CM_ BO_ 2364632318 "Engine Cylinder 20 Combustion Timing";
CM_ BO_ 2364632574 "Engine Cylinder 1 Combustion Metrics";
CM_ BO_ 2364632830 "Engine Cylinder 2 Combustion Metrics";
CM_ BO_ 2364633086 "Engine Cylinder 3 Combustion Metrics";
CM_ BO_ 2364633342 "Engine Cylinder 4 Combustion Metrics";
CM_ BO_ 2364633598 "Engine Cylinder 5 Combustion Metrics";
CM_ BO_ 2364633854 "Engine Cylinder 6 Combustion Metrics";
CM_ BO_ 2364634110 "Engine Cylinder 7 Combustion Metrics";
CM_ BO_ 2364634366 "Engine Cylinder 8 Combustion Metrics";
CM_ BO_ 2364634622 "Engine Cylinder 9 Combustion Metrics";
CM_ BO_ 2364634878 "Engine Cylinder 10 Combustion Metrics";
CM_ BO_ 2364635134 "Engine Cylinder 11 Combustion Metrics";
CM_ BO_ 2364635390 "Engine Cylinder 12 Combustion Metrics";
CM_ BO_ 2364635646 "Engine Cylinder 13 Combustion Metrics";
CM_ BO_ 2364635902 "Engine Cylinder 14 Combustion Metrics";
CM_ BO_ 2364636158 "Engine Cylinder 15 Combustion Metrics";
CM_ BO_ 2364636414 "Engine Cylinder 16 Combustion Metrics";
CM_ BO_ 2364636670 "Engine Cylinder 17 Combustion Metrics";
CM_ BO_ 2364636926 "Engine Cylinder 18 Combustion Metrics";
CM_ BO_ 2364637182 "Engine Cylinder 19 Combustion Metrics";
CM_ BO_ 2364637438 "Engine Cylinder 20 Combustion Metrics";
CM_ BO_ 2364637694 "Motor/Generator 1 Inverter Mode Feedback 1";
CM_ BO_ 2565964542 "Motor/Generator 1 Inverter Limits Active Power";
CM_ BO_ 2565964798 "Motor/Generator 1 Inverter Limits Active Mechanical";
CM_ BO_ 2565965054 "Motor/Generator 1 Inverter Limits Active DC Side";
CM_ BO_ 2565965310 "Motor/Generator 1 Inverter Low Voltage";
CM_ BO_ 2364638974 "Motor/Generator 2 Inverter Mode Feedback 1";
CM_ BO_ 2565965822 "Motor/Generator 2 Inverter Limits Active Power";
CM_ BO_ 2565966078 "Motor/Generator 2 Inverter Limits Active Mechanical";
CM_ BO_ 2565966334 "Motor/Generator 2 Inverter Limits Active DC Side";
CM_ BO_ 2565966590 "Motor/Generator 2 Inverter Low Voltage";
CM_ BO_ 2565966846 "Motor/Generator 1 Inverter Status 2";
CM_ BO_ 2565967102 "Motor/Generator 1 Inverter Rate Limits Active 1";
CM_ BO_ 2565967358 "Motor/Generator 2 Inverter Status 2";
CM_ BO_ 2565967614 "Motor/Generator 2 Inverter Rate Limits Active 1";
CM_ BO_ 2297532414 "Impostor PG Alert";
CM_ BO_ 2364641534 "High Voltage Energy Storage Pack 1 Status 2";
CM_ BO_ 2364641790 "High Voltage Energy Storage Pack 1 Data 1";
CM_ BO_ 2364642046 "High Voltage Energy Storage Pack 1 Data 2";
CM_ BO_ 2364642302 "High Voltage Energy Storage Pack 1 Data 3";
CM_ BO_ 2364642558 "High Voltage Energy Storage Pack 1 Data 4";
CM_ BO_ 2364642814 "High Voltage Energy Storage Pack 1 Data 5";
CM_ BO_ 2364643070 "High Voltage Energy Storage Pack 1 Data 6";
CM_ BO_ 2364643326 "High Voltage Energy Storage Pack 1 Status 1";
CM_ BO_ 2364643582 "High Voltage Energy Storage Pack 1 Data 7";
CM_ BO_ 2364643838 "High Voltage Energy Storage Pack 1 Module Status 1";
CM_ BO_ 2364644094 "High Voltage Energy Storage Pack 1 Thermal Management System Status 1";
CM_ BO_ 2364644350 "High Voltage Energy Storage Pack 1 Data 8";
CM_ BO_ 2364644606 "High Voltage Energy Storage Pack 1 Data 9";
CM_ BO_ 2364644862 "High Voltage Energy Storage Pack 1 Data 10";
CM_ BO_ 2364645118 "High Voltage Energy Storage Pack 1 Data 11";
CM_ BO_ 2364645374 "High Voltage Energy Storage Pack 2 Status 2";
CM_ BO_ 2364645630 "High Voltage Energy Storage Pack 2 Data 1";
CM_ BO_ 2364645886 "High Voltage Energy Storage Pack 2 Data 2";
CM_ BO_ 2364646142 "High Voltage Energy Storage Pack 2 Data 3";
CM_ BO_ 2364646398 "High Voltage Energy Storage Pack 2 Data 4";
CM_ BO_ 2364646654 "High Voltage Energy Storage Pack 2 Data 5";
CM_ BO_ 2364646910 "High Voltage Energy Storage Pack 2 Data 6";
CM_ BO_ 2364647166 "High Voltage Energy Storage Pack 2 Status 1";
CM_ BO_ 2364647422 "High Voltage Energy Storage Pack 2 Data 7";
CM_ BO_ 2364647678 "High Voltage Energy Storage Pack 2 Module Status 1";
CM_ BO_ 2364647934 "High Voltage Energy Storage Pack 2 Thermal Management System Status 1";
CM_ BO_ 2364648190 "High Voltage Energy Storage Pack 2 Data 8";
CM_ BO_ 2364648446 "High Voltage Energy Storage Pack 2 Data 9";
CM_ BO_ 2364648702 "High Voltage Energy Storage Pack 2 Data 10";
CM_ BO_ 2364648958 "High Voltage Energy Storage Pack 2 Data 11";
CM_ BO_ 2364649214 "High Voltage Energy Storage Pack 3 Status 2";
CM_ BO_ 2364649470 "High Voltage Energy Storage Pack 3 Data 1";
CM_ BO_ 2364649726 "High Voltage Energy Storage Pack 3 Data 2";
CM_ BO_ 2364649982 "High Voltage Energy Storage Pack 3 Data 3";
CM_ BO_ 2364650238 "High Voltage Energy Storage Pack 3 Data 4";
CM_ BO_ 2364650494 "High Voltage Energy Storage Pack 3 Data 5";
CM_ BO_ 2364650750 "High Voltage Energy Storage Pack 3 Data 6";
CM_ BO_ 2364651006 "High Voltage Energy Storage Pack 3 Status 1";
CM_ BO_ 2364651262 "High Voltage Energy Storage Pack 3 Data 7";
CM_ BO_ 2364651518 "High Voltage Energy Storage Pack 3 Module Status 1";
CM_ BO_ 2364651774 "High Voltage Energy Storage Pack 3 Thermal Management System Status 1";
CM_ BO_ 2364652030 "High Voltage Energy Storage Pack 3 Data 8";
CM_ BO_ 2364652286 "High Voltage Energy Storage Pack 3 Data 9";
CM_ BO_ 2364652542 "High Voltage Energy Storage Pack 3 Data 10";
CM_ BO_ 2364652798 "High Voltage Energy Storage Pack 3 Data 11";
CM_ BO_ 2364653054 "High Voltage Energy Storage Pack 4 Status 2";
CM_ BO_ 2364653310 "High Voltage Energy Storage Pack 4 Data 1";
CM_ BO_ 2364653566 "High Voltage Energy Storage Pack 4 Data 2";
CM_ BO_ 2364653822 "High Voltage Energy Storage Pack 4 Data 3";
CM_ BO_ 2364654078 "High Voltage Energy Storage Pack 4 Data 4";
CM_ BO_ 2364654334 "High Voltage Energy Storage Pack 4 Data 5";
CM_ BO_ 2364654590 "High Voltage Energy Storage Pack 4 Data 6";
CM_ BO_ 2364654846 "High Voltage Energy Storage Pack 4 Status 1";
CM_ BO_ 2364655102 "High Voltage Energy Storage Pack 4 Data 7";
CM_ BO_ 2364655358 "High Voltage Energy Storage Pack 4 Module Status 1";
CM_ BO_ 2364655614 "High Voltage Energy Storage Pack 4 Thermal Management System Status 1";
CM_ BO_ 2364655870 "High Voltage Energy Storage Pack 4 Data 8";
CM_ BO_ 2364656126 "High Voltage Energy Storage Pack 4 Data 9";
CM_ BO_ 2364656382 "High Voltage Energy Storage Pack 4 Data 10";
CM_ BO_ 2364656638 "High Voltage Energy Storage Pack 4 Data 11";
CM_ BO_ 2364656894 "High Voltage Energy Storage Pack 5 Status 2";
CM_ BO_ 2364657150 "High Voltage Energy Storage Pack 5 Data 1";
CM_ BO_ 2364657406 "High Voltage Energy Storage Pack 5 Data 2";
CM_ BO_ 2364657662 "High Voltage Energy Storage Pack 5 Data 3";
CM_ BO_ 2364657918 "High Voltage Energy Storage Pack 5 Data 4";
CM_ BO_ 2364658174 "High Voltage Energy Storage Pack 5 Data 5";
CM_ BO_ 2364658430 "High Voltage Energy Storage Pack 5 Data 6";
CM_ BO_ 2364658686 "High Voltage Energy Storage Pack 5 Status 1";
CM_ BO_ 2364658942 "High Voltage Energy Storage Pack 5 Data 7";
CM_ BO_ 2364659198 "High Voltage Energy Storage Pack 5 Module Status 1";
CM_ BO_ 2364659454 "High Voltage Energy Storage Pack 5 Thermal Management System Status 1";
CM_ BO_ 2364659710 "High Voltage Energy Storage Pack 5 Data 8";
CM_ BO_ 2364659966 "High Voltage Energy Storage Pack 5 Data 9";
CM_ BO_ 2364660222 "High Voltage Energy Storage Pack 5 Data 10";
CM_ BO_ 2364660478 "High Voltage Energy Storage Pack 5 Data 11";
CM_ BO_ 2364660734 "High Voltage Energy Storage Pack 6 Status 2";
CM_ BO_ 2364660990 "High Voltage Energy Storage Pack 6 Data 1";
CM_ BO_ 2364661246 "High Voltage Energy Storage Pack 6 Data 2";
CM_ BO_ 2364661502 "High Voltage Energy Storage Pack 6 Data 3";
CM_ BO_ 2364661758 "High Voltage Energy Storage Pack 6 Data 4";
CM_ BO_ 2364662014 "High Voltage Energy Storage Pack 6 Data 5";
CM_ BO_ 2364662270 "High Voltage Energy Storage Pack 6 Data 6";
CM_ BO_ 2364662526 "High Voltage Energy Storage Pack 6 Status 1";
CM_ BO_ 2364662782 "High Voltage Energy Storage Pack 6 Data 7";
CM_ BO_ 2364663038 "High Voltage Energy Storage Pack 6 Module Status 1";
CM_ BO_ 2364663294 "High Voltage Energy Storage Pack 6 Thermal Management System Status 1";
CM_ BO_ 2364663550 "High Voltage Energy Storage Pack 6 Data 8";
CM_ BO_ 2364663806 "High Voltage Energy Storage Pack 6 Data 9";
CM_ BO_ 2364664062 "High Voltage Energy Storage Pack 6 Data 10";
CM_ BO_ 2364664318 "High Voltage Energy Storage Pack 6 Data 11";
CM_ BO_ 2364664574 "Motor/Generator 3 Inverter Mode Feedback 1";
CM_ BO_ 2565991422 "Motor/Generator 3 Inverter Limits Active Power";
CM_ BO_ 2565991678 "Motor/Generator 3 Inverter Limits Active Mechanical";
CM_ BO_ 2565991934 "Motor/Generator 3 Inverter Limits Active DC Side";
CM_ BO_ 2565992190 "Motor/Generator 3 Inverter Low Voltage";
CM_ BO_ 2565992446 "Motor/Generator 3 Inverter Status 2";
CM_ BO_ 2565992702 "Motor/Generator 3 Inverter Rate Limits Active 1";
CM_ BO_ 2364666366 "Motor/Generator 4 Inverter Mode Feedback 1";
CM_ BO_ 2565993214 "Motor/Generator 4 Inverter Limits Active Power";
CM_ BO_ 2565993470 "Motor/Generator 4 Inverter Limits Active Mechanical";
CM_ BO_ 2565993726 "Motor/Generator 4 Inverter Limits Active DC Side";
CM_ BO_ 2565993982 "Motor/Generator 4 Inverter Low Voltage";
CM_ BO_ 2565994238 "Motor/Generator 4 Inverter Status 2";
CM_ BO_ 2565994494 "Motor/Generator 4 Inverter Rate Limits Active 1";
CM_ BO_ 2364668158 "Motor/Generator 5 Inverter Mode Feedback 1";
CM_ BO_ 2565995006 "Motor/Generator 5 Inverter Limits Active Power";
CM_ BO_ 2565995262 "Motor/Generator 5 Inverter Limits Active Mechanical";
CM_ BO_ 2565995518 "Motor/Generator 5 Inverter Limits Active DC Side";
CM_ BO_ 2565995774 "Motor/Generator 5 Inverter Low Voltage";
CM_ BO_ 2565996030 "Motor/Generator 5 Inverter Status 2";
CM_ BO_ 2565996286 "Motor/Generator 5 Inverter Rate Limits Active 1";
CM_ BO_ 2364669950 "Motor/Generator 6 Inverter Mode Feedback 1";
CM_ BO_ 2565996798 "Motor/Generator 6 Inverter Limits Active Power";
CM_ BO_ 2565997054 "Motor/Generator 6 Inverter Limits Active Mechanical";
CM_ BO_ 2565997310 "Motor/Generator 6 Inverter Limits Active DC Side";
CM_ BO_ 2565997566 "Motor/Generator 6 Inverter Low Voltage";
CM_ BO_ 2565997822 "Motor/Generator 6 Inverter Status 2";
CM_ BO_ 2565998078 "Motor/Generator 6 Inverter Rate Limits Active 1";
CM_ BO_ 2364671742 "Blind Spot Detection 1";
CM_ BO_ 2364671998 "Winch Information 1";
CM_ BO_ 2364672254 "Motor/Generator 3 Inverter Control";
CM_ BO_ 2565999102 "Motor/Generator 3 Inverter Rate Limits Request 1";
CM_ BO_ 2364672766 "Motor/Generator 4 Inverter Control";
CM_ BO_ 2565999614 "Motor/Generator 4 Inverter Rate Limits Request 1";
CM_ BO_ 2364673278 "Motor/Generator 5 Inverter Control";
CM_ BO_ 2566000126 "Motor/Generator 5 Inverter Rate Limits Request 1";
CM_ BO_ 2364673790 "Motor/Generator 6 Inverter Control";
CM_ BO_ 2566000638 "Motor/Generator 6 Inverter Rate Limits Request 1";
CM_ BO_ 2566581758 "Temperature Sensing Module 1";
CM_ BO_ 2566582014 "Temperature Sensing Module 2";
CM_ BO_ 2566582270 "Aftertreatment 2 SCR Service Information 3";
CM_ BO_ 2566582526 "Aftertreatment 1 SCR Service Information 3";
CM_ BO_ 2566582782 "PSA Times Lifetime Hours";
CM_ BO_ 2566583038 "PSA Times Stored 100 Hours";
CM_ BO_ 2566583294 "PSA Times Active 100 Hours";
CM_ BO_ 2566583550 "Hybrid Charge Depleting or Increasing Operation Lifetime Hours";
CM_ BO_ 2566583806 "Hybrid Charge Depleting or Increasing Operation Stored 100 Hours";
CM_ BO_ 2566584062 "Hybrid Charge Depleting or Increasing Operation Active 100 Hours";
CM_ BO_ 2566584318 "Aftertreatment 1 Historical Information 3";
CM_ BO_ 2566584830 "Aftertreatment 1 SCR 2 NOx Mass and NH3 Storage";
CM_ BO_ 2566585086 "Aftertreatment 1 SCR 1 NOx Mass and NH3 Storage";
CM_ BO_ 2566585342 "Evaporative System Pressure and Control";
CM_ BO_ 2566585598 "GHG Tracking Lifetime Array Data";
CM_ BO_ 2566585854 "GHG Tracking Stored 100 Hour Array Data";
CM_ BO_ 2566586110 "GHG Tracking Active 100 Hour Array Data";
CM_ BO_ 2566586366 "Green House Gas Stored 100 Hour Active Technology Tracking";
CM_ BO_ 2566586622 "Green House Gas Active 100 Hour Active Technology Tracking";
CM_ BO_ 2566586878 "Green House Gas Lifetime Active Technology Tracking";
CM_ BO_ 2566587134 "NOx Tracking Engine Activity Lifetime Fuel Consumption Bins";
CM_ BO_ 2566587390 "NOx Tracking Engine Activity Lifetime Engine Run Time Bins";
CM_ BO_ 2566587646 "NOx Tracking Engine Activity Lifetime Vehicle Distance Bins";
CM_ BO_ 2566587902 "NOx Tracking Engine Activity Lifetime Engine Output Energy Bins";
CM_ BO_ 2566588158 "NOx Tracking Valid NOx Lifetime Fuel Consumption Bins";
BA_DEF_ BO_  "GenMsgCycleTime" INT 0 65535;
BA_DEF_ SG_  "SigType" ENUM "Default","Range","RangeSigned","ASCII","Discrete","Control","ReferencePGN","DTC","StringDelimiter","StringLength","StringLengthControl","MessageCounter","MessageChecksum";
BA_DEF_DEF_  "GenMsgCycleTime" 0;
BA_DEF_DEF_  "SigType" "Default";
BA_ "GenMsgCycleTime" BO_ 2364624894 1000;
BA_ "GenMsgCycleTime" BO_ 2364625150 1000;
BA_ "GenMsgCycleTime" BO_ 2364625406 1000;
BA_ "GenMsgCycleTime" BO_ 2364625662 1000;
BA_ "GenMsgCycleTime" BO_ 2364625918 1000;
BA_ "GenMsgCycleTime" BO_ 2364626174 1000;
BA_ "GenMsgCycleTime" BO_ 2364626430 1000;
BA_ "GenMsgCycleTime" BO_ 2364626686 1000;
BA_ "GenMsgCycleTime" BO_ 2364626942 1000;
BA_ "GenMsgCycleTime" BO_ 2364627198 1000;
BA_ "GenMsgCycleTime" BO_ 2364627454 1000;
BA_ "GenMsgCycleTime" BO_ 2364627710 1000;
BA_ "GenMsgCycleTime" BO_ 2364627966 1000;
BA_ "GenMsgCycleTime" BO_ 2364628222 1000;
BA_ "GenMsgCycleTime" BO_ 2364628478 1000;
BA_ "GenMsgCycleTime" BO_ 2364628734 1000;
BA_ "GenMsgCycleTime" BO_ 2364628990 1000;
BA_ "GenMsgCycleTime" BO_ 2364629246 1000;
BA_ "GenMsgCycleTime" BO_ 2364629502 1000;
BA_ "GenMsgCycleTime" BO_ 2364629758 1000;
BA_ "GenMsgCycleTime" BO_ 2364630014 1000;
BA_ "GenMsgCycleTime" BO_ 2364630270 1000;
BA_ "GenMsgCycleTime" BO_ 2364630526 1000;
BA_ "GenMsgCycleTime" BO_ 2364630782 1000;
BA_ "GenMsgCycleTime" BO_ 2364631038 1000;
BA_ "GenMsgCycleTime" BO_ 2364631294 1000;
BA_ "GenMsgCycleTime" BO_ 2364631550 1000;
BA_ "GenMsgCycleTime" BO_ 2364631806 1000;
BA_ "GenMsgCycleTime" BO_ 2364632062 1000;
BA_ "GenMsgCycleTime" BO_ 2364632318 1000;
BA_ "GenMsgCycleTime" BO_ 2364632574 1000;
BA_ "GenMsgCycleTime" BO_ 2364632830 1000;
BA_ "GenMsgCycleTime" BO_ 2364633086 1000;
BA_ "GenMsgCycleTime" BO_ 2364633342 1000;
BA_ "GenMsgCycleTime" BO_ 2364633598 1000;
BA_ "GenMsgCycleTime" BO_ 2364633854 1000;
BA_ "GenMsgCycleTime" BO_ 2364634110 1000;
BA_ "GenMsgCycleTime" BO_ 2364634366 1000;
BA_ "GenMsgCycleTime" BO_ 2364634622 1000;
BA_ "GenMsgCycleTime" BO_ 2364634878 1000;
BA_ "GenMsgCycleTime" BO_ 2364635134 1000;
BA_ "GenMsgCycleTime" BO_ 2364635390 1000;
BA_ "GenMsgCycleTime" BO_ 2364635646 1000;
BA_ "GenMsgCycleTime" BO_ 2364635902 1000;
BA_ "GenMsgCycleTime" BO_ 2364636158 1000;
BA_ "GenMsgCycleTime" BO_ 2364636414 1000;
BA_ "GenMsgCycleTime" BO_ 2364636670 1000;
BA_ "GenMsgCycleTime" BO_ 2364636926 1000;
BA_ "GenMsgCycleTime" BO_ 2364637182 1000;
BA_ "GenMsgCycleTime" BO_ 2364637438 1000;
BA_ "GenMsgCycleTime" BO_ 2364637694 100;
BA_ "GenMsgCycleTime" BO_ 2565964542 100;
BA_ "GenMsgCycleTime" BO_ 2565964798 100;
BA_ "GenMsgCycleTime" BO_ 2565965054 100;
BA_ "GenMsgCycleTime" BO_ 2565965310 100;
BA_ "GenMsgCycleTime" BO_ 2364638974 100;
BA_ "GenMsgCycleTime" BO_ 2565965822 100;
BA_ "GenMsgCycleTime" BO_ 2565966078 100;
BA_ "GenMsgCycleTime" BO_ 2565966334 100;
BA_ "GenMsgCycleTime" BO_ 2565966590 100;
BA_ "GenMsgCycleTime" BO_ 2565966846 100;
BA_ "GenMsgCycleTime" BO_ 2565967102 100;
BA_ "GenMsgCycleTime" BO_ 2565967358 100;
BA_ "GenMsgCycleTime" BO_ 2565967614 100;
BA_ "GenMsgCycleTime" BO_ 2297532414 1000;
BA_ "GenMsgCycleTime" BO_ 2364641534 100;
BA_ "GenMsgCycleTime" BO_ 2364641790 20;
BA_ "GenMsgCycleTime" BO_ 2364642046 20;
BA_ "GenMsgCycleTime" BO_ 2364642302 20;
BA_ "GenMsgCycleTime" BO_ 2364642558 100;
BA_ "GenMsgCycleTime" BO_ 2364642814 20;
BA_ "GenMsgCycleTime" BO_ 2364643070 100;
BA_ "GenMsgCycleTime" BO_ 2364643326 100;
BA_ "GenMsgCycleTime" BO_ 2364643582 100;
BA_ "GenMsgCycleTime" BO_ 2364643838 100;
BA_ "GenMsgCycleTime" BO_ 2364644094 100;
BA_ "GenMsgCycleTime" BO_ 2364644350 100;
BA_ "GenMsgCycleTime" BO_ 2364644606 100;
BA_ "GenMsgCycleTime" BO_ 2364644862 100;
BA_ "GenMsgCycleTime" BO_ 2364645118 100;
BA_ "GenMsgCycleTime" BO_ 2364645374 100;
BA_ "GenMsgCycleTime" BO_ 2364645630 20;
BA_ "GenMsgCycleTime" BO_ 2364645886 20;
BA_ "GenMsgCycleTime" BO_ 2364646142 20;
BA_ "GenMsgCycleTime" BO_ 2364646398 100;
BA_ "GenMsgCycleTime" BO_ 2364646654 20;
BA_ "GenMsgCycleTime" BO_ 2364646910 100;
BA_ "GenMsgCycleTime" BO_ 2364647166 100;
BA_ "GenMsgCycleTime" BO_ 2364647422 100;
BA_ "GenMsgCycleTime" BO_ 2364647678 100;
BA_ "GenMsgCycleTime" BO_ 2364647934 100;
BA_ "GenMsgCycleTime" BO_ 2364648190 100;
BA_ "GenMsgCycleTime" BO_ 2364648446 100;
BA_ "GenMsgCycleTime" BO_ 2364648702 100;
BA_ "GenMsgCycleTime" BO_ 2364648958 100;
BA_ "GenMsgCycleTime" BO_ 2364649214 100;
BA_ "GenMsgCycleTime" BO_ 2364649470 20;
BA_ "GenMsgCycleTime" BO_ 2364649726 20;
BA_ "GenMsgCycleTime" BO_ 2364649982 20;
BA_ "GenMsgCycleTime" BO_ 2364650238 100;
BA_ "GenMsgCycleTime" BO_ 2364650494 20;
BA_ "GenMsgCycleTime" BO_ 2364650750 100;
BA_ "GenMsgCycleTime" BO_ 2364651006 100;
BA_ "GenMsgCycleTime" BO_ 2364651262 100;
BA_ "GenMsgCycleTime" BO_ 2364651518 100;
BA_ "GenMsgCycleTime" BO_ 2364651774 100;
BA_ "GenMsgCycleTime" BO_ 2364652030 100;
BA_ "GenMsgCycleTime" BO_ 2364652286 100;
BA_ "GenMsgCycleTime" BO_ 2364652542 100;
BA_ "GenMsgCycleTime" BO_ 2364652798 100;
BA_ "GenMsgCycleTime" BO_ 2364653054 100;
BA_ "GenMsgCycleTime" BO_ 2364653310 20;
BA_ "GenMsgCycleTime" BO_ 2364653566 20;
BA_ "GenMsgCycleTime" BO_ 2364653822 20;
BA_ "GenMsgCycleTime" BO_ 2364654078 100;
BA_ "GenMsgCycleTime" BO_ 2364654334 20;
BA_ "GenMsgCycleTime" BO_ 2364654590 100;
BA_ "GenMsgCycleTime" BO_ 2364654846 100;
BA_ "GenMsgCycleTime" BO_ 2364655102 100;
BA_ "GenMsgCycleTime" BO_ 2364655358 100;
BA_ "GenMsgCycleTime" BO_ 2364655614 100;
BA_ "GenMsgCycleTime" BO_ 2364655870 100;
BA_ "GenMsgCycleTime" BO_ 2364656126 100;
BA_ "GenMsgCycleTime" BO_ 2364656382 100;
BA_ "GenMsgCycleTime" BO_ 2364656638 100;
BA_ "GenMsgCycleTime" BO_ 2364656894 100;
BA_ "GenMsgCycleTime" BO_ 2364657150 20;
BA_ "GenMsgCycleTime" BO_ 2364657406 20;
BA_ "GenMsgCycleTime" BO_ 2364657662 20;
BA_ "GenMsgCycleTime" BO_ 2364657918 100;
BA_ "GenMsgCycleTime" BO_ 2364658174 20;
BA_ "GenMsgCycleTime" BO_ 2364658430 100;
BA_ "GenMsgCycleTime" BO_ 2364658686 100;
BA_ "GenMsgCycleTime" BO_ 2364658942 100;
BA_ "GenMsgCycleTime" BO_ 2364659198 100;
BA_ "GenMsgCycleTime" BO_ 2364659454 100;
BA_ "GenMsgCycleTime" BO_ 2364659710 100;
BA_ "GenMsgCycleTime" BO_ 2364659966 100;
BA_ "GenMsgCycleTime" BO_ 2364660222 100;
BA_ "GenMsgCycleTime" BO_ 2364660478 100;
BA_ "GenMsgCycleTime" BO_ 2364660734 100;
BA_ "GenMsgCycleTime" BO_ 2364660990 20;
BA_ "GenMsgCycleTime" BO_ 2364661246 20;
BA_ "GenMsgCycleTime" BO_ 2364661502 20;
BA_ "GenMsgCycleTime" BO_ 2364661758 100;
BA_ "GenMsgCycleTime" BO_ 2364662014 20;
BA_ "GenMsgCycleTime" BO_ 2364662270 100;
BA_ "GenMsgCycleTime" BO_ 2364662526 100;
BA_ "GenMsgCycleTime" BO_ 2364662782 100;
BA_ "GenMsgCycleTime" BO_ 2364663038 100;
BA_ "GenMsgCycleTime" BO_ 2364663294 100;
BA_ "GenMsgCycleTime" BO_ 2364663550 100;
BA_ "GenMsgCycleTime" BO_ 2364663806 100;
BA_ "GenMsgCycleTime" BO_ 2364664062 100;
BA_ "GenMsgCycleTime" BO_ 2364664318 100;
BA_ "GenMsgCycleTime" BO_ 2364664574 100;
BA_ "GenMsgCycleTime" BO_ 2565991422 100;
BA_ "GenMsgCycleTime" BO_ 2565991678 100;
BA_ "GenMsgCycleTime" BO_ 2565991934 100;
BA_ "GenMsgCycleTime" BO_ 2565992190 100;
BA_ "GenMsgCycleTime" BO_ 2565992446 100;
BA_ "GenMsgCycleTime" BO_ 2565992702 100;
BA_ "GenMsgCycleTime" BO_ 2364666366 100;
BA_ "GenMsgCycleTime" BO_ 2565993214 100;
BA_ "GenMsgCycleTime" BO_ 2565993470 100;
BA_ "GenMsgCycleTime" BO_ 2565993726 100;
BA_ "GenMsgCycleTime" BO_ 2565993982 100;
BA_ "GenMsgCycleTime" BO_ 2565994238 100;
BA_ "GenMsgCycleTime" BO_ 2565994494 100;
BA_ "GenMsgCycleTime" BO_ 2364668158 100;
BA_ "GenMsgCycleTime" BO_ 2565995006 100;
BA_ "GenMsgCycleTime" BO_ 2565995262 100;
BA_ "GenMsgCycleTime" BO_ 2565995518 100;
BA_ "GenMsgCycleTime" BO_ 2565995774 100;
BA_ "GenMsgCycleTime" BO_ 2565996030 100;
BA_ "GenMsgCycleTime" BO_ 2565996286 100;
BA_ "GenMsgCycleTime" BO_ 2364669950 100;
BA_ "GenMsgCycleTime" BO_ 2565996798 100;
BA_ "GenMsgCycleTime" BO_ 2565997054 100;
BA_ "GenMsgCycleTime" BO_ 2565997310 100;
BA_ "GenMsgCycleTime" BO_ 2565997566 100;
BA_ "GenMsgCycleTime" BO_ 2565997822 100;
BA_ "GenMsgCycleTime" BO_ 2565998078 100;
BA_ "GenMsgCycleTime" BO_ 2364671742 50;
BA_ "GenMsgCycleTime" BO_ 2364671998 20;
BA_ "GenMsgCycleTime" BO_ 2364672254 10;
BA_ "GenMsgCycleTime" BO_ 2565999102 100;
BA_ "GenMsgCycleTime" BO_ 2364672766 10;
BA_ "GenMsgCycleTime" BO_ 2565999614 100;
BA_ "GenMsgCycleTime" BO_ 2364673278 10;
BA_ "GenMsgCycleTime" BO_ 2566000126 100;
BA_ "GenMsgCycleTime" BO_ 2364673790 10;
BA_ "GenMsgCycleTime" BO_ 2566000638 100;
BA_ "GenMsgCycleTime" BO_ 2566581758 1000;
BA_ "GenMsgCycleTime" BO_ 2566582014 1000;
BA_ "GenMsgCycleTime" BO_ 2566584830 1000;
BA_ "GenMsgCycleTime" BO_ 2566585086 1000;
VAL_ 2364637694 MtrGen1InvertCtrlLmtsOverrideMde 1 "Torque Limits Mode" 2 "Speed Limits Mode" 3 "DC Side Voltage Limits Mode" 4 "DC Side Current Limits Mode" 5 "DC Side Power Limits Mode" 6 "Mechanical Power Limits Mode" 7 "SAE Reserved" 14 "Error" 15 "Not Available" ;
VAL_ 2364637694 MotorGen1InvertCtrlSetpointMode 0 "Powered On" 1 "Waiting for Operational conditions" 2 "Standby" 3 "SAE Reserved" 4 "SAE Reserved" 5 "Manufacturer specific passive mode 1" 6 "Manufacturer specific passive mode 2" 7 "Torque Control Mode" 8 "Speed Control Mode" 9 "DC Side Voltage Mode" 10 "DC Side Current Mode" 11 "Mechanical Power Control Mode" 12 "DC Power Control Mode" 13 "DC Side Voltage Control Mode" 14 "SAE Reserved" 15 "SAE Reserved" 16 "SAE Reserved" 17 "SAE Reserved" 18 "Manufacturer specific active mode 1" 19 "Manufacturer specific active mode 2" 20 "Inverter active discharge mode" 21 "Inverter power down command" 22 "SAE Reserved" 23 "SAE Reserved" 24 "SAE Reserved" 25 "SAE Reserved" 26 "SAE Reserved" 27 "SAE Reserved" 28 "Manufacturer specific special mode 1" 29 "Manufacturer specific special mode 2" 30 "Error" 31 "Not Available" ;
VAL_ 2364637694 MotorGen1InverterHVILStatus 0 "HVIL Closed" 1 "HVIL Open" 2 "Error" 3 "Not Available" ;
VAL_ 2364638974 MtrGen2InvertCtrlLmtsOverrideMde 0 "Operating limits are not overridden" 1 "Torque Limits Mode" 2 "Speed Limits Mode" 3 "DC Side Voltage Limits Mode" 4 "DC Side Current Limits Mode" 5 "DC Side Power Limits Mode" 6 "Mechanical Power Limits Mode" 7 "SAE Reserved" 14 "Error" 15 "Not Available" ;
VAL_ 2364638974 MotorGen2InvertCtrlSetpointMode 0 "Powered On" 1 "Waiting for Operational conditions" 2 "Standby" 3 "SAE Reserved" 4 "SAE Reserved" 5 "Manufacturer specific passive mode 1" 6 "Manufacturer specific passive mode 2" 7 "Torque Control Mode" 8 "Speed Control Mode" 9 "DC Side Voltage Mode" 10 "DC Side Current Mode" 11 "Mechanical Power Control Mode" 12 "DC Power Control Mode" 13 "DC Side Voltage Control Mode" 14 "SAE Reserved" 15 "SAE Reserved" 16 "SAE Reserved" 17 "SAE Reserved" 18 "Manufacturer specific active mode 1" 19 "Manufacturer specific active mode 2" 20 "Inverter active discharge mode" 21 "Inverter power down command" 22 "SAE Reserved" 23 "SAE Reserved" 24 "SAE Reserved" 25 "SAE Reserved" 26 "SAE Reserved" 27 "SAE Reserved" 28 "Manufacturer specific special mode 1" 29 "Manufacturer specific special mode 2" 30 "Error" 31 "Not Available" ;
VAL_ 2364638974 MotorGen2InverterHVILStatus 0 "HVIL Closed" 1 "HVIL Open" 2 "Error" 3 "Not Available" ;
VAL_ 2364641534 HVESP1DisChrgPowerLmtDTStateChrg 0 "No power limit for this reason" 1 "Power limited for this reason" 2 "Error" 3 "Not Available" ;
VAL_ 2364641534 HVESP1DisChrgPwrLmtDTBattryTemp 0 "No power limit for this reason" 1 "Power limited for this reason" 2 "Error" 3 "Not Available" ;
VAL_ 2364641534 HVESP1DisChrgPwrLmtDTBattDgCond 0 "No power limit for this reason" 1 "Power limited for this reason" 2 "Error" 3 "Not Available" ;
VAL_ 2364641534 HVESP1DisChrgPwrLmtDTBattCellV 0 "No power limit for this reason" 1 "Power limited for this reason" 2 "Error" 3 "Not Available" ;
VAL_ 2364641534 HVESP1DisChrgPwrLmtDTBattryCurr 0 "No power limit for this reason" 1 "Power limited for this reason" 2 "Error" 3 "Not Available" ;
VAL_ 2364641534 HVESP1DisChrgPwrLmtDTUndefCause 0 "No power limit for this reason" 1 "Power limited for this reason" 2 "Error" 3 "Not Available" ;
VAL_ 2364641534 HVESP1ChrgPowerLimitDTStateChrg 0 "No power limit for this reason" 1 "Power limited for this reason" 2 "Error" 3 "Not Available" ;
VAL_ 2364641534 HVESP1ChrgPwrLmtDTBattryTemp 0 "No power limit for this reason" 1 "Power limited for this reason" 2 "Error" 3 "Not Available" ;
VAL_ 2364641534 HVESP1ChrgPwrLmtDTBattDiagCondtn 0 "No power limit for this reason" 1 "Power limited for this reason" 2 "Error" 3 "Not Available" ;
VAL_ 2364641534 HVESP1ChrgPwrLmtDTBattryCellVltg 0 "No power limit for this reason" 1 "Power limited for this reason" 2 "Error" 3 "Not Available" ;
VAL_ 2364641534 HVESP1ChrgPowerLimitDTBattryCurr 0 "No power limit for this reason" 1 "Power limited for this reason" 2 "Error" 3 "Not Available" ;
VAL_ 2364641534 HVESP1ChrgPwrLmtDTUndefinedCause 0 "No power limit for this reason" 1 "Power limited for this reason" 2 "Error" 3 "Not Available" ;
VAL_ 2364642046 HVESP1CellVoltageDiffStatus 0 "Cell-to-cell voltage differential is within acceptable limits" 1 "Cell-to-cell voltage differential exceeds acceptable limits but can be corrected via auto-balancing" 2 "Cell-to-cell voltage differential exceeds acceptable limits to a point where external maintenance balancing is required to restore battery performance" 3 "Cell-to-cell voltage differential exceeds acceptable limits to a point where external maintenance balancing cannot restore battery performance" 4 "Cell-to-cell voltage differential exceeds acceptable limits" 5 "Reserved" 14 "Error" 15 "Not Available" ;
VAL_ 2364642302 HVESP1CellTemperatureDiffStatus 0 "Cell-to-cell temperature differential is within acceptable limits" 1 "Cell-to-cell temperature differential exceeds acceptable limits" 2 "Error" 3 "Not Available" ;
VAL_ 2364643326 HVESP1HghVoltageBusPosContctStat 0 "Contactor Open" 1 "Contactor Closed" 2 "Error" 3 "Not Available" ;
VAL_ 2364643326 HVESP1HghVoltageBusNegContctStat 0 "Contactor Open" 1 "Contactor Closed" 2 "Error" 3 "Not Available" ;
VAL_ 2364643326 HVESP1HghVltgBusDiscnnctFrwrng 0 "Disconnect not pending" 1 "Disconnect imminent due to battery pack voltage approaching minimum acceptable level" 2 "Disconnect imminent due to battery pack voltage approaching maximum acceptable level" 3 "Disconnect imminent due to module voltage approaching minimum acceptable level" 4 "Disconnect imminent due to module voltage approaching maximum acceptable level" 5 "Disconnect imminent due to cell voltage approaching minimum acceptable level" 6 "Disconnect imminent due to cell voltage approaching maximum acceptable level" 7 "Disconnect imminent due to battery pack current approaching maximum acceptable level" 8 "Reserved" 13 "Disconnect imminent" 14 "Error" 15 "Not Available" ;
VAL_ 2364643326 HVESP1HghVltgBusPreChrgRelyStat 0 "Relay Open" 1 "Relay Closed" 2 "Error" 3 "Not Available" ;
VAL_ 2364643326 HVESP1CenterOfPackContactorState 0 "Contactor Open" 1 "Contactor Closed" 2 "Error" 3 "Not Available" ;
VAL_ 2364643326 HVESP1HiVltgBusActIsoltnTestStat 0 "No test requested / No test in process" 1 "Test requested but not yet in process" 2 "Test in process" 3 "Test complete - isolation acceptable" 4 "Test complete - isolation marginal" 5 "Test complete - isolation fault" 6 "Reserved" 14 "Error" 15 "Not available" ;
VAL_ 2364643326 HVESP1HiVltgBusPassIsoltnTestSt 0 "No test requested / No test in process" 1 "Test requested but not yet in process" 2 "Test in process" 3 "Test complete - isolation acceptable" 4 "Test complete - isolation marginal" 5 "Test complete - isolation fault" 6 "Reserved" 14 "Error" 15 "Not available" ;
VAL_ 2364643326 HVESP1HVILStatus 0 "HVIL Closed" 1 "HVIL Open" 2 "Error" 3 "Not Available" ;
VAL_ 2364643326 HVESP1InertiaSwitchStatus 0 "No impact sensed" 1 "Impact sensed" 2 "Error" 3 "Not Available" ;
VAL_ 2364643326 HVESP1StateOfChargeStatus 0 "SOC level is acceptable" 1 "SOC is approaching its recommended lower limit" 2 "SOC is at its recommended lower limit" 3 "SOC is below its recommended lower limit" 4 "SOC is approaching its recommended upper limit" 5 "SOC is at its recommended upper limit" 6 "SOC is above its recommended upper limit" 7 "Reserved" 14 "Error" 15 "Not  Available" ;
VAL_ 2364643326 HVESP1CellBalanceStatus 0 "Cells are balanced" 1 "Cells are unbalanced" 2 "Error" 3 "Not Available" ;
VAL_ 2364643326 HVESP1CellBalancingActive 0 "Cell balancing is not active" 1 "Cell balancing is active" 2 "Error" 3 "Not Available" ;
VAL_ 2364643326 HVESP1InternalChargerStatus 0 "Charging off" 1 "Charging on" 2 "Error" 3 "Not Available" ;
VAL_ 2364643326 HVESP1HghVoltageBusConnectnStat 0 "Disconnected" 1 "Connected" 2 "Connection in Process" 3 "Disconnection in Process" 4 "Disconnected - Precharge Failed" 5 "Reserved" 14 "Error" 15 "Not Available" ;
VAL_ 2364643326 HVESP1OperationalStatus 0 "Initialization in Process" 1 "Initialization Complete, awaiting Operation Consent" 2 "Operational" 3 "Normal Power-Down in Process" 4 "Emergency Power-Down In Process" 5 "Disabled by external command" 6 "Disabled by internal decision of HVES controller" 7 "Reserved" 14 "Error" 15 "Not Available" ;
VAL_ 2364643838 HVESP1Module1OperationalStatus 0 "Not Operational" 1 "Operational" 2 "Error" 3 "Not Available" ;
VAL_ 2364643838 HVESP1Module2OperationalStatus 0 "Not Operational" 1 "Operational" 2 "Error" 3 "Not Available" ;
VAL_ 2364643838 HVESP1Module3OperationalStatus 0 "Not Operational" 1 "Operational" 2 "Error" 3 "Not Available" ;
VAL_ 2364643838 HVESP1Module4OperationalStatus 0 "Not Operational" 1 "Operational" 2 "Error" 3 "Not Available" ;
VAL_ 2364643838 HVESP1Module5OperationalStatus 0 "Not Operational" 1 "Operational" 2 "Error" 3 "Not Available" ;
VAL_ 2364643838 HVESP1Module6OperationalStatus 0 "Not Operational" 1 "Operational" 2 "Error" 3 "Not Available" ;
VAL_ 2364643838 HVESP1Module7OperationalStatus 0 "Not Operational" 1 "Operational" 2 "Error" 3 "Not Available" ;
VAL_ 2364643838 HVESP1Module8OperationalStatus 0 "Not Operational" 1 "Operational" 2 "Error" 3 "Not Available" ;
VAL_ 2364643838 HVESP1Module9OperationalStatus 0 "Not Operational" 1 "Operational" 2 "Error" 3 "Not Available" ;
VAL_ 2364643838 HVESP1Module10OperationalStatus 0 "Not Operational" 1 "Operational" 2 "Error" 3 "Not Available" ;
VAL_ 2364643838 HVESP1Module11OperationalStatus 0 "Not Operational" 1 "Operational" 2 "Error" 3 "Not Available" ;
VAL_ 2364643838 HVESP1Module12OperationalStatus 0 "Not Operational" 1 "Operational" 2 "Error" 3 "Not Available" ;
VAL_ 2364643838 HVESP1Module13OperationalStatus 0 "Not Operational" 1 "Operational" 2 "Error" 3 "Not Available" ;
VAL_ 2364643838 HVESP1Module14OperationalStatus 0 "Not Operational" 1 "Operational" 2 "Error" 3 "Not Available" ;
VAL_ 2364643838 HVESP1Module15OperationalStatus 0 "Not Operational" 1 "Operational" 2 "Error" 3 "Not Available" ;
VAL_ 2364643838 HVESP1Module16OperationalStatus 0 "Not Operational" 1 "Operational" 2 "Error" 3 "Not Available" ;
VAL_ 2364644094 HVESP1ThermalMangmntSysHtrStat 0 "Heater Off" 1 "Heater On" 2 "Error" 3 "Not Available" ;
VAL_ 2364644094 HVESP1ThermalMangmntSysHVILStat 0 "HVIL Closed" 1 "HVIL Open" 2 "Error" 3 "Not Available" ;
VAL_ 2364644094 HVESP1ThermalMangmntSystemMode 0 "Off" 1 "Circulating" 2 "Cooling" 3 "Heating" 4 "Drying" 5 "Reserved" 14 "Faulted" 15 "Not Available" ;
VAL_ 2364645374 HVESP2DisChrgPowerLmtDTStateChrg 0 "No power limit for this reason" 1 "Power limited for this reason" 2 "Error" 3 "Not Available" ;
VAL_ 2364645374 HVESP2DisChrgPwrLmtDTBattryTemp 0 "No power limit for this reason" 1 "Power limited for this reason" 2 "Error" 3 "Not Available" ;
VAL_ 2364645374 HVESP2DisChrgPwrLmtDTBattDgCond 0 "No power limit for this reason" 1 "Power limited for this reason" 2 "Error" 3 "Not Available" ;
VAL_ 2364645374 HVESP2DisChrgPwrLmtDTBattCellV 0 "No power limit for this reason" 1 "Power limited for this reason" 2 "Error" 3 "Not Available" ;
VAL_ 2364645374 HVESP2DisChrgPwrLmtDTBattryCurr 0 "No power limit for this reason" 1 "Power limited for this reason" 2 "Error" 3 "Not Available" ;
VAL_ 2364645374 HVESP2DisChrgPwrLmtDTUndefCause 0 "No power limit for this reason" 1 "Power limited for this reason" 2 "Error" 3 "Not Available" ;
VAL_ 2364645374 HVESP2ChrgPowerLimitDTStateChrg 0 "No power limit for this reason" 1 "Power limited for this reason" 2 "Error" 3 "Not Available" ;
VAL_ 2364645374 HVESP2ChrgPwrLmtDTBattryTemp 0 "No power limit for this reason" 1 "Power limited for this reason" 2 "Error" 3 "Not Available" ;
VAL_ 2364645374 HVESP2ChrgPwrLmtDTBattDiagCondtn 0 "No power limit for this reason" 1 "Power limited for this reason" 2 "Error" 3 "Not Available" ;
VAL_ 2364645374 HVESP2ChrgPwrLmtDTBattryCellVltg 0 "No power limit for this reason" 1 "Power limited for this reason" 2 "Error" 3 "Not Available" ;
VAL_ 2364645374 HVESP2ChrgPowerLimitDTBattryCurr 0 "No power limit for this reason" 1 "Power limited for this reason" 2 "Error" 3 "Not Available" ;
VAL_ 2364645374 HVESP2ChrgPwrLmtDTUndefinedCause 0 "No power limit for this reason" 1 "Power limited for this reason" 2 "Error" 3 "Not Available" ;
VAL_ 2364645886 HVESP2CellVoltageDiffStatus 0 "Cell-to-cell voltage differential is within acceptable limits" 1 "Cell-to-cell voltage differential exceeds acceptable limits but can be corrected via auto-balancing" 2 "Cell-to-cell voltage differential exceeds acceptable limits to a point where external maintenance balancing is required to restore battery performance" 3 "Cell-to-cell voltage differential exceeds acceptable limits to a point where external maintenance balancing cannot restore battery performance" 4 "Cell-to-cell voltage differential exceeds acceptable limits" 5 "Reserved" 14 "Error" 15 "Not Available" ;
VAL_ 2364646142 HVESP2CellTemperatureDiffStatus 0 "Cell-to-cell temperature differential is within acceptable limits" 1 "Cell-to-cell temperature differential exceeds acceptable limits" 2 "Error" 3 "Not Available" ;
VAL_ 2364647166 HVESP2HghVoltageBusPosContctStat 0 "Contactor Open" 1 "Contactor Closed" 2 "Error" 3 "Not Available" ;
VAL_ 2364647166 HVESP2HghVoltageBusNegContctStat 0 "Contactor Open" 1 "Contactor Closed" 2 "Error" 3 "Not Available" ;
VAL_ 2364647166 HVESP2HghVltgBusDiscnnctFrwrng 0 "Disconnect not pending" 1 "Disconnect imminent due to battery pack voltage approaching minimum acceptable level" 2 "Disconnect imminent due to battery pack voltage approaching maximum acceptable level" 3 "Disconnect imminent due to module voltage approaching minimum acceptable level" 4 "Disconnect imminent due to module voltage approaching maximum acceptable level" 5 "Disconnect imminent due to cell voltage approaching minimum acceptable level" 6 "Disconnect imminent due to cell voltage approaching maximum acceptable level" 7 "Disconnect imminent due to battery pack current approaching maximum acceptable level" 8 "Reserved" 13 "Disconnect imminent" 14 "Error" 15 "Not Available" ;
VAL_ 2364647166 HVESP2HghVltgBusPreChrgRelyStat 0 "Relay Open" 1 "Relay Closed" 2 "Error" 3 "Not Available" ;
VAL_ 2364647166 HVESP2CenterOfPackContactorState 0 "Contactor Open" 1 "Contactor Closed" 2 "Error" 3 "Not Available" ;
VAL_ 2364647166 HVESP2HiVltgBusActIsoltnTestStat 0 "No test requested / No test in process" 1 "Test requested but not yet in process" 2 "Test in process" 3 "Test complete - isolation acceptable" 4 "Test complete - isolation marginal" 5 "Test complete - isolation fault" 6 "Reserved" 14 "Error" 15 "Not available" ;
VAL_ 2364647166 HVESP2HiVltgBusPassIsoltnTestSt 0 "No test requested / No test in process" 1 "Test requested but not yet in process" 2 "Test in process" 3 "Test complete - isolation acceptable" 4 "Test complete - isolation marginal" 5 "Test complete - isolation fault" 6 "Reserved" 14 "Error" 15 "Not available" ;
VAL_ 2364647166 HVESP2HVILStatus 0 "HVIL Closed" 1 "HVIL Open" 2 "Error" 3 "Not Available" ;
VAL_ 2364647166 HVESP2InertiaSwitchStatus 0 "No impact sensed" 1 "Impact sensed" 2 "Error" 3 "Not Available" ;
VAL_ 2364647166 HVESP2StateOfChargeStatus 0 "SOC level is acceptable" 1 "SOC is approaching its recommended lower limit" 2 "SOC is at its recommended lower limit" 3 "SOC is below its recommended lower limit" 4 "SOC is approaching its recommended upper limit" 5 "SOC is at its recommended upper limit" 6 "SOC is above its recommended upper limit" 7 "Reserved" 14 "Error" 15 "Not  Available" ;
VAL_ 2364647166 HVESP2CellBalanceStatus 0 "Cells are balanced" 1 "Cells are unbalanced" 2 "Error" 3 "Not Available" ;
VAL_ 2364647166 HVESP2CellBalancingActive 0 "Cell balancing is not active" 1 "Cell balancing is active" 2 "Error" 3 "Not Available" ;
VAL_ 2364647166 HVESP2InternalChargerStatus 0 "Charging off" 1 "Charging on" 2 "Error" 3 "Not Available" ;
VAL_ 2364647166 HVESP2HghVoltageBusConnectnStat 0 "Disconnected" 1 "Connected" 2 "Connection in Process" 3 "Disconnection in Process" 4 "Disconnected - Precharge Failed" 5 "Reserved" 14 "Error" 15 "Not Available" ;
VAL_ 2364647166 HVESP2OperationalStatus 0 "Initialization in Process" 1 "Initialization Complete, awaiting Operation Consent" 2 "Operational" 3 "Normal Power-Down in Process" 4 "Emergency Power-Down In Process" 5 "Disabled by external command" 6 "Disabled by internal decision of HVES controller" 7 "Reserved" 14 "Error" 15 "Not Available" ;
VAL_ 2364647678 HVESP2Module1OperationalStatus 0 "Not Operational" 1 "Operational" 2 "Error" 3 "Not Available" ;
VAL_ 2364647678 HVESP2Module2OperationalStatus 0 "Not Operational" 1 "Operational" 2 "Error" 3 "Not Available" ;
VAL_ 2364647678 HVESP2Module3OperationalStatus 0 "Not Operational" 1 "Operational" 2 "Error" 3 "Not Available" ;
VAL_ 2364647678 HVESP2Module4OperationalStatus 0 "Not Operational" 1 "Operational" 2 "Error" 3 "Not Available" ;
VAL_ 2364647678 HVESP2Module5OperationalStatus 0 "Not Operational" 1 "Operational" 2 "Error" 3 "Not Available" ;
VAL_ 2364647678 HVESP2Module6OperationalStatus 0 "Not Operational" 1 "Operational" 2 "Error" 3 "Not Available" ;
VAL_ 2364647678 HVESP2Module7OperationalStatus 0 "Not Operational" 1 "Operational" 2 "Error" 3 "Not Available" ;
VAL_ 2364647678 HVESP2Module8OperationalStatus 0 "Not Operational" 1 "Operational" 2 "Error" 3 "Not Available" ;
VAL_ 2364647678 HVESP2Module9OperationalStatus 0 "Not Operational" 1 "Operational" 2 "Error" 3 "Not Available" ;
VAL_ 2364647678 HVESP2Module10OperationalStatus 0 "Not Operational" 1 "Operational" 2 "Error" 3 "Not Available" ;
VAL_ 2364647678 HVESP2Module11OperationalStatus 0 "Not Operational" 1 "Operational" 2 "Error" 3 "Not Available" ;
VAL_ 2364647678 HVESP2Module12OperationalStatus 0 "Not Operational" 1 "Operational" 2 "Error" 3 "Not Available" ;
VAL_ 2364647678 HVESP2Module13OperationalStatus 0 "Not Operational" 1 "Operational" 2 "Error" 3 "Not Available" ;
VAL_ 2364647678 HVESP2Module14OperationalStatus 0 "Not Operational" 1 "Operational" 2 "Error" 3 "Not Available" ;
VAL_ 2364647678 HVESP2Module15OperationalStatus 0 "Not Operational" 1 "Operational" 2 "Error" 3 "Not Available" ;
VAL_ 2364647678 HVESP2Module16OperationalStatus 0 "Not Operational" 1 "Operational" 2 "Error" 3 "Not Available" ;
VAL_ 2364647934 HVESP2ThermalMangmntSysHtrStat 0 "Heater Off" 1 "Heater On" 2 "Error" 3 "Not Available" ;
VAL_ 2364647934 HVESP2ThermalMangmntSysHVILStat 0 "HVIL Closed" 1 "HVIL Open" 2 "Error" 3 "Not Available" ;
VAL_ 2364647934 HVESP2ThermalMangmntSystemMode 0 "Off" 1 "Circulating" 2 "Cooling" 3 "Heating" 4 "Drying" 5 "Reserved" 14 "Faulted" 15 "Not Available" ;
VAL_ 2364649214 HVESP3DisChrgPowerLmtDTStateChrg 0 "No power limit for this reason" 1 "Power limited for this reason" 2 "Error" 3 "Not Available" ;
VAL_ 2364649214 HVESP3DisChrgPwrLmtDTBattryTemp 0 "No power limit for this reason" 1 "Power limited for this reason" 2 "Error" 3 "Not Available" ;
VAL_ 2364649214 HVESP3DisChrgPwrLmtDTBattDgCond 0 "No power limit for this reason" 1 "Power limited for this reason" 2 "Error" 3 "Not Available" ;
VAL_ 2364649214 HVESP3DisChrgPwrLmtDTBattCellV 0 "No power limit for this reason" 1 "Power limited for this reason" 2 "Error" 3 "Not Available" ;
VAL_ 2364649214 HVESP3DisChrgPwrLmtDTBattryCurr 0 "No power limit for this reason" 1 "Power limited for this reason" 2 "Error" 3 "Not Available" ;
VAL_ 2364649214 HVESP3DisChrgPwrLmtDTUndefCause 0 "No power limit for this reason" 1 "Power limited for this reason" 2 "Error" 3 "Not Available" ;
VAL_ 2364649214 HVESP3ChrgPowerLimitDTStateChrg 0 "No power limit for this reason" 1 "Power limited for this reason" 2 "Error" 3 "Not Available" ;
VAL_ 2364649214 HVESP3ChrgPwrLmtDTBattryTemp 0 "No power limit for this reason" 1 "Power limited for this reason" 2 "Error" 3 "Not Available" ;
VAL_ 2364649214 HVESP3ChrgPwrLmtDTBattDiagCondtn 0 "No power limit for this reason" 1 "Power limited for this reason" 2 "Error" 3 "Not Available" ;
VAL_ 2364649214 HVESP3ChrgPwrLmtDTBattryCellVltg 0 "No power limit for this reason" 1 "Power limited for this reason" 2 "Error" 3 "Not Available" ;
VAL_ 2364649214 HVESP3ChrgPowerLimitDTBattryCurr 0 "No power limit for this reason" 1 "Power limited for this reason" 2 "Error" 3 "Not Available" ;
VAL_ 2364649214 HVESP3ChrgPwrLmtDTUndefinedCause 0 "No power limit for this reason" 1 "Power limited for this reason" 2 "Error" 3 "Not Available" ;
VAL_ 2364649726 HVESP3CellVoltageDiffStatus 0 "Cell-to-cell voltage differential is within acceptable limits" 1 "Cell-to-cell voltage differential exceeds acceptable limits but can be corrected via auto-balancing" 2 "Cell-to-cell voltage differential exceeds acceptable limits to a point where external maintenance balancing is required to restore battery performance" 3 "Cell-to-cell voltage differential exceeds acceptable limits to a point where external maintenance balancing cannot restore battery performance" 4 "Cell-to-cell voltage differential exceeds acceptable limits" 5 "Reserved" 14 "Error" 15 "Not Available" ;
VAL_ 2364649982 HVESP3CellTemperatureDiffStatus 0 "Cell-to-cell temperature differential is within acceptable limits" 1 "Cell-to-cell temperature differential exceeds acceptable limits" 2 "Error" 3 "Not Available" ;
VAL_ 2364651006 HVESP3HghVoltageBusPosContctStat 0 "Contactor Open" 1 "Contactor Closed" 2 "Error" 3 "Not Available" ;
VAL_ 2364651006 HVESP3HghVoltageBusNegContctStat 0 "Contactor Open" 1 "Contactor Closed" 2 "Error" 3 "Not Available" ;
VAL_ 2364651006 HVESP3HghVltgBusDiscnnctFrwrng 0 "Disconnect not pending" 1 "Disconnect imminent due to battery pack voltage approaching minimum acceptable level" 2 "Disconnect imminent due to battery pack voltage approaching maximum acceptable level" 3 "Disconnect imminent due to module voltage approaching minimum acceptable level" 4 "Disconnect imminent due to module voltage approaching maximum acceptable level" 5 "Disconnect imminent due to cell voltage approaching minimum acceptable level" 6 "Disconnect imminent due to cell voltage approaching maximum acceptable level" 7 "Disconnect imminent due to battery pack current approaching maximum acceptable level" 8 "Reserved" 13 "Disconnect imminent" 14 "Error" 15 "Not Available" ;
VAL_ 2364651006 HVESP3HghVltgBusPreChrgRelyStat 0 "Relay Open" 1 "Relay Closed" 2 "Error" 3 "Not Available" ;
VAL_ 2364651006 HVESP3CenterOfPackContactorState 0 "Contactor Open" 1 "Contactor Closed" 2 "Error" 3 "Not Available" ;
VAL_ 2364651006 HVESP3HiVltgBusActIsoltnTestStat 0 "No test requested / No test in process" 1 "Test requested but not yet in process" 2 "Test in process" 3 "Test complete - isolation acceptable" 4 "Test complete - isolation marginal" 5 "Test complete - isolation fault" 6 "Reserved" 14 "Error" 15 "Not available" ;
VAL_ 2364651006 HVESP3HiVltgBusPassIsoltnTestSt 0 "No test requested / No test in process" 1 "Test requested but not yet in process" 2 "Test in process" 3 "Test complete - isolation acceptable" 4 "Test complete - isolation marginal" 5 "Test complete - isolation fault" 6 "Reserved" 14 "Error" 15 "Not available" ;
VAL_ 2364651006 HVESP3HVILStatus 0 "HVIL Closed" 1 "HVIL Open" 2 "Error" 3 "Not Available" ;
VAL_ 2364651006 HVESP3InertiaSwitchStatus 0 "No impact sensed" 1 "Impact sensed" 2 "Error" 3 "Not Available" ;
VAL_ 2364651006 HVESP3StateOfChargeStatus 0 "SOC level is acceptable" 1 "SOC is approaching its recommended lower limit" 2 "SOC is at its recommended lower limit" 3 "SOC is below its recommended lower limit" 4 "SOC is approaching its recommended upper limit" 5 "SOC is at its recommended upper limit" 6 "SOC is above its recommended upper limit" 7 "Reserved" 14 "Error" 15 "Not  Available" ;
VAL_ 2364651006 HVESP3CellBalanceStatus 0 "Cells are balanced" 1 "Cells are unbalanced" 2 "Error" 3 "Not Available" ;
VAL_ 2364651006 HVESP3CellBalancingActive 0 "Cell balancing is not active" 1 "Cell balancing is active" 2 "Error" 3 "Not Available" ;
VAL_ 2364651006 HVESP3InternalChargerStatus 0 "Charging off" 1 "Charging on" 2 "Error" 3 "Not Available" ;
VAL_ 2364651006 HVESP3HghVoltageBusConnectnStat 0 "Disconnected" 1 "Connected" 2 "Connection in Process" 3 "Disconnection in Process" 4 "Disconnected - Precharge Failed" 5 "Reserved" 14 "Error" 15 "Not Available" ;
VAL_ 2364651006 HVESP3OperationalStatus 0 "Initialization in process" 1 "Initialization Complete" 2 "Operational" 3 "Normal Power-Down in Process" 4 "Emergency Power-Down In Process" 5 "Disabled by external command" 6 "Disabled by internal decision of HVES controller" 7 "Reserved" 14 "Error" 15 "Not Available" ;
VAL_ 2364651518 HVESP3Module1OperationalStatus 0 "Not Operational" 1 "Operational" 2 "Error" 3 "Not Available" ;
VAL_ 2364651518 HVESP3Module2OperationalStatus 0 "Not Operational" 1 "Operational" 2 "Error" 3 "Not Available" ;
VAL_ 2364651518 HVESP3Module3OperationalStatus 0 "Not Operational" 1 "Operational" 2 "Error" 3 "Not Available" ;
VAL_ 2364651518 HVESP3Module4OperationalStatus 0 "Not Operational" 1 "Operational" 2 "Error" 3 "Not Available" ;
VAL_ 2364651518 HVESP3Module5OperationalStatus 0 "Not Operational" 1 "Operational" 2 "Error" 3 "Not Available" ;
VAL_ 2364651518 HVESP3Module6OperationalStatus 0 "Not Operational" 1 "Operational" 2 "Error" 3 "Not Available" ;
VAL_ 2364651518 HVESP3Module7OperationalStatus 0 "Not Operational" 1 "Operational" 2 "Error" 3 "Not Available" ;
VAL_ 2364651518 HVESP3Module8OperationalStatus 0 "Not Operational" 1 "Operational" 2 "Error" 3 "Not Available" ;
VAL_ 2364651518 HVESP3Module9OperationalStatus 0 "Not Operational" 1 "Operational" 2 "Error" 3 "Not Available" ;
VAL_ 2364651518 HVESP3Module10OperationalStatus 0 "Not Operational" 1 "Operational" 2 "Error" 3 "Not Available" ;
VAL_ 2364651518 HVESP3Module11OperationalStatus 0 "Not Operational" 1 "Operational" 2 "Error" 3 "Not Available" ;
VAL_ 2364651518 HVESP3Module12OperationalStatus 0 "Not Operational" 1 "Operational" 2 "Error" 3 "Not Available" ;
VAL_ 2364651518 HVESP3Module13OperationalStatus 0 "Not Operational" 1 "Operational" 2 "Error" 3 "Not Available" ;
VAL_ 2364651518 HVESP3Module14OperationalStatus 0 "Not Operational" 1 "Operational" 2 "Error" 3 "Not Available" ;
VAL_ 2364651518 HVESP3Module15OperationalStatus 0 "Not Operational" 1 "Operational" 2 "Error" 3 "Not Available" ;
VAL_ 2364651518 HVESP3Module16OperationalStatus 0 "Not Operational" 1 "Operational" 2 "Error" 3 "Not Available" ;
VAL_ 2364651774 HVESP3ThermalMangmntSysHtrStat 0 "Heater Off" 1 "Heater On" 2 "Error" 3 "Not Available" ;
VAL_ 2364651774 HVESP3ThermalMangmntSysHVILStat 0 "HVIL Closed" 1 "HVIL Open" 2 "Error" 3 "Not Available" ;
VAL_ 2364651774 HVESP3ThermalMangmntSystemMode 0 "Off" 1 "Circulating" 2 "Cooling" 3 "Heating" 4 "Drying" 5 "Reserved" 14 "Faulted" 15 "Not Available" ;
VAL_ 2364653054 HVESP4DisChrgPowerLmtDTStateChrg 0 "No power limit for this reason" 1 "Power limited for this reason" 2 "Error" 3 "Not Available" ;
VAL_ 2364653054 HVESP4DisChrgPwrLmtDTBattryTemp 0 "No power limit for this reason" 1 "Power limited for this reason" 2 "Error" 3 "Not Available" ;
VAL_ 2364653054 HVESP4DisChrgPwrLmtDTBattDgCond 0 "No power limit for this reason" 1 "Power limited for this reason" 2 "Error" 3 "Not Available" ;
VAL_ 2364653054 HVESP4DisChrgPwrLmtDTBattCellV 0 "No power limit for this reason" 1 "Power limited for this reason" 2 "Error" 3 "Not Available" ;
VAL_ 2364653054 HVESP4DisChrgPwrLmtDTBattryCurr 0 "No power limit for this reason" 1 "Power limited for this reason" 2 "Error" 3 "Not Available" ;
VAL_ 2364653054 HVESP4DisChrgPwrLmtDTUndefCause 0 "No power limit for this reason" 1 "Power limited for this reason" 2 "Error" 3 "Not Available" ;
VAL_ 2364653054 HVESP4ChrgPowerLimitDTStateChrg 0 "No power limit for this reason" 1 "Power limited for this reason" 2 "Error" 3 "Not Available" ;
VAL_ 2364653054 HVESP4ChrgPwrLmtDTBattryTemp 0 "No power limit for this reason" 1 "Power limited for this reason" 2 "Error" 3 "Not Available" ;
VAL_ 2364653054 HVESP4ChrgPwrLmtDTBattDiagCondtn 0 "No power limit for this reason" 1 "Power limited for this reason" 2 "Error" 3 "Not Available" ;
VAL_ 2364653054 HVESP4ChrgPwrLmtDTBattryCellVltg 0 "No power limit for this reason" 1 "Power limited for this reason" 2 "Error" 3 "Not Available" ;
VAL_ 2364653054 HVESP4ChrgPowerLimitDTBattryCurr 0 "No power limit for this reason" 1 "Power limited for this reason" 2 "Error" 3 "Not Available" ;
VAL_ 2364653054 HVESP4ChrgPwrLmtDTUndefinedCause 0 "No power limit for this reason" 1 "Power limited for this reason" 2 "Error" 3 "Not Available" ;
VAL_ 2364653566 HVESP4CellVoltageDiffStatus 0 "Cell-to-cell voltage differential is within acceptable limits" 1 "Cell-to-cell voltage differential exceeds acceptable limits but can be corrected via auto-balancing" 2 "Cell-to-cell voltage differential exceeds acceptable limits to a point where external maintenance balancing is required to restore battery performance" 3 "Cell-to-cell voltage differential exceeds acceptable limits to a point where external maintenance balancing cannot restore battery performance" 4 "Cell-to-cell voltage differential exceeds acceptable limits" 5 "Reserved" 14 "Error" 15 "Not Available" ;
VAL_ 2364653822 HVESP4CellTemperatureDiffStatus 0 "Cell-to-cell temperature differential is within acceptable limits" 1 "Cell-to-cell temperature differential exceeds acceptable limits" 2 "Error" 3 "Not Available" ;
VAL_ 2364654846 HVESP4HghVoltageBusPosContctStat 0 "Contactor Open" 1 "Contactor Closed" 2 "Error" 3 "Not Available" ;
VAL_ 2364654846 HVESP4HghVoltageBusNegContctStat 0 "Contactor Open" 1 "Contactor Closed" 2 "Error" 3 "Not Available" ;
VAL_ 2364654846 HVESP4HghVltgBusDiscnnctFrwrng 0 "Disconnect not pending" 1 "Disconnect imminent due to battery pack voltage approaching minimum acceptable level" 2 "Disconnect imminent due to battery pack voltage approaching maximum acceptable level" 3 "Disconnect imminent due to module voltage approaching minimum acceptable level" 4 "Disconnect imminent due to module voltage approaching maximum acceptable level" 5 "Disconnect imminent due to cell voltage approaching minimum acceptable level" 6 "Disconnect imminent due to cell voltage approaching maximum acceptable level" 7 "Disconnect imminent due to battery pack current approaching maximum acceptable level" 8 "Reserved" 13 "Disconnect imminent" 14 "Error" 15 "Not Available" ;
VAL_ 2364654846 HVESP4HghVltgBusPreChrgRelyStat 0 "Relay Open" 1 "Relay Closed" 2 "Error" 3 "Not Available" ;
VAL_ 2364654846 HVESP4CenterOfPackContactorState 0 "Contactor Open" 1 "Contactor Closed" 2 "Error" 3 "Not Available" ;
VAL_ 2364654846 HVESP4HiVltgBusActIsoltnTestStat 0 "No test requested / No test in process" 1 "Test requested but not yet in process" 2 "Test in process" 3 "Test complete - isolation acceptable" 4 "Test complete - isolation marginal" 5 "Test complete - isolation fault" 6 "Reserved" 14 "Error" 15 "Not available" ;
VAL_ 2364654846 HVESP4HiVltgBusPassIsoltnTestSt 0 "No test requested / No test in process" 1 "Test requested but not yet in process" 2 "Test in process" 3 "Test complete - isolation acceptable" 4 "Test complete - isolation marginal" 5 "Test complete - isolation fault" 6 "Reserved" 14 "Error" 15 "Not available" ;
VAL_ 2364654846 HVESP4HVILStatus 0 "HVIL Closed" 1 "HVIL Open" 2 "Error" 3 "Not Available" ;
VAL_ 2364654846 HVESP4InertiaSwitchStatus 0 "No impact sensed" 1 "Impact sensed" 2 "Error" 3 "Not Available" ;
VAL_ 2364654846 HVESP4StateOfChargeStatus 0 "SOC level is acceptable" 1 "SOC is approaching its recommended lower limit" 2 "SOC is at its recommended lower limit" 3 "SOC is below its recommended lower limit" 4 "SOC is approaching its recommended upper limit" 5 "SOC is at its recommended upper limit" 6 "SOC is above its recommended upper limit" 7 "Reserved" 14 "Error" 15 "Not  Available" ;
VAL_ 2364654846 HVESP4CellBalanceStatus 0 "Cells are balanced" 1 "Cells are unbalanced" 2 "Error" 3 "Not Available" ;
VAL_ 2364654846 HVESP4CellBalancingActive 0 "Cell balancing is not active" 1 "Cell balancing is active" 2 "Error" 3 "Not Available" ;
VAL_ 2364654846 HVESP4InternalChargerStatus 0 "Charging off" 1 "Charging on" 2 "Error" 3 "Not Available" ;
VAL_ 2364654846 HVESP4HghVoltageBusConnectnStat 0 "Disconnected" 1 "Connected" 2 "Connection in Process" 3 "Disconnection in Process" 4 "Disconnected - Precharge Failed" 5 "Reserved" 14 "Error" 15 "Not Available" ;
VAL_ 2364654846 HVESP4OperationalStatus 0 "Initialization in Process" 1 "Initialization Complete, awaiting Operation Consent" 2 "Operational" 3 "Normal Power-Down in Process" 4 "Emergency Power-Down In Process" 5 "Disabled by external command" 6 "Disabled by internal decision of HVES controller" 7 "Reserved" 14 "Error" 15 "Not Available" ;
VAL_ 2364655358 HVESP4Module1OperationalStatus 0 "Not Operational" 1 "Operational" 2 "Error" 3 "Not Available" ;
VAL_ 2364655358 HVESP4Module2OperationalStatus 0 "Not Operational" 1 "Operational" 2 "Error" 3 "Not Available" ;
VAL_ 2364655358 HVESP4Module3OperationalStatus 0 "Not Operational" 1 "Operational" 2 "Error" 3 "Not Available" ;
VAL_ 2364655358 HVESP4Module4OperationalStatus 0 "Not Operational" 1 "Operational" 2 "Error" 3 "Not Available" ;
VAL_ 2364655358 HVESP4Module5OperationalStatus 0 "Not Operational" 1 "Operational" 2 "Error" 3 "Not Available" ;
VAL_ 2364655358 HVESP4Module6OperationalStatus 0 "Not Operational" 1 "Operational" 2 "Error" 3 "Not Available" ;
VAL_ 2364655358 HVESP4Module7OperationalStatus 0 "Not Operational" 1 "Operational" 2 "Error" 3 "Not Available" ;
VAL_ 2364655358 HVESP4Module8OperationalStatus 0 "Not Operational" 1 "Operational" 2 "Error" 3 "Not Available" ;
VAL_ 2364655358 HVESP4Module9OperationalStatus 0 "Not Operational" 1 "Operational" 2 "Error" 3 "Not Available" ;
VAL_ 2364655358 HVESP4Module10OperationalStatus 0 "Not Operational" 1 "Operational" 2 "Error" 3 "Not Available" ;
VAL_ 2364655358 HVESP4Module11OperationalStatus 0 "Not Operational" 1 "Operational" 2 "Error" 3 "Not Available" ;
VAL_ 2364655358 HVESP4Module12OperationalStatus 0 "Not Operational" 1 "Operational" 2 "Error" 3 "Not Available" ;
VAL_ 2364655358 HVESP4Module13OperationalStatus 0 "Not Operational" 1 "Operational" 2 "Error" 3 "Not Available" ;
VAL_ 2364655358 HVESP4Module14OperationalStatus 0 "Not Operational" 1 "Operational" 2 "Error" 3 "Not Available" ;
VAL_ 2364655358 HVESP4Module15OperationalStatus 0 "Not Operational" 1 "Operational" 2 "Error" 3 "Not Available" ;
VAL_ 2364655358 HVESP4Module16OperationalStatus 0 "Not Operational" 1 "Operational" 2 "Error" 3 "Not Available" ;
VAL_ 2364655614 HVESP4ThermalMangmntSysHtrStat 0 "Heater Off" 1 "Heater On" 2 "Error" 3 "Not Available" ;
VAL_ 2364655614 HVESP4ThermalMangmntSysHVILStat 0 "HVIL Closed" 1 "HVIL Open" 2 "Error" 3 "Not Available" ;
VAL_ 2364655614 HVESP4ThermalMangmntSystemMode 0 "Off" 1 "Circulating" 2 "Cooling" 3 "Heating" 4 "Drying" 5 "Reserved" 14 "Faulted" 15 "Not Available" ;
VAL_ 2364656894 HVESP5DisChrgPowerLmtDTStateChrg 0 "No power limit for this reason" 1 "Power limited for this reason" 2 "Error" 3 "Not Available" ;
VAL_ 2364656894 HVESP5DisChrgPwrLmtDTBattryTemp 0 "No power limit for this reason" 1 "Power limited for this reason" 2 "Error" 3 "Not Available" ;
VAL_ 2364656894 HVESP5DisChrgPwrLmtDTBattDgCond 0 "No power limit for this reason" 1 "Power limited for this reason" 2 "Error" 3 "Not Available" ;
VAL_ 2364656894 HVESP5DisChrgPwrLmtDTBattCellV 0 "No power limit for this reason" 1 "Power limited for this reason" 2 "Error" 3 "Not Available" ;
VAL_ 2364656894 HVESP5DisChrgPwrLmtDTBattryCurr 0 "No power limit for this reason" 1 "Power limited for this reason" 2 "Error" 3 "Not Available" ;
VAL_ 2364656894 HVESP5DisChrgPwrLmtDTUndefCause 0 "No power limit for this reason" 1 "Power limited for this reason" 2 "Error" 3 "Not Available" ;
VAL_ 2364656894 HVESP5ChrgPowerLimitDTStateChrg 0 "No power limit for this reason" 1 "Power limited for this reason" 2 "Error" 3 "Not Available" ;
VAL_ 2364656894 HVESP5ChrgPwrLmtDTBattryTemp 0 "No power limit for this reason" 1 "Power limited for this reason" 2 "Error" 3 "Not Available" ;
VAL_ 2364656894 HVESP5ChrgPwrLmtDTBattDiagCondtn 0 "No power limit for this reason" 1 "Power limited for this reason" 2 "Error" 3 "Not Available" ;
VAL_ 2364656894 HVESP5ChrgPwrLmtDTBattryCellVltg 0 "No power limit for this reason" 1 "Power limited for this reason" 2 "Error" 3 "Not Available" ;
VAL_ 2364656894 HVESP5ChrgPowerLimitDTBattryCurr 0 "No power limit for this reason" 1 "Power limited for this reason" 2 "Error" 3 "Not Available" ;
VAL_ 2364656894 HVESP5ChrgPwrLmtDTUndefinedCause 0 "No power limit for this reason" 1 "Power limited for this reason" 2 "Error" 3 "Not Available" ;
VAL_ 2364657406 HVESP5CellVoltageDiffStatus 0 "Cell-to-cell voltage differential is within acceptable limits" 1 "Cell-to-cell voltage differential exceeds acceptable limits but can be corrected via auto-balancing" 2 "Cell-to-cell voltage differential exceeds acceptable limits to a point where external maintenance balancing is required to restore battery performance" 3 "Cell-to-cell voltage differential exceeds acceptable limits to a point where external maintenance balancing cannot restore battery performance" 4 "Cell-to-cell voltage differential exceeds acceptable limits" 5 "Reserved" 14 "Error" 15 "Not Available" ;
VAL_ 2364657662 HVESP5CellTemperatureDiffStatus 0 "Cell-to-cell temperature differential is within acceptable limits" 1 "Cell-to-cell temperature differential exceeds acceptable limits" 2 "Error" 3 "Not Available" ;
VAL_ 2364658686 HVESP5HghVoltageBusPosContctStat 0 "Contactor Open" 1 "Contactor Closed" 2 "Error" 3 "Not Available" ;
VAL_ 2364658686 HVESP5HghVoltageBusNegContctStat 0 "Contactor Open" 1 "Contactor Closed" 2 "Error" 3 "Not Available" ;
VAL_ 2364658686 HVESP5HghVltgBusDiscnnctFrwrng 0 "Disconnect not pending" 1 "Disconnect imminent due to battery pack voltage approaching minimum acceptable level" 2 "Disconnect imminent due to battery pack voltage approaching maximum acceptable level" 3 "Disconnect imminent due to module voltage approaching minimum acceptable level" 4 "Disconnect imminent due to module voltage approaching maximum acceptable level" 5 "Disconnect imminent due to cell voltage approaching minimum acceptable level" 6 "Disconnect imminent due to cell voltage approaching maximum acceptable level" 7 "Disconnect imminent due to battery pack current approaching maximum acceptable level" 8 "Reserved" 13 "Disconnect imminent" 14 "Error" 15 "Not Available" ;
VAL_ 2364658686 HVESP5HghVltgBusPreChrgRelyStat 0 "Relay Open" 1 "Relay Closed" 2 "Error" 3 "Not Available" ;
VAL_ 2364658686 HVESP5CenterOfPackContactorState 0 "Contactor Open" 1 "Contactor Closed" 2 "Error" 3 "Not Available" ;
VAL_ 2364658686 HVESP5HiVltgBusActIsoltnTestStat 0 "No test requested / No test in process" 1 "Test requested but not yet in process" 2 "Test in process" 3 "Test complete - isolation acceptable" 4 "Test complete - isolation marginal" 5 "Test complete - isolation fault" 6 "Reserved" 14 "Error" 15 "Not available" ;
VAL_ 2364658686 HVESP5HiVltgBusPassIsoltnTestSt 0 "No test requested / No test in process" 1 "Test requested but not yet in process" 2 "Test in process" 3 "Test complete - isolation acceptable" 4 "Test complete - isolation marginal" 5 "Test complete - isolation fault" 6 "Reserved" 14 "Error" 15 "Not available" ;
VAL_ 2364658686 HVESP5HVILStatus 0 "HVIL Closed" 1 "HVIL Open" 2 "Error" 3 "Not Available" ;
VAL_ 2364658686 HVESP5InertiaSwitchStatus 0 "No impact sensed" 1 "Impact sensed" 2 "Error" 3 "Not Available" ;
VAL_ 2364658686 HVESP5StateOfChargeStatus 0 "SOC level is acceptable" 1 "SOC is approaching its recommended lower limit" 2 "SOC is at its recommended lower limit" 3 "SOC is below its recommended lower limit" 4 "SOC is approaching its recommended upper limit" 5 "SOC is at its recommended upper limit" 6 "SOC is above its recommended upper limit" 7 "Reserved" 14 "Error" 15 "Not  Available" ;
VAL_ 2364658686 HVESP5CellBalanceStatus 0 "Cells are balanced" 1 "Cells are unbalanced" 2 "Error" 3 "Not Available" ;
VAL_ 2364658686 HVESP5CellBalancingActive 0 "Cell balancing is not active" 1 "Cell balancing is active" 2 "Error" 3 "Not Available" ;
VAL_ 2364658686 HVESP5InternalChargerStatus 0 "Charging off" 1 "Charging on" 2 "Error" 3 "Not Available" ;
VAL_ 2364658686 HVESP5HghVoltageBusConnectnStat 0 "Disconnected" 1 "Connected" 2 "Connection in Process" 3 "Disconnection in Process" 4 "Disconnected - Precharge Failed" 5 "Reserved" 14 "Error" 15 "Not Available" ;
VAL_ 2364658686 HVESP5OperationalStatus 0 "Initialization in Process" 1 "Initialization Complete, awaiting Operation Consent" 2 "Operational" 3 "Normal Power-Down in Process" 4 "Emergency Power-Down In Process" 5 "Disabled by external command" 6 "Disabled by internal decision of HVES controller" 7 "Reserved" 14 "Error" 15 "Not Available" ;
VAL_ 2364659198 HVESP5Module1OperationalStatus 0 "Not Operational" 1 "Operational" 2 "Error" 3 "Not Available" ;
VAL_ 2364659198 HVESP5Module2OperationalStatus 0 "Not Operational" 1 "Operational" 2 "Error" 3 "Not Available" ;
VAL_ 2364659198 HVESP5Module3OperationalStatus 0 "Not Operational" 1 "Operational" 2 "Error" 3 "Not Available" ;
VAL_ 2364659198 HVESP5Module4OperationalStatus 0 "Not Operational" 1 "Operational" 2 "Error" 3 "Not Available" ;
VAL_ 2364659198 HVESP5Module5OperationalStatus 0 "Not Operational" 1 "Operational" 2 "Error" 3 "Not Available" ;
VAL_ 2364659198 HVESP5Module6OperationalStatus 0 "Not Operational" 1 "Operational" 2 "Error" 3 "Not Available" ;
VAL_ 2364659198 HVESP5Module7OperationalStatus 0 "Not Operational" 1 "Operational" 2 "Error" 3 "Not Available" ;
VAL_ 2364659198 HVESP5Module8OperationalStatus 0 "Not Operational" 1 "Operational" 2 "Error" 3 "Not Available" ;
VAL_ 2364659198 HVESP5Module9OperationalStatus 0 "Not Operational" 1 "Operational" 2 "Error" 3 "Not Available" ;
VAL_ 2364659198 HVESP5Module10OperationalStatus 0 "Not Operational" 1 "Operational" 2 "Error" 3 "Not Available" ;
VAL_ 2364659198 HVESP5Module11OperationalStatus 0 "Not Operational" 1 "Operational" 2 "Error" 3 "Not Available" ;
VAL_ 2364659198 HVESP5Module12OperationalStatus 0 "Not Operational" 1 "Operational" 2 "Error" 3 "Not Available" ;
VAL_ 2364659198 HVESP5Module13OperationalStatus 0 "Not Operational" 1 "Operational" 2 "Error" 3 "Not Available" ;
VAL_ 2364659198 HVESP5Module14OperationalStatus 0 "Not Operational" 1 "Operational" 2 "Error" 3 "Not Available" ;
VAL_ 2364659198 HVESP5Module15OperationalStatus 0 "Not Operational" 1 "Operational" 2 "Error" 3 "Not Available" ;
VAL_ 2364659198 HVESP5Module16OperationalStatus 0 "Not Operational" 1 "Operational" 2 "Error" 3 "Not Available" ;
VAL_ 2364659454 HVESP5ThermalMangmntSysHtrStat 0 "Heater Off" 1 "Heater On" 2 "Error" 3 "Not Available" ;
VAL_ 2364659454 HVESP5ThermalMangmntSysHVILStat 0 "HVIL Closed" 1 "HVIL Open" 2 "Error" 3 "Not Available" ;
VAL_ 2364659454 HVESP5ThermalMangmntSystemMode 0 "Off" 1 "Circulating" 2 "Cooling" 3 "Heating" 4 "Drying" 5 "Reserved" 14 "Faulted" 15 "Not Available" ;
VAL_ 2364660734 HVESP6DisChrgPowerLmtDTStateChrg 0 "No power limit for this reason" 1 "Power limited for this reason" 2 "Error" 3 "Not Available" ;
VAL_ 2364660734 HVESP6DisChrgPwrLmtDTBattryTemp 0 "No power limit for this reason" 1 "Power limited for this reason" 2 "Error" 3 "Not Available" ;
VAL_ 2364660734 HVESP6DisChrgPwrLmtDTBattDgCond 0 "No power limit for this reason" 1 "Power limited for this reason" 2 "Error" 3 "Not Available" ;
VAL_ 2364660734 HVESP6DisChrgPwrLmtDTBattCellV 0 "No power limit for this reason" 1 "Power limited for this reason" 2 "Error" 3 "Not Available" ;
VAL_ 2364660734 HVESP6DisChrgPwrLmtDTBattryCurr 0 "No power limit for this reason" 1 "Power limited for this reason" 2 "Error" 3 "Not Available" ;
VAL_ 2364660734 HVESP6DisChrgPwrLmtDTUndefCause 0 "No power limit for this reason" 1 "Power limited for this reason" 2 "Error" 3 "Not Available" ;
VAL_ 2364660734 HVESP6ChrgPowerLimitDTStateChrg 0 "No power limit for this reason" 1 "Power limited for this reason" 2 "Error" 3 "Not Available" ;
VAL_ 2364660734 HVESP6ChrgPwrLmtDTBattryTemp 0 "No power limit for this reason" 1 "Power limited for this reason" 2 "Error" 3 "Not Available" ;
VAL_ 2364660734 HVESP6ChrgPwrLmtDTBattDiagCondtn 0 "No power limit for this reason" 1 "Power limited for this reason" 2 "Error" 3 "Not Available" ;
VAL_ 2364660734 HVESP6ChrgPwrLmtDTBattryCellVltg 0 "No power limit for this reason" 1 "Power limited for this reason" 2 "Error" 3 "Not Available" ;
VAL_ 2364660734 HVESP6ChrgPowerLimitDTBattryCurr 0 "No power limit for this reason" 1 "Power limited for this reason" 2 "Error" 3 "Not Available" ;
VAL_ 2364660734 HVESP6ChrgPwrLmtDTUndefinedCause 0 "No power limit for this reason" 1 "Power limited for this reason" 2 "Error" 3 "Not Available" ;
VAL_ 2364661246 HVESP6CellVoltageDiffStatus 0 "Cell-to-cell voltage differential is within acceptable limits" 1 "Cell-to-cell voltage differential exceeds acceptable limits but can be corrected via auto-balancing" 2 "Cell-to-cell voltage differential exceeds acceptable limits to a point where external maintenance balancing is required to restore battery performance" 3 "Cell-to-cell voltage differential exceeds acceptable limits to a point where external maintenance balancing cannot restore battery performance" 4 "Cell-to-cell voltage differential exceeds acceptable limits" 5 "Reserved" 14 "Error" 15 "Not Available" ;
VAL_ 2364661502 HVESP6CellTemperatureDiffStatus 0 "Cell-to-cell temperature differential is within acceptable limits" 1 "Cell-to-cell temperature differential exceeds acceptable limits" 2 "Error" 3 "Not Available" ;
VAL_ 2364662526 HVESP6HghVoltageBusPosContctStat 0 "Contactor Open" 1 "Contactor Closed" 2 "Error" 3 "Not Available" ;
VAL_ 2364662526 HVESP6HghVoltageBusNegContctStat 0 "Contactor Open" 1 "Contactor Closed" 2 "Error" 3 "Not Available" ;
VAL_ 2364662526 HVESP6HghVltgBusDiscnnctFrwrng 0 "Disconnect not pending" 1 "Disconnect imminent due to battery pack voltage approaching minimum acceptable level" 2 "Disconnect imminent due to battery pack voltage approaching maximum acceptable level" 3 "Disconnect imminent due to module voltage approaching minimum acceptable level" 4 "Disconnect imminent due to module voltage approaching maximum acceptable level" 5 "Disconnect imminent due to cell voltage approaching minimum acceptable level" 6 "Disconnect imminent due to cell voltage approaching maximum acceptable level" 7 "Disconnect imminent due to battery pack current approaching maximum acceptable level" 8 "Reserved" 13 "Disconnect imminent" 14 "Error" 15 "Not Available" ;
VAL_ 2364662526 HVESP6HghVltgBusPreChrgRelyStat 0 "Relay Open" 1 "Relay Closed" 2 "Error" 3 "Not Available" ;
VAL_ 2364662526 HVESP6CenterOfPackContactorState 0 "Contactor Open" 1 "Contactor Closed" 2 "Error" 3 "Not Available" ;
VAL_ 2364662526 HVESP6HiVltgBusActIsoltnTestStat 0 "No test requested / No test in process" 1 "Test requested but not yet in process" 2 "Test in process" 3 "Test complete - isolation acceptable" 4 "Test complete - isolation marginal" 5 "Test complete - isolation fault" 6 "Reserved" 14 "Error" 15 "Not available" ;
VAL_ 2364662526 HVESP6HiVltgBusPassIsoltnTestSt 0 "No test requested / No test in process" 1 "Test requested but not yet in process" 2 "Test in process" 3 "Test complete - isolation acceptable" 4 "Test complete - isolation marginal" 5 "Test complete - isolation fault" 6 "Reserved" 14 "Error" 15 "Not available" ;
VAL_ 2364662526 HVESP6HVILStatus 0 "HVIL Closed" 1 "HVIL Open" 2 "Error" 3 "Not Available" ;
VAL_ 2364662526 HVESP6InertiaSwitchStatus 0 "No impact sensed" 1 "Impact sensed" 2 "Error" 3 "Not Available" ;
VAL_ 2364662526 HVESP6StateOfChargeStatus 0 "SOC level is acceptable" 1 "SOC is approaching its recommended lower limit" 2 "SOC is at its recommended lower limit" 3 "SOC is below its recommended lower limit" 4 "SOC is approaching its recommended upper limit" 5 "SOC is at its recommended upper limit" 6 "SOC is above its recommended upper limit" 7 "Reserved" 14 "Error" 15 "Not  Available" ;
VAL_ 2364662526 HVESP6CellBalanceStatus 0 "Cells are balanced" 1 "Cells are unbalanced" 2 "Error" 3 "Not Available" ;
VAL_ 2364662526 HVESP6CellBalancingActive 0 "Cell balancing is not active" 1 "Cell balancing is active" 2 "Error" 3 "Not Available" ;
VAL_ 2364662526 HVESP6InternalChargerStatus 0 "Charging off" 1 "Charging on" 2 "Error" 3 "Not Available" ;
VAL_ 2364662526 HVESP6HghVoltageBusConnectnStat 0 "Disconnected" 1 "Connected" 2 "Connection in Process" 3 "Disconnection in Process" 4 "Disconnected - Precharge Failed" 5 "Reserved" 14 "Error" 15 "Not Available" ;
VAL_ 2364662526 HVESP6OperationalStatus 0 "Initialization in Process" 1 "Initialization Complete, awaiting Operation Consent" 2 "Operational" 3 "Normal Power-Down in Process" 4 "Emergency Power-Down In Process" 5 "Disabled by external command" 6 "Disabled by internal decision of HVES controller" 7 "Reserved" 14 "Error" 15 "Not Available" ;
VAL_ 2364663038 HVESP6Module3OperationalStatus 0 "Not Operational" 1 "Operational" 2 "Error" 3 "Not Available" ;
VAL_ 2364663038 HVESP6Module4OperationalStatus 0 "Not Operational" 1 "Operational" 2 "Error" 3 "Not Available" ;
VAL_ 2364663038 HVESP6Module5OperationalStatus 0 "Not Operational" 1 "Operational" 2 "Error" 3 "Not Available" ;
VAL_ 2364663038 HVESP6Module6OperationalStatus 0 "Not Operational" 1 "Operational" 2 "Error" 3 "Not Available" ;
VAL_ 2364663038 HVESP6Module7OperationalStatus 0 "Not Operational" 1 "Operational" 2 "Error" 3 "Not Available" ;
VAL_ 2364663038 HVESP6Module8OperationalStatus 0 "Not Operational" 1 "Operational" 2 "Error" 3 "Not Available" ;
VAL_ 2364663038 HVESP6Module9OperationalStatus 0 "Not Operational" 1 "Operational" 2 "Error" 3 "Not Available" ;
VAL_ 2364663038 HVESP6Module10OperationalStatus 0 "Not Operational" 1 "Operational" 2 "Error" 3 "Not Available" ;
VAL_ 2364663038 HVESP6Module11OperationalStatus 0 "Not Operational" 1 "Operational" 2 "Error" 3 "Not Available" ;
VAL_ 2364663038 HVESP6Module12OperationalStatus 0 "Not Operational" 1 "Operational" 2 "Error" 3 "Not Available" ;
VAL_ 2364663038 HVESP6Module13OperationalStatus 0 "Not Operational" 1 "Operational" 2 "Error" 3 "Not Available" ;
VAL_ 2364663038 HVESP6Module14OperationalStatus 0 "Not Operational" 1 "Operational" 2 "Error" 3 "Not Available" ;
VAL_ 2364663038 HVESP6Module15OperationalStatus 0 "Not Operational" 1 "Operational" 2 "Error" 3 "Not Available" ;
VAL_ 2364663038 HVESP6Module16OperationalStatus 0 "Not Operational" 1 "Operational" 2 "Error" 3 "Not Available" ;
VAL_ 2364663294 HVESP6ThermalMangmntSysHtrStat 0 "Heater Off" 1 "Heater On" 2 "Error" 3 "Not Available" ;
VAL_ 2364663294 HVESP6ThermalMangmntSysHVILStat 0 "HVIL Closed" 1 "HVIL Open" 2 "Error" 3 "Not Available" ;
VAL_ 2364663294 HVESP6ThermalMangmntSystemMode 0 "Off" 1 "Circulating" 2 "Cooling" 3 "Heating" 4 "Drying" 5 "Reserved" 14 "Faulted" 15 "Not Available" ;
VAL_ 2364664574 MtrGen3InvertCtrlLmtsOverrideMde 1 "Torque Limits Mode" 2 "Speed Limits Mode" 3 "DC Side Voltage Limits Mode" 4 "DC Side Current Limits Mode" 5 "DC Side Power Limits Mode" 6 "Mechanical Power Limits Mode" 7 "SAE Reserved" 14 "Error" 15 "Not Available" ;
VAL_ 2364664574 MotorGen3InvertCtrlSetpointMode 0 "Powered On" 1 "Waiting for Operational conditions" 2 "Standby" 3 "SAE Reserved" 4 "SAE Reserved" 5 "Manufacturer specific passive mode 1" 6 "Manufacturer specific passive mode 2" 7 "Torque Control Mode" 8 "Speed Control Mode" 9 "DC Side Voltage Mode" 10 "DC Side Current Mode" 11 "Mechanical Power Control Mode" 12 "DC Power Control Mode" 13 "DC Side Voltage Control Mode" 14 "SAE Reserved" 15 "SAE Reserved" 16 "SAE Reserved" 17 "SAE Reserved" 18 "Manufacturer specific active mode 1" 19 "Manufacturer specific active mode 2" 20 "Inverter active discharge mode" 21 "Inverter power down command" 22 "SAE Reserved" 23 "SAE Reserved" 24 "SAE Reserved" 25 "SAE Reserved" 26 "SAE Reserved" 27 "SAE Reserved" 28 "Manufacturer specific special mode 1" 29 "Manufacturer specific special mode 2" 30 "Error" 31 "Not Available" ;
VAL_ 2364664574 MotorGen3InverterHVILStatus 0 "HVIL Closed" 1 "HVIL Open" 2 "Error" 3 "Not Available" ;
VAL_ 2364666366 MtrGen4InvertCtrlLmtsOverrideMde 1 "Torque Limits Mode" 2 "Speed Limits Mode" 3 "DC Side Voltage Limits Mode" 4 "DC Side Current Limits Mode" 5 "DC Side Power Limits Mode" 6 "Mechanical Power Limits Mode" 7 "SAE Reserved" 14 "Error" 15 "Not Available" ;
VAL_ 2364666366 MotorGen4InvertCtrlSetpointMode 0 "Powered On" 1 "Waiting for Operational conditions" 2 "Standby" 3 "SAE Reserved" 4 "SAE Reserved" 5 "Manufacturer specific passive mode 1" 6 "Manufacturer specific passive mode 2" 7 "Torque Control Mode" 8 "Speed Control Mode" 9 "DC Side Voltage Mode" 10 "DC Side Current Mode" 11 "Mechanical Power Control Mode" 12 "DC Power Control Mode" 13 "DC Side Voltage Control Mode" 14 "SAE Reserved" 15 "SAE Reserved" 16 "SAE Reserved" 17 "SAE Reserved" 18 "Manufacturer specific active mode 1" 19 "Manufacturer specific active mode 2" 20 "Inverter active discharge mode" 21 "Inverter power down command" 22 "SAE Reserved" 23 "SAE Reserved" 24 "SAE Reserved" 25 "SAE Reserved" 26 "SAE Reserved" 27 "SAE Reserved" 28 "Manufacturer specific special mode 1" 29 "Manufacturer specific special mode 2" 30 "Error" 31 "Not Available" ;
VAL_ 2364666366 MotorGen4InverterHVILStatus 0 "HVIL Closed" 1 "HVIL Open" 2 "Error" 3 "Not Available" ;
VAL_ 2364668158 MtrGen5InvertCtrlLmtsOverrideMde 1 "Torque Limits Mode" 2 "Speed Limits Mode" 3 "DC Side Voltage Limits Mode" 4 "DC Side Current Limits Mode" 5 "DC Side Power Limits Mode" 6 "Mechanical Power Limits Mode" 7 "SAE Reserved" 14 "Error" 15 "Not Available" ;
VAL_ 2364668158 MotorGen5InvertCtrlSetpointMode 0 "Powered On" 1 "Waiting for Operational conditions" 2 "Standby" 3 "SAE Reserved" 4 "SAE Reserved" 5 "Manufacturer specific passive mode 1" 6 "Manufacturer specific passive mode 2" 7 "Torque Control Mode" 8 "Speed Control Mode" 9 "DC Side Voltage Mode" 10 "DC Side Current Mode" 11 "Mechanical Power Control Mode" 12 "DC Power Control Mode" 13 "DC Side Voltage Control Mode" 14 "SAE Reserved" 15 "SAE Reserved" 16 "SAE Reserved" 17 "SAE Reserved" 18 "Manufacturer specific active mode 1" 19 "Manufacturer specific active mode 2" 20 "Inverter active discharge mode" 21 "Inverter power down command" 22 "SAE Reserved" 23 "SAE Reserved" 24 "SAE Reserved" 25 "SAE Reserved" 26 "SAE Reserved" 27 "SAE Reserved" 28 "Manufacturer specific special mode 1" 29 "Manufacturer specific special mode 2" 30 "Error" 31 "Not Available" ;
VAL_ 2364668158 MotorGen5InverterHVILStatus 0 "HVIL Closed" 1 "HVIL Open" 2 "Error" 3 "Not Available" ;
VAL_ 2364669950 MtrGen6InvertCtrlLmtsOverrideMde 1 "Torque Limits Mode" 2 "Speed Limits Mode" 3 "DC Side Voltage Limits Mode" 4 "DC Side Current Limits Mode" 5 "DC Side Power Limits Mode" 6 "Mechanical Power Limits Mode" 7 "SAE Reserved" 14 "Error" 15 "Not Available" ;
VAL_ 2364669950 MotorGen6InvertCtrlSetpointMode 0 "Powered On" 1 "Waiting for Operational conditions" 2 "Standby" 3 "SAE Reserved" 4 "SAE Reserved" 5 "Manufacturer specific passive mode 1" 6 "Manufacturer specific passive mode 2" 7 "Torque Control Mode" 8 "Speed Control Mode" 9 "DC Side Voltage Mode" 10 "DC Side Current Mode" 11 "Mechanical Power Control Mode" 12 "DC Power Control Mode" 13 "DC Side Voltage Control Mode" 14 "SAE Reserved" 15 "SAE Reserved" 16 "SAE Reserved" 17 "SAE Reserved" 18 "Manufacturer specific active mode 1" 19 "Manufacturer specific active mode 2" 20 "Inverter active discharge mode" 21 "Inverter power down command" 22 "SAE Reserved" 23 "SAE Reserved" 24 "SAE Reserved" 25 "SAE Reserved" 26 "SAE Reserved" 27 "SAE Reserved" 28 "Manufacturer specific special mode 1" 29 "Manufacturer specific special mode 2" 30 "Error" 31 "Not Available" ;
VAL_ 2364669950 MotorGen6InverterHVILStatus 0 "HVIL Closed" 1 "HVIL Open" 2 "Error" 3 "Not Available" ;
VAL_ 2364671742 BlindSpotDetectionState 0 "system is not ready" 1 "system is temporarily not available" 2 "system is deactivated by driver / Inform only mode" 3 "system is ready and activated" 4 "driver overrides system" 5 "collision warning active with visual/audio cues" 6 "collision warning with additional system response" 7 "reserved" 8 "system performance and/or sensitivity limited" 9 "reserved for future use" 14 "error indication" 15 "not available / not installed" ;
VAL_ 2364671742 BlindSpotCollisionWarningLevel 0 "no warning" 1 "warning level 1" 2 "warning level 2" 3 "warning level 3" 4 "warning level 4" 5 "warning level 5" 6 "warning level 6" 7 "warning level 7" 8 "reserved" 15 "don't care / take no action" ;
VAL_ 2364671742 BlindSpotWarningRelvntObjDetctd 0 "No relevant object monitored" 1 "Single relevant object is being monitored" 2 "Multiple relevant objects are being monitored" 3 "Reserved" 5 "Relevant object(s) is not being detected reliably" 6 "Error" 7 "Not available / not installed" ;
VAL_ 2364671742 BendOffProbabltyMstImportntObj 0 "no indication for a bend-off maneuver of the object" 1 "low probability for a bend-off maneuver of the object" 2 "medium probability for a bend-off maneuver of the object" 3 "high probability for a bend-off maneuver of the object" 4 "highest probability for a bend-off maneuver of the object" 5 "monitored object is already in a bend-off maneuver" 6 "error indication" 7 "signal not available / not installed" ;
VAL_ 2364671742 BlindSpotDetctnLeftSideMonitored 0 "Not being monitored" 1 "Monitored" 2 "Error indication" 3 "Not available" ;
VAL_ 2364671742 BlindSpotDetctnRightSideMontrd 0 "Not being monitored" 1 "Monitored" 2 "Error indication" 3 "Not available" ;
VAL_ 2364671742 BlindSpotDetectionFrontMonitored 0 "Not being monitored" 1 "Monitored" 2 "Error indication" 3 "Not available" ;
VAL_ 2364671742 BlindSpotDetectionRearMonitored 0 "Not being monitored" 1 "Monitored" 2 "Error indication" 3 "Not available" ;
VAL_ 2364672254 MtrGen3InvertCtrlLmtsRqOverrdMde 0 "Limits not currently being requested in this PGN" 1 "Torque Limits Mode" 2 "Speed Limits Mode" 3 "DC Side Voltage Limits Mode" 4 "DC Side Current Limits Mode" 5 "DC Side Power Limits Mode" 6 "Mechanical Power Limits Mode" 7 "SAE Reserved" 14 "Error" 15 "Not Requests / Take No Action" ;
VAL_ 2364672254 MtrGen3InvertCtrlSetpointMdeRq 0 "Power On" 1 "SAE Reserved" 2 "Standby" 3 "SAE Reserved" 4 "SAE Reserved" 5 "Manufacturer specific passive mode 1" 6 "Manufacturer specific passive mode 2" 7 "Enable Torque Control Mode" 8 "Enable Speed Control Mode" 9 "Enable DC Side Voltage Mode" 10 "Enable DC Side Current Mode" 11 "Enable DC Power Control Mode" 12 "Enable Mechanical Power Control Mode" 13 "SAE Reserved" 14 "SAE Reserved" 15 "SAE Reserved" 16 "SAE Reserved" 17 "SAE Reserved" 18 "Manufacturer specific active mode 1" 19 "Manufacturer specific active mode 2" 20 "Inverter active discharge mode" 21 "Inverter power down command mode" 22 "SAE Reserved" 23 "SAE Reserved" 24 "SAE Reserved" 25 "SAE Reserved" 26 "SAE Reserved" 27 "SAE Reserved" 28 "Manufacturer specific special mode 1" 29 "Manufacturer specific special mode 2" 30 "SAE Reserved" 31 "Don't Care/Take No Action" ;
VAL_ 2364672766 MtrGen4InvertCtrlLmtsRqOverrdMde 0 "Limits not currently being requested in this PGN" 1 "Torque Limits Mode" 2 "Speed Limits Mode" 3 "DC Side Voltage Limits Mode" 4 "DC Side Current Limits Mode" 5 "DC Side Power Limits Mode" 6 "Mechanical Power Limits Mode" 7 "SAE Reserved" 14 "Error" 15 "Not Requests / Take No Action" ;
VAL_ 2364672766 MtrGen4InvertCtrlSetpointMdeRq 0 "Power On" 1 "SAE Reserved" 2 "Standby" 3 "SAE Reserved" 4 "SAE Reserved" 5 "Manufacturer specific passive mode 1" 6 "Manufacturer specific passive mode 2" 7 "Enable Torque Control Mode" 8 "Enable Speed Control Mode" 9 "Enable DC Side Voltage Mode" 10 "Enable DC Side Current Mode" 11 "Enable DC Power Control Mode" 12 "Enable Mechanical Power Control Mode" 13 "SAE Reserved" 14 "SAE Reserved" 15 "SAE Reserved" 16 "SAE Reserved" 17 "SAE Reserved" 18 "Manufacturer specific active mode 1" 19 "Manufacturer specific active mode 2" 20 "Inverter active discharge mode" 21 "Inverter power down command mode" 22 "SAE Reserved" 23 "SAE Reserved" 24 "SAE Reserved" 25 "SAE Reserved" 26 "SAE Reserved" 27 "SAE Reserved" 28 "Manufacturer specific special mode 1" 29 "Manufacturer specific special mode 2" 30 "SAE Reserved" 31 "Don't Care/Take No Action" ;
VAL_ 2364673278 MtrGen5InvertCtrlLmtsRqOverrdMde 0 "Limits not currently being requested in this PGN" 1 "Torque Limits Mode" 2 "Speed Limits Mode" 3 "DC Side Voltage Limits Mode" 4 "DC Side Current Limits Mode" 5 "DC Side Power Limits Mode" 6 "Mechanical Power Limits Mode" 7 "SAE Reserved" 14 "Error" 15 "Not Requests / Take No Action" ;
VAL_ 2364673278 MtrGen5InvertCtrlSetpointMdeRq 0 "Power On" 1 "SAE Reserved" 2 "Standby" 3 "SAE Reserved" 4 "SAE Reserved" 5 "Manufacturer specific passive mode 1" 6 "Manufacturer specific passive mode 2" 7 "Enable Torque Control Mode" 8 "Enable Speed Control Mode" 9 "Enable DC Side Voltage Mode" 10 "Enable DC Side Current Mode" 11 "Enable DC Power Control Mode" 12 "Enable Mechanical Power Control Mode" 13 "SAE Reserved" 14 "SAE Reserved" 15 "SAE Reserved" 16 "SAE Reserved" 17 "SAE Reserved" 18 "Manufacturer specific active mode 1" 19 "Manufacturer specific active mode 2" 20 "Inverter active discharge mode" 21 "Inverter power down command mode" 22 "SAE Reserved" 23 "SAE Reserved" 24 "SAE Reserved" 25 "SAE Reserved" 26 "SAE Reserved" 27 "SAE Reserved" 28 "Manufacturer specific special mode 1" 29 "Manufacturer specific special mode 2" 30 "SAE Reserved" 31 "Don't Care/Take No Action" ;
VAL_ 2364673790 MtrGen6InvertCtrlLmtsRqOverrdMde 0 "Limits not currently being requested in this PGN" 1 "Torque Limits Mode" 2 "Speed Limits Mode" 3 "DC Side Voltage Limits Mode" 4 "DC Side Current Limits Mode" 5 "DC Side Power Limits Mode" 6 "Mechanical Power Limits Mode" 7 "SAE Reserved" 14 "Error" 15 "Not Requests / Take No Action" ;
VAL_ 2364673790 MtrGen6InvertCtrlSetpointMdeRq 0 "Power On" 1 "SAE Reserved" 2 "Standby" 3 "SAE Reserved" 4 "SAE Reserved" 5 "Manufacturer specific passive mode 1" 6 "Manufacturer specific passive mode 2" 7 "Enable Torque Control Mode" 8 "Enable Speed Control Mode" 9 "Enable DC Side Voltage Mode" 10 "Enable DC Side Current Mode" 11 "Enable DC Power Control Mode" 12 "Enable Mechanical Power Control Mode" 13 "SAE Reserved" 14 "SAE Reserved" 15 "SAE Reserved" 16 "SAE Reserved" 17 "SAE Reserved" 18 "Manufacturer specific active mode 1" 19 "Manufacturer specific active mode 2" 20 "Inverter active discharge mode" 21 "Inverter power down command mode" 22 "SAE Reserved" 23 "SAE Reserved" 24 "SAE Reserved" 25 "SAE Reserved" 26 "SAE Reserved" 27 "SAE Reserved" 28 "Manufacturer specific special mode 1" 29 "Manufacturer specific special mode 2" 30 "SAE Reserved" 31 "Don't Care/Take No Action" ;
